VERSION "dbc-export 1 2026.26.6.5"

NS_ :

BS_:

BU_: APP APS BMS CC CMP CMPD CP DAS DI DIF DIR EPBL EPBR EVSE FC GTW HCML HCMR HVP ICR PCS PCS2 PLG PM PMF PMR PTC SCCM SCM SCS SDCR TAS UMC V2G VC VCBATT VCBATT0 VCBATT1 VCBATT2 VCFRONT VCFRONT1 VCFRONT2 VCLEFT VCRIGHT VCSEAT2L VCSEAT2R VCSEC

BO_ 864 VCLEFT_alertMatrix: 8 VCLEFT
 SG_ VCLEFT_matrixIndex M : 0|4@1+ (1,0) [0|15] "" Vector__XXX
 SG_ VCLEFT_a001_WatchdogReset m0 : 4|1@1+ (1,0) [0|1] "" Vector__XXX
 SG_ VCLEFT_a002_PowerLossReset m0 : 5|1@1+ (1,0) [0|1] "" Vector__XXX
 SG_ VCLEFT_a003_SWAssertion m0 : 6|1@1+ (1,0) [0|1] "" Vector__XXX
 SG_ VCLEFT_a005_CANTXError m0 : 8|1@1+ (1,0) [0|1] "" Vector__XXX
 SG_ VCLEFT_a006_CANTX_cyclicError m0 : 9|1@1+ (1,0) [0|1] "" Vector__XXX
 SG_ VCLEFT_a010_ExtSupplyVoltError m0 : 13|1@1+ (1,0) [0|1] "" Vector__XXX
 SG_ VCLEFT_a012_CPUReset m0 : 15|1@1+ (1,0) [0|1] "" Vector__XXX
 SG_ VCLEFT_a013_AlertManagerFault m0 : 16|1@1+ (1,0) [0|1] "" Vector__XXX
 SG_ VCLEFT_a015_NVMMError m0 : 18|1@1+ (1,0) [0|1] "" Vector__XXX
 SG_ VCLEFT_a016_NVMMRecordError m0 : 19|1@1+ (1,0) [0|1] "" Vector__XXX
 SG_ VCLEFT_a017_NVMMStatusDbg m0 : 20|1@1+ (1,0) [0|1] "" Vector__XXX
 SG_ VCLEFT_a021_TaskSchedulerError m0 : 24|1@1+ (1,0) [0|1] "" Vector__XXX
 SG_ VCLEFT_a022_TaskInitError m0 : 25|1@1+ (1,0) [0|1] "" Vector__XXX
 SG_ VCLEFT_a029_CoreDump m0 : 32|1@1+ (1,0) [0|1] "" Vector__XXX
 SG_ VCLEFT_a030_ECULogUploadRequest m0 : 33|1@1+ (1,0) [0|1] "" Vector__XXX
 SG_ VCLEFT_a031_UDSActive m0 : 34|1@1+ (1,0) [0|1] "" Vector__XXX
 SG_ VCLEFT_a041_HighCPULoad m0 : 44|1@1+ (1,0) [0|1] "" Vector__XXX
 SG_ VCLEFT_a042_HighStackUsage m0 : 45|1@1+ (1,0) [0|1] "" Vector__XXX
 SG_ VCLEFT_a043_Task1msError m0 : 46|1@1+ (1,0) [0|1] "" Vector__XXX
 SG_ VCLEFT_a044_Task10msError m0 : 47|1@1+ (1,0) [0|1] "" Vector__XXX
 SG_ VCLEFT_a045_Task100msError m0 : 48|1@1+ (1,0) [0|1] "" Vector__XXX
 SG_ VCLEFT_a046_Task1000msError m0 : 49|1@1+ (1,0) [0|1] "" Vector__XXX
 SG_ VCLEFT_a057_HVP_MIA m0 : 60|1@1+ (1,0) [0|1] "" Vector__XXX
 SG_ VCLEFT_a058_inputRHighSyncDebug m0 : 61|1@1+ (1,0) [0|1] "" Vector__XXX
 SG_ VCLEFT_a059_inputResistanceHigh m0 : 62|1@1+ (1,0) [0|1] "" Vector__XXX
 SG_ VCLEFT_a060_engineeringBuild m0 : 63|1@1+ (1,0) [0|1] "" Vector__XXX
 SG_ VCLEFT_a061_XCPConnected m1 : 4|1@1+ (1,0) [0|1] "" Vector__XXX
 SG_ VCLEFT_a062_XCPWasConnected m1 : 5|1@1+ (1,0) [0|1] "" Vector__XXX
 SG_ VCLEFT_a063_SwitchFault m1 : 6|1@1+ (1,0) [0|1] "" Vector__XXX
 SG_ VCLEFT_a064_busSleepReqTimeout m1 : 7|1@1+ (1,0) [0|1] "" Vector__XXX
 SG_ VCLEFT_a065_emiosIsrRateLimitedD m1 : 8|1@1+ (1,0) [0|1] "" Vector__XXX
 SG_ VCLEFT_a066_emiosIsrShortPeriodD m1 : 9|1@1+ (1,0) [0|1] "" Vector__XXX
 SG_ VCLEFT_a082_VCRIGHT_IPC_MIA m1 : 25|1@1+ (1,0) [0|1] "" Vector__XXX
 SG_ VCLEFT_a083_VCLEFT_IPC_MIA m1 : 26|1@1+ (1,0) [0|1] "" Vector__XXX
 SG_ VCLEFT_a084_TPMS_MIA m1 : 27|1@1+ (1,0) [0|1] "" Vector__XXX
 SG_ VCLEFT_a085_CCCM_MIA m1 : 28|1@1+ (1,0) [0|1] "" Vector__XXX
 SG_ VCLEFT_a086_VCBATT_MIA m1 : 29|1@1+ (1,0) [0|1] "" Vector__XXX
 SG_ VCLEFT_a087_DIREL_MIA m1 : 30|1@1+ (1,0) [0|1] "" Vector__XXX
 SG_ VCLEFT_a088_DIRER_MIA m1 : 31|1@1+ (1,0) [0|1] "" Vector__XXX
 SG_ VCLEFT_a089_IBST_MIA m1 : 32|1@1+ (1,0) [0|1] "" Vector__XXX
 SG_ VCLEFT_a090_APS_MIA m1 : 33|1@1+ (1,0) [0|1] "" Vector__XXX
 SG_ VCLEFT_a091_CMPD_MIA m1 : 34|1@1+ (1,0) [0|1] "" Vector__XXX
 SG_ VCLEFT_a092_VCSEATD_MIA m1 : 35|1@1+ (1,0) [0|1] "" Vector__XXX
 SG_ VCLEFT_a093_VCSEATP_MIA m1 : 36|1@1+ (1,0) [0|1] "" Vector__XXX
 SG_ VCLEFT_a094_EPAS3P_MIA m1 : 37|1@1+ (1,0) [0|1] "" Vector__XXX
 SG_ VCLEFT_a095_CHG_MIA m1 : 38|1@1+ (1,0) [0|1] "" Vector__XXX
 SG_ VCLEFT_a096_OCS1P_MIA m1 : 39|1@1+ (1,0) [0|1] "" Vector__XXX
 SG_ VCLEFT_a097_CMP_MIA m1 : 40|1@1+ (1,0) [0|1] "" Vector__XXX
 SG_ VCLEFT_a098_DIR_MIA m1 : 41|1@1+ (1,0) [0|1] "" Vector__XXX
 SG_ VCLEFT_a099_PARK_MIA m1 : 42|1@1+ (1,0) [0|1] "" Vector__XXX
 SG_ VCLEFT_a100_CANbus_MIA m1 : 43|1@1+ (1,0) [0|1] "" Vector__XXX
 SG_ VCLEFT_a101_PM_MIA m1 : 44|1@1+ (1,0) [0|1] "" Vector__XXX
 SG_ VCLEFT_a102_PTC_MIA m1 : 45|1@1+ (1,0) [0|1] "" Vector__XXX
 SG_ VCLEFT_a103_CP_MIA m1 : 46|1@1+ (1,0) [0|1] "" Vector__XXX
 SG_ VCLEFT_a104_DAS_MIA m1 : 47|1@1+ (1,0) [0|1] "" Vector__XXX
 SG_ VCLEFT_a105_TAS_MIA m1 : 48|1@1+ (1,0) [0|1] "" Vector__XXX
 SG_ VCLEFT_a106_PCS_MIA m1 : 49|1@1+ (1,0) [0|1] "" Vector__XXX
 SG_ VCLEFT_a107_BMS_MIA m1 : 50|1@1+ (1,0) [0|1] "" Vector__XXX
 SG_ VCLEFT_a108_DIF_MIA m1 : 51|1@1+ (1,0) [0|1] "" Vector__XXX
 SG_ VCLEFT_a109_RCM_MIA m1 : 52|1@1+ (1,0) [0|1] "" Vector__XXX
 SG_ VCLEFT_a110_GTW_MIA m1 : 53|1@1+ (1,0) [0|1] "" Vector__XXX
 SG_ VCLEFT_a111_EPBR_MIA m1 : 54|1@1+ (1,0) [0|1] "" Vector__XXX
 SG_ VCLEFT_a112_EPBL_MIA m1 : 55|1@1+ (1,0) [0|1] "" Vector__XXX
 SG_ VCLEFT_a113_UI_MIA m1 : 56|1@1+ (1,0) [0|1] "" Vector__XXX
 SG_ VCLEFT_a114_ESP_MIA m1 : 57|1@1+ (1,0) [0|1] "" Vector__XXX
 SG_ VCLEFT_a115_VCSEC_MIA m1 : 58|1@1+ (1,0) [0|1] "" Vector__XXX
 SG_ VCLEFT_a116_VCRIGHT_MIA m1 : 59|1@1+ (1,0) [0|1] "" Vector__XXX
 SG_ VCLEFT_a117_VCLEFT_MIA m1 : 60|1@1+ (1,0) [0|1] "" Vector__XXX
 SG_ VCLEFT_a118_VCFRONT_MIA m1 : 61|1@1+ (1,0) [0|1] "" Vector__XXX
 SG_ VCLEFT_a119_SCCM_MIA m1 : 62|1@1+ (1,0) [0|1] "" Vector__XXX
 SG_ VCLEFT_a120_DI_DRIVE_MIA m1 : 63|1@1+ (1,0) [0|1] "" Vector__XXX
 SG_ VCLEFT_a121_ETC_MIA m2 : 4|1@1+ (1,0) [0|1] "" Vector__XXX
 SG_ VCLEFT_a122_ICR_MIA m2 : 5|1@1+ (1,0) [0|1] "" Vector__XXX
 SG_ VCLEFT_a123_AID_MIA m2 : 6|1@1+ (1,0) [0|1] "" Vector__XXX
 SG_ VCLEFT_a124_BB_MIA m2 : 7|1@1+ (1,0) [0|1] "" Vector__XXX
 SG_ VCLEFT_a125_RCU_MIA m2 : 8|1@1+ (1,0) [0|1] "" Vector__XXX
 SG_ VCLEFT_a129_blowerICLatchFault m2 : 12|1@1+ (1,0) [0|1] "" Vector__XXX
 SG_ VCLEFT_a130_blowerICWarning m2 : 13|1@1+ (1,0) [0|1] "" Vector__XXX
 SG_ VCLEFT_a131_blowerICTransFault m2 : 14|1@1+ (1,0) [0|1] "" Vector__XXX
 SG_ VCLEFT_a132_blowerSoftStall m2 : 15|1@1+ (1,0) [0|1] "" Vector__XXX
 SG_ VCLEFT_a133_blowerLowRPMCBang m2 : 16|1@1+ (1,0) [0|1] "" Vector__XXX
 SG_ VCLEFT_a134_SteerColUpDownUnCal m2 : 17|1@1+ (1,0) [0|1] "" Vector__XXX
 SG_ VCLEFT_a135_SteerColInOutUnCal m2 : 18|1@1+ (1,0) [0|1] "" Vector__XXX
 SG_ VCLEFT_a136_brakeSwitchMismatch m2 : 19|1@1+ (1,0) [0|1] "" Vector__XXX
 SG_ VCLEFT_a137_VCSECPowerCycled m2 : 20|1@1+ (1,0) [0|1] "" Vector__XXX
 SG_ VCLEFT_a138_consoleDoorAssist m2 : 21|1@1+ (1,0) [0|1] "" Vector__XXX
 SG_ VCLEFT_a139_BLERearPowerCycled m2 : 22|1@1+ (1,0) [0|1] "" Vector__XXX
 SG_ VCLEFT_a140_BLELeftPowerCycled m2 : 23|1@1+ (1,0) [0|1] "" Vector__XXX
 SG_ VCLEFT_a141_12VAuxPowerTrip m2 : 24|1@1+ (1,0) [0|1] "" Vector__XXX
 SG_ VCLEFT_a143_mirrorManuallyFolded m2 : 26|1@1+ (1,0) [0|1] "" Vector__XXX
 SG_ VCLEFT_a145_brakeSwitchStuck m2 : 28|1@1+ (1,0) [0|1] "" Vector__XXX
 SG_ VCLEFT_a148_brakePressInputMisma m2 : 31|1@1+ (1,0) [0|1] "" Vector__XXX
 SG_ VCLEFT_a150_windowPinchFront m2 : 33|1@1+ (1,0) [0|1] "" Vector__XXX
 SG_ VCLEFT_a151_windowPinchRear m2 : 34|1@1+ (1,0) [0|1] "" Vector__XXX
 SG_ VCLEFT_a152_windowUncalFront m2 : 35|1@1+ (1,0) [0|1] "" Vector__XXX
 SG_ VCLEFT_a153_windowUncalRear m2 : 36|1@1+ (1,0) [0|1] "" Vector__XXX
 SG_ VCLEFT_a154_windowThermalFront m2 : 37|1@1+ (1,0) [0|1] "" Vector__XXX
 SG_ VCLEFT_a155_windowThermalRear m2 : 38|1@1+ (1,0) [0|1] "" Vector__XXX
 SG_ VCLEFT_a156_windowNoInputFront m2 : 39|1@1+ (1,0) [0|1] "" Vector__XXX
 SG_ VCLEFT_a157_windowNoInputRear m2 : 40|1@1+ (1,0) [0|1] "" Vector__XXX
 SG_ VCLEFT_a158_windowPinchOverideF m2 : 41|1@1+ (1,0) [0|1] "" Vector__XXX
 SG_ VCLEFT_a159_windowPinchOverideR m2 : 42|1@1+ (1,0) [0|1] "" Vector__XXX
 SG_ VCLEFT_a160_windowUndercurrentF m2 : 43|1@1+ (1,0) [0|1] "" Vector__XXX
 SG_ VCLEFT_a161_windowUndercurrentR m2 : 44|1@1+ (1,0) [0|1] "" Vector__XXX
 SG_ VCLEFT_a162_windowEncoderStallF m2 : 45|1@1+ (1,0) [0|1] "" Vector__XXX
 SG_ VCLEFT_a163_windowEncoderStallR m2 : 46|1@1+ (1,0) [0|1] "" Vector__XXX
 SG_ VCLEFT_a164_windowFactoryTest m2 : 47|1@1+ (1,0) [0|1] "" Vector__XXX
 SG_ VCLEFT_a165_windowFactoryTest2 m2 : 48|1@1+ (1,0) [0|1] "" Vector__XXX
 SG_ VCLEFT_a166_windowDebug m2 : 49|1@1+ (1,0) [0|1] "" Vector__XXX
 SG_ VCLEFT_a167_windowDebugPinchF m2 : 50|1@1+ (1,0) [0|1] "" Vector__XXX
 SG_ VCLEFT_a168_windowDebugPinchR m2 : 51|1@1+ (1,0) [0|1] "" Vector__XXX
 SG_ VCLEFT_a169_windowCurrentPeakF m2 : 52|1@1+ (1,0) [0|1] "" Vector__XXX
 SG_ VCLEFT_a170_windowCurrentPeakR m2 : 53|1@1+ (1,0) [0|1] "" Vector__XXX
 SG_ VCLEFT_a172_SPI_MIA m2 : 55|1@1+ (1,0) [0|1] "" Vector__XXX
 SG_ VCLEFT_a173_windowBtnDoorOpen m2 : 56|1@1+ (1,0) [0|1] "" Vector__XXX
 SG_ VCLEFT_a175_windowSealDefectFron m2 : 58|1@1+ (1,0) [0|1] "" Vector__XXX
 SG_ VCLEFT_a176_windowSealDefectRear m2 : 59|1@1+ (1,0) [0|1] "" Vector__XXX
 SG_ VCLEFT_a180_frontDoorLatchRehome m2 : 63|1@1+ (1,0) [0|1] "" Vector__XXX
 SG_ VCLEFT_a181_rearDoorLatchRehome m3 : 4|1@1+ (1,0) [0|1] "" Vector__XXX
 SG_ VCLEFT_a182_emergencyLatchRel m3 : 5|1@1+ (1,0) [0|1] "" Vector__XXX
 SG_ VCLEFT_a183_doorStateFactoryTest m3 : 6|1@1+ (1,0) [0|1] "" Vector__XXX
 SG_ VCLEFT_a185_summonAborted m3 : 8|1@1+ (1,0) [0|1] "" Vector__XXX
 SG_ VCLEFT_a186_latchReleaseFailedF m3 : 9|1@1+ (1,0) [0|1] "" Vector__XXX
 SG_ VCLEFT_a187_latchReleaseFailedR m3 : 10|1@1+ (1,0) [0|1] "" Vector__XXX
 SG_ VCLEFT_a188_latchUnableToRearmF m3 : 11|1@1+ (1,0) [0|1] "" Vector__XXX
 SG_ VCLEFT_a189_latchUnableToRearmR m3 : 12|1@1+ (1,0) [0|1] "" Vector__XXX
 SG_ VCLEFT_a190_eFuseMgmtVbatFused m3 : 13|1@1+ (1,0) [0|1] "" Vector__XXX
 SG_ VCLEFT_a191_TLCOvercurrent m3 : 14|1@1+ (1,0) [0|1] "" Vector__XXX
 SG_ VCLEFT_a192_blowerGeneralFault m3 : 15|1@1+ (1,0) [0|1] "" Vector__XXX
 SG_ VCLEFT_a193_blowerMIA m3 : 16|1@1+ (1,0) [0|1] "" Vector__XXX
 SG_ VCLEFT_a194_blowerUnidentified m3 : 17|1@1+ (1,0) [0|1] "" Vector__XXX
 SG_ VCLEFT_a195_blowerIdentification m3 : 18|1@1+ (1,0) [0|1] "" Vector__XXX
 SG_ VCLEFT_a196_VEHCANOverterminate m3 : 19|1@1+ (1,0) [0|1] "" Vector__XXX
 SG_ VCLEFT_a197_VEHCANUndertrminate m3 : 20|1@1+ (1,0) [0|1] "" Vector__XXX
 SG_ VCLEFT_a200_motorPhantomEncoder m3 : 23|1@1+ (1,0) [0|1] "" Vector__XXX
 SG_ VCLEFT_a201_motorDutyEncDisabl m3 : 24|1@1+ (1,0) [0|1] "" Vector__XXX
 SG_ VCLEFT_a202_epbmUnderIStatic m3 : 25|1@1+ (1,0) [0|1] "" Vector__XXX
 SG_ VCLEFT_a203_epbmOverIStatic m3 : 26|1@1+ (1,0) [0|1] "" Vector__XXX
 SG_ VCLEFT_a204_epbmUnderIDyn m3 : 27|1@1+ (1,0) [0|1] "" Vector__XXX
 SG_ VCLEFT_a205_epbmOverIDyn m3 : 28|1@1+ (1,0) [0|1] "" Vector__XXX
 SG_ VCLEFT_a206_epbWrongDirection m3 : 29|1@1+ (1,0) [0|1] "" Vector__XXX
 SG_ VCLEFT_a207_epbmEnableWrong m3 : 30|1@1+ (1,0) [0|1] "" Vector__XXX
 SG_ VCLEFT_a208_epbFaulted m3 : 31|1@1+ (1,0) [0|1] "" Vector__XXX
 SG_ VCLEFT_a209_epbStateMisTime m3 : 32|1@1+ (1,0) [0|1] "" Vector__XXX
 SG_ VCLEFT_a210_epbStateTime m3 : 33|1@1+ (1,0) [0|1] "" Vector__XXX
 SG_ VCLEFT_a211_epbmUnderIStaticNew m3 : 34|1@1+ (1,0) [0|1] "" Vector__XXX
 SG_ VCLEFT_a212_epbmOverIStaticNew m3 : 35|1@1+ (1,0) [0|1] "" Vector__XXX
 SG_ VCLEFT_a213_epbmUnderIDynNew m3 : 36|1@1+ (1,0) [0|1] "" Vector__XXX
 SG_ VCLEFT_a214_epbmOverIDynNew m3 : 37|1@1+ (1,0) [0|1] "" Vector__XXX
 SG_ VCLEFT_a215_currentDesyncWarning m3 : 38|1@1+ (1,0) [0|1] "" Vector__XXX
 SG_ VCLEFT_a216_SPI_MIA_debugData1 m3 : 39|1@1+ (1,0) [0|1] "" Vector__XXX
 SG_ VCLEFT_a217_SPI_MIA_debugData2 m3 : 40|1@1+ (1,0) [0|1] "" Vector__XXX
 SG_ VCLEFT_a218_motorDriverFault m3 : 41|1@1+ (1,0) [0|1] "" Vector__XXX
 SG_ VCLEFT_a219_motorCurrentDropout m3 : 42|1@1+ (1,0) [0|1] "" Vector__XXX
 SG_ VCLEFT_a220_reverseLightFaultUse m3 : 43|1@1+ (1,0) [0|1] "" Vector__XXX
 SG_ VCLEFT_a221_hardwareLoadshedTrig m3 : 44|1@1+ (1,0) [0|1] "" Vector__XXX
 SG_ VCLEFT_a223_VCBATT1_MIA m3 : 46|1@1+ (1,0) [0|1] "" Vector__XXX
 SG_ VCLEFT_a224_seatEncStallTrack m3 : 47|1@1+ (1,0) [0|1] "" Vector__XXX
 SG_ VCLEFT_a225_seatEncStallBack m3 : 48|1@1+ (1,0) [0|1] "" Vector__XXX
 SG_ VCLEFT_a226_seatEncStallTilt m3 : 49|1@1+ (1,0) [0|1] "" Vector__XXX
 SG_ VCLEFT_a227_seatEncStallLift m3 : 50|1@1+ (1,0) [0|1] "" Vector__XXX
 SG_ VCLEFT_a228_seatEncOverTrack m3 : 51|1@1+ (1,0) [0|1] "" Vector__XXX
 SG_ VCLEFT_a229_seatEncOverBack m3 : 52|1@1+ (1,0) [0|1] "" Vector__XXX
 SG_ VCLEFT_a230_seatEncOverTilt m3 : 53|1@1+ (1,0) [0|1] "" Vector__XXX
 SG_ VCLEFT_a231_seatEncOverLift m3 : 54|1@1+ (1,0) [0|1] "" Vector__XXX
 SG_ VCLEFT_a232_seatCurrUnderTrack m3 : 55|1@1+ (1,0) [0|1] "" Vector__XXX
 SG_ VCLEFT_a233_seatCurrUnderBack m3 : 56|1@1+ (1,0) [0|1] "" Vector__XXX
 SG_ VCLEFT_a234_seatCurrUnderTilt m3 : 57|1@1+ (1,0) [0|1] "" Vector__XXX
 SG_ VCLEFT_a235_seatCurrUnderLift m3 : 58|1@1+ (1,0) [0|1] "" Vector__XXX
 SG_ VCLEFT_a236_lumbarOverPresA m3 : 59|1@1+ (1,0) [0|1] "" Vector__XXX
 SG_ VCLEFT_a237_lumbarOverPresB m3 : 60|1@1+ (1,0) [0|1] "" Vector__XXX
 SG_ VCLEFT_a238_lumbarValveMIA m3 : 61|1@1+ (1,0) [0|1] "" Vector__XXX
 SG_ VCLEFT_a239_seatHeatIFront m3 : 62|1@1+ (1,0) [0|1] "" Vector__XXX
 SG_ VCLEFT_a240_seatHeatShortFront m3 : 63|1@1+ (1,0) [0|1] "" Vector__XXX
 SG_ VCLEFT_a241_seatHeatMIAFront m4 : 4|1@1+ (1,0) [0|1] "" Vector__XXX
 SG_ VCLEFT_a242_seatHeatIRearL m4 : 5|1@1+ (1,0) [0|1] "" Vector__XXX
 SG_ VCLEFT_a243_seatHeatShortRearL m4 : 6|1@1+ (1,0) [0|1] "" Vector__XXX
 SG_ VCLEFT_a244_seatHeatMIARearL m4 : 7|1@1+ (1,0) [0|1] "" Vector__XXX
 SG_ VCLEFT_a245_seatHeatIRearC m4 : 8|1@1+ (1,0) [0|1] "" Vector__XXX
 SG_ VCLEFT_a246_seatHeatShortRearC m4 : 9|1@1+ (1,0) [0|1] "" Vector__XXX
 SG_ VCLEFT_a247_seatHeatMIARearC m4 : 10|1@1+ (1,0) [0|1] "" Vector__XXX
 SG_ VCLEFT_a248_seatHeatIRearR m4 : 11|1@1+ (1,0) [0|1] "" Vector__XXX
 SG_ VCLEFT_a249_seatHeatShortRearR m4 : 12|1@1+ (1,0) [0|1] "" Vector__XXX
 SG_ VCLEFT_a250_seatHeatMIARearR m4 : 13|1@1+ (1,0) [0|1] "" Vector__XXX
 SG_ VCLEFT_a251_seatUncalTrack m4 : 14|1@1+ (1,0) [0|1] "" Vector__XXX
 SG_ VCLEFT_a252_seatUncalBack m4 : 15|1@1+ (1,0) [0|1] "" Vector__XXX
 SG_ VCLEFT_a253_seatUncalTilt m4 : 16|1@1+ (1,0) [0|1] "" Vector__XXX
 SG_ VCLEFT_a254_seatUncalLift m4 : 17|1@1+ (1,0) [0|1] "" Vector__XXX
 SG_ VCLEFT_a256_nxppca9539Fault m4 : 19|1@1+ (1,0) [0|1] "" Vector__XXX
 SG_ VCLEFT_a257_USBMIA m4 : 20|1@1+ (1,0) [0|1] "" Vector__XXX
 SG_ VCLEFT_a259_latchDisarmDelayF m4 : 22|1@1+ (1,0) [0|1] "" Vector__XXX
 SG_ VCLEFT_a260_latchDisarmDelayR m4 : 23|1@1+ (1,0) [0|1] "" Vector__XXX
 SG_ VCLEFT_a261_emergencyLatchRelRea m4 : 24|1@1+ (1,0) [0|1] "" Vector__XXX
 SG_ VCLEFT_a263_seatTrackStallDebug m4 : 26|1@1+ (1,0) [0|1] "" Vector__XXX
 SG_ VCLEFT_a264_seatBackStallDebug m4 : 27|1@1+ (1,0) [0|1] "" Vector__XXX
 SG_ VCLEFT_a265_seatTiltStallDebug m4 : 28|1@1+ (1,0) [0|1] "" Vector__XXX
 SG_ VCLEFT_a266_seatLiftStallDebug m4 : 29|1@1+ (1,0) [0|1] "" Vector__XXX
 SG_ VCLEFT_a267_seatTrackHCEncStlDbg m4 : 30|1@1+ (1,0) [0|1] "" Vector__XXX
 SG_ VCLEFT_a268_seatBackHCEncStlDbg m4 : 31|1@1+ (1,0) [0|1] "" Vector__XXX
 SG_ VCLEFT_a269_seatTiltHCEncStlDbg m4 : 32|1@1+ (1,0) [0|1] "" Vector__XXX
 SG_ VCLEFT_a270_seatLiftHCEncStlDbg m4 : 33|1@1+ (1,0) [0|1] "" Vector__XXX
 SG_ VCLEFT_a272_vhclPwrStateMsmtch m4 : 35|1@1+ (1,0) [0|1] "" Vector__XXX
 SG_ VCLEFT_a273_handleStuckActiveF m4 : 36|1@1+ (1,0) [0|1] "" Vector__XXX
 SG_ VCLEFT_a274_handleStuckActiveR m4 : 37|1@1+ (1,0) [0|1] "" Vector__XXX
 SG_ VCLEFT_a275_leftTurnLightFault m4 : 38|1@1+ (1,0) [0|1] "" Vector__XXX
 SG_ VCLEFT_a276_mirrorDebug m4 : 39|1@1+ (1,0) [0|1] "" Vector__XXX
 SG_ VCLEFT_a277_BLELeftUnderVoltage m4 : 40|1@1+ (1,0) [0|1] "" Vector__XXX
 SG_ VCLEFT_a278_BLERearUnderVoltage m4 : 41|1@1+ (1,0) [0|1] "" Vector__XXX
 SG_ VCLEFT_a279_VCSECUnderVoltage m4 : 42|1@1+ (1,0) [0|1] "" Vector__XXX
 SG_ VCLEFT_a280_latchDidNotDisarmF m4 : 43|1@1+ (1,0) [0|1] "" Vector__XXX
 SG_ VCLEFT_a281_latchDidNotDisarmR m4 : 44|1@1+ (1,0) [0|1] "" Vector__XXX
 SG_ VCLEFT_a282_latchUnexpectedArmF m4 : 45|1@1+ (1,0) [0|1] "" Vector__XXX
 SG_ VCLEFT_a283_latchUnexpectedArmR m4 : 46|1@1+ (1,0) [0|1] "" Vector__XXX
 SG_ VCLEFT_a284_blowerFbkSanity m4 : 47|1@1+ (1,0) [0|1] "" Vector__XXX
 SG_ VCLEFT_a285_blowerChipComms m4 : 48|1@1+ (1,0) [0|1] "" Vector__XXX
 SG_ VCLEFT_a286_windowSpeedInvalidF m4 : 49|1@1+ (1,0) [0|1] "" Vector__XXX
 SG_ VCLEFT_a287_windowSpeedInvalidR m4 : 50|1@1+ (1,0) [0|1] "" Vector__XXX
 SG_ VCLEFT_a288_handlePWMPeriodF m4 : 51|1@1+ (1,0) [0|1] "" Vector__XXX
 SG_ VCLEFT_a289_handlePWMPeriodR m4 : 52|1@1+ (1,0) [0|1] "" Vector__XXX
 SG_ VCLEFT_a290_occupancyFaultedFron m4 : 53|1@1+ (1,0) [0|1] "" Vector__XXX
 SG_ VCLEFT_a291_buckleFaultedFront m4 : 54|1@1+ (1,0) [0|1] "" Vector__XXX
 SG_ VCLEFT_a292_occupancyFaultedRear m4 : 55|1@1+ (1,0) [0|1] "" Vector__XXX
 SG_ VCLEFT_a293_occupancyFaultedRear m4 : 56|1@1+ (1,0) [0|1] "" Vector__XXX
 SG_ VCLEFT_a294_occupancyFaultedRear m4 : 57|1@1+ (1,0) [0|1] "" Vector__XXX
 SG_ VCLEFT_a295_buckleFaultedRearL m4 : 58|1@1+ (1,0) [0|1] "" Vector__XXX
 SG_ VCLEFT_a296_buckleFaultedRearC m4 : 59|1@1+ (1,0) [0|1] "" Vector__XXX
 SG_ VCLEFT_a297_seatBelowMinPumpTmp m4 : 60|1@1+ (1,0) [0|1] "" Vector__XXX
 SG_ VCLEFT_a299_swcMIA m4 : 62|1@1+ (1,0) [0|1] "" Vector__XXX
 SG_ VCLEFT_a300_swcUnderVoltage m4 : 63|1@1+ (1,0) [0|1] "" Vector__XXX
 SG_ VCLEFT_a301_swcOverVoltage m5 : 4|1@1+ (1,0) [0|1] "" Vector__XXX
 SG_ VCLEFT_a302_blowerGeneralFault m5 : 5|1@1+ (1,0) [0|1] "" Vector__XXX
 SG_ VCLEFT_a303_eFuseMgmtWindowLift m5 : 6|1@1+ (1,0) [0|1] "" Vector__XXX
 SG_ VCLEFT_a304_frontIntHandleUnexpe m5 : 7|1@1+ (1,0) [0|1] "" Vector__XXX
 SG_ VCLEFT_a305_rearIntHandleUnexpec m5 : 8|1@1+ (1,0) [0|1] "" Vector__XXX
 SG_ VCLEFT_a306_handleDisconnectedF m5 : 9|1@1+ (1,0) [0|1] "" Vector__XXX
 SG_ VCLEFT_a307_handleDisconnectedR m5 : 10|1@1+ (1,0) [0|1] "" Vector__XXX
 SG_ VCLEFT_a308_sirenMIA m5 : 11|1@1+ (1,0) [0|1] "" Vector__XXX
 SG_ VCLEFT_a309_brakeSwitchFaulted m5 : 12|1@1+ (1,0) [0|1] "" Vector__XXX
 SG_ VCLEFT_a310_mirrorFoldStall m5 : 13|1@1+ (1,0) [0|1] "" Vector__XXX
 SG_ VCLEFT_a311_leftBrakeLightFault m5 : 14|1@1+ (1,0) [0|1] "" Vector__XXX
 SG_ VCLEFT_a312_leftTailLightFault m5 : 15|1@1+ (1,0) [0|1] "" Vector__XXX
 SG_ VCLEFT_a313_leftFootwellLightFau m5 : 16|1@1+ (1,0) [0|1] "" Vector__XXX
 SG_ VCLEFT_a314_leftMapPocketLightFa m5 : 17|1@1+ (1,0) [0|1] "" Vector__XXX
 SG_ VCLEFT_a315_leftInteriorTrunkLig m5 : 18|1@1+ (1,0) [0|1] "" Vector__XXX
 SG_ VCLEFT_a316_mirrorPrematureFoldS m5 : 19|1@1+ (1,0) [0|1] "" Vector__XXX
 SG_ VCLEFT_a317_epbmLimpModeEnabled m5 : 20|1@1+ (1,0) [0|1] "" Vector__XXX
 SG_ VCLEFT_a318_trailerIncorrectConf m5 : 21|1@1+ (1,0) [0|1] "" Vector__XXX
 SG_ VCLEFT_a319_brakePressPrimaryInp m5 : 22|1@1+ (1,0) [0|1] "" Vector__XXX
 SG_ VCLEFT_a320_windowReportCrackedA m5 : 23|1@1+ (1,0) [0|1] "" Vector__XXX
 SG_ VCLEFT_a321_windowRezeroedDebugF m5 : 24|1@1+ (1,0) [0|1] "" Vector__XXX
 SG_ VCLEFT_a322_windowRezeroedDebugR m5 : 25|1@1+ (1,0) [0|1] "" Vector__XXX
 SG_ VCLEFT_a323_mirrorCalibrated m5 : 26|1@1+ (1,0) [0|1] "" Vector__XXX
 SG_ VCLEFT_a324_mirrorHeatFault m5 : 27|1@1+ (1,0) [0|1] "" Vector__XXX
 SG_ VCLEFT_a325_hghtSnsrUnplgdFL m5 : 28|1@1+ (1,0) [0|1] "" Vector__XXX
 SG_ VCLEFT_a326_hghtSnsrUnplgdRL m5 : 29|1@1+ (1,0) [0|1] "" Vector__XXX
 SG_ VCLEFT_a327_hghtSnsrFaultFL m5 : 30|1@1+ (1,0) [0|1] "" Vector__XXX
 SG_ VCLEFT_a328_hghtSnsrFaultRL m5 : 31|1@1+ (1,0) [0|1] "" Vector__XXX
 SG_ VCLEFT_a329_noRideHeightCalib m5 : 32|1@1+ (1,0) [0|1] "" Vector__XXX
 SG_ VCLEFT_a330_shortDropFailedF m5 : 33|1@1+ (1,0) [0|1] "" Vector__XXX
 SG_ VCLEFT_a331_shortDropFailedR m5 : 34|1@1+ (1,0) [0|1] "" Vector__XXX
 SG_ VCLEFT_a332_intrusionSensorMIA m5 : 35|1@1+ (1,0) [0|1] "" Vector__XXX
 SG_ VCLEFT_a333_overheadConsoleMIA m5 : 36|1@1+ (1,0) [0|1] "" Vector__XXX
 SG_ VCLEFT_a334_overheadConsoleInter m5 : 37|1@1+ (1,0) [0|1] "" Vector__XXX
 SG_ VCLEFT_a335_intrusionSensorInter m5 : 38|1@1+ (1,0) [0|1] "" Vector__XXX
 SG_ VCLEFT_a336_windowDropRevThermal m5 : 39|1@1+ (1,0) [0|1] "" Vector__XXX
 SG_ VCLEFT_a337_windowDropRevThermal m5 : 40|1@1+ (1,0) [0|1] "" Vector__XXX
 SG_ VCLEFT_a338_trailerLightControll m5 : 41|1@1+ (1,0) [0|1] "" Vector__XXX
 SG_ VCLEFT_a339_trailerLeftTurnLight m5 : 42|1@1+ (1,0) [0|1] "" Vector__XXX
 SG_ VCLEFT_a340_trailerRightTurnLigh m5 : 43|1@1+ (1,0) [0|1] "" Vector__XXX
 SG_ VCLEFT_a341_trailerLightFault m5 : 44|1@1+ (1,0) [0|1] "" Vector__XXX
 SG_ VCLEFT_a342_trailerLightControll m5 : 45|1@1+ (1,0) [0|1] "" Vector__XXX
 SG_ VCLEFT_a345_chargePortPowerCycli m5 : 48|1@1+ (1,0) [0|1] "" Vector__XXX
 SG_ VCLEFT_a346_eFuseMgmtVbatFused2 m5 : 49|1@1+ (1,0) [0|1] "" Vector__XXX
 SG_ VCLEFT_a347_nonContMonitorCleare m5 : 50|1@1+ (1,0) [0|1] "" Vector__XXX
 SG_ VCLEFT_a348_CPSleepOvercurrent m5 : 51|1@1+ (1,0) [0|1] "" Vector__XXX
 SG_ VCLEFT_a349_CPSleepUndervoltage m5 : 52|1@1+ (1,0) [0|1] "" Vector__XXX
 SG_ VCLEFT_a350_ensOutOfRange m5 : 53|1@1+ (1,0) [0|1] "" Vector__XXX
 SG_ VCLEFT_a351_debugLiftgateCurrent m5 : 54|1@1+ (1,0) [0|1] "" Vector__XXX
 SG_ VCLEFT_a352_liftgateClosingLatch m5 : 55|1@1+ (1,0) [0|1] "" Vector__XXX
 SG_ VCLEFT_a353_eFuseMgmtSteeringCol m5 : 56|1@1+ (1,0) [0|1] "" Vector__XXX
 SG_ VCLEFT_a354_eFuseMgmtLiftGate m5 : 57|1@1+ (1,0) [0|1] "" Vector__XXX
 SG_ VCLEFT_a355_liftgateUnexpectedSt m5 : 58|1@1+ (1,0) [0|1] "" Vector__XXX
 SG_ VCLEFT_a356_liftgateFactoryTest m5 : 59|1@1+ (1,0) [0|1] "" Vector__XXX
 SG_ VCLEFT_a357_liftgateUncalibrated m5 : 60|1@1+ (1,0) [0|1] "" Vector__XXX
 SG_ VCLEFT_a358_debugLiftgateCurrent m5 : 61|1@1+ (1,0) [0|1] "" Vector__XXX
 SG_ VCLEFT_a359_liftgateLatchExitNoP m5 : 62|1@1+ (1,0) [0|1] "" Vector__XXX
 SG_ VCLEFT_a360_detectedStationaryWh m5 : 63|1@1+ (1,0) [0|1] "" Vector__XXX
 SG_ VCLEFT_a361_stationaryThresholds m6 : 4|1@1+ (1,0) [0|1] "" Vector__XXX
 SG_ VCLEFT_a362_movingThresholdsInco m6 : 5|1@1+ (1,0) [0|1] "" Vector__XXX
 SG_ VCLEFT_a363_liftgateOpenAngleSet m6 : 6|1@1+ (1,0) [0|1] "" Vector__XXX
 SG_ VCLEFT_a365_pitchUnlatchDisabled m6 : 8|1@1+ (1,0) [0|1] "" Vector__XXX
 SG_ VCLEFT_a366_liftgateLatchEntryDB m6 : 9|1@1+ (1,0) [0|1] "" Vector__XXX
 SG_ VCLEFT_a370_seat2RowPitchUnlatch m6 : 13|1@1+ (1,0) [0|1] "" Vector__XXX
 SG_ VCLEFT_a371_seat2RowTrackUnlatch m6 : 14|1@1+ (1,0) [0|1] "" Vector__XXX
 SG_ VCLEFT_a372_seat2RowBackrestUnla m6 : 15|1@1+ (1,0) [0|1] "" Vector__XXX
 SG_ VCLEFT_a373_windowSwOpenReqInDog m6 : 16|1@1+ (1,0) [0|1] "" Vector__XXX
 SG_ VCLEFT_a374_trailerLightFaultMod m6 : 17|1@1+ (1,0) [0|1] "" Vector__XXX
 SG_ VCLEFT_a375_windowPinchOverrideN m6 : 18|1@1+ (1,0) [0|1] "" Vector__XXX
 SG_ VCLEFT_a376_seat2RowBridgeCurren m6 : 19|1@1+ (1,0) [0|1] "" Vector__XXX
 SG_ VCLEFT_a380_steerColThermalLimit m6 : 23|1@1+ (1,0) [0|1] "" Vector__XXX
 SG_ VCLEFT_a381_pitchEstimation1 m6 : 24|1@1+ (1,0) [0|1] "" Vector__XXX
 SG_ VCLEFT_a382_pitchEstimation2 m6 : 25|1@1+ (1,0) [0|1] "" Vector__XXX
 SG_ VCLEFT_a383_steerColInOutMotorSt m6 : 26|1@1+ (1,0) [0|1] "" Vector__XXX
 SG_ VCLEFT_a384_steerColUpDownMotorS m6 : 27|1@1+ (1,0) [0|1] "" Vector__XXX
 SG_ VCLEFT_a385_steerColInOutMotorUn m6 : 28|1@1+ (1,0) [0|1] "" Vector__XXX
 SG_ VCLEFT_a386_steerColUpDownMotorU m6 : 29|1@1+ (1,0) [0|1] "" Vector__XXX
 SG_ VCLEFT_a387_steerColInOutMotorEn m6 : 30|1@1+ (1,0) [0|1] "" Vector__XXX
 SG_ VCLEFT_a388_steerColUpDownMotorE m6 : 31|1@1+ (1,0) [0|1] "" Vector__XXX
 SG_ VCLEFT_a389_steerColInOutEncoder m6 : 32|1@1+ (1,0) [0|1] "" Vector__XXX
 SG_ VCLEFT_a390_steerColUpDownEncode m6 : 33|1@1+ (1,0) [0|1] "" Vector__XXX
 SG_ VCLEFT_a391_pitchEstimationImpla m6 : 34|1@1+ (1,0) [0|1] "" Vector__XXX
 SG_ VCLEFT_a392_pitchEstimationGPSIm m6 : 35|1@1+ (1,0) [0|1] "" Vector__XXX
 SG_ VCLEFT_a393_pitchEstimationNoGPS m6 : 36|1@1+ (1,0) [0|1] "" Vector__XXX
 SG_ VCLEFT_a394_swsTouchTooNegativeD m6 : 37|1@1+ (1,0) [0|1] "" Vector__XXX
 SG_ VCLEFT_a395_swsTouchAdcCheckFail m6 : 38|1@1+ (1,0) [0|1] "" Vector__XXX
 SG_ VCLEFT_a396_swsTouchStuckFault m6 : 39|1@1+ (1,0) [0|1] "" Vector__XXX
 SG_ VCLEFT_a397_swsTouchOutOfRangeFa m6 : 40|1@1+ (1,0) [0|1] "" Vector__XXX
 SG_ VCLEFT_a398_swsTouchNvmFault m6 : 41|1@1+ (1,0) [0|1] "" Vector__XXX
 SG_ VCLEFT_a399_swsTouchNoisyBaselin m6 : 42|1@1+ (1,0) [0|1] "" Vector__XXX
 SG_ VCLEFT_a400_swsTouchDebouncedPro m6 : 43|1@1+ (1,0) [0|1] "" Vector__XXX
 SG_ VCLEFT_a401_swsForceTestPatternV m6 : 44|1@1+ (1,0) [0|1] "" Vector__XXX
 SG_ VCLEFT_a402_swsForceOutOfRange m6 : 45|1@1+ (1,0) [0|1] "" Vector__XXX
 SG_ VCLEFT_a403_swsForceAdcCheckFail m6 : 46|1@1+ (1,0) [0|1] "" Vector__XXX
 SG_ VCLEFT_a404_swsForceI2cError m6 : 47|1@1+ (1,0) [0|1] "" Vector__XXX
 SG_ VCLEFT_a405_swsForceCalibrationF m6 : 48|1@1+ (1,0) [0|1] "" Vector__XXX
 SG_ VCLEFT_a406_swsForceParametersFa m6 : 49|1@1+ (1,0) [0|1] "" Vector__XXX
 SG_ VCLEFT_a407_swsForceNvmFault m6 : 50|1@1+ (1,0) [0|1] "" Vector__XXX
 SG_ VCLEFT_a408_swsForceTouchSensorF m6 : 51|1@1+ (1,0) [0|1] "" Vector__XXX
 SG_ VCLEFT_a409_swsScrollWheelPushFa m6 : 52|1@1+ (1,0) [0|1] "" Vector__XXX
 SG_ VCLEFT_a410_swsScrollWheelTiltFa m6 : 53|1@1+ (1,0) [0|1] "" Vector__XXX
 SG_ VCLEFT_a411_swsScrollWheelScroll m6 : 54|1@1+ (1,0) [0|1] "" Vector__XXX
 SG_ VCLEFT_a412_leftBrakeTailLightFa m6 : 55|1@1+ (1,0) [0|1] "" Vector__XXX
 SG_ VCLEFT_a413_undervoltageSelfTest m6 : 56|1@1+ (1,0) [0|1] "" Vector__XXX
 SG_ VCLEFT_a414_swsHapticMotorFault m6 : 57|1@1+ (1,0) [0|1] "" Vector__XXX
 SG_ VCLEFT_a415_swsMiscFault m6 : 58|1@1+ (1,0) [0|1] "" Vector__XXX
 SG_ VCLEFT_a416_fohmTouchAdcCheckFai m6 : 59|1@1+ (1,0) [0|1] "" Vector__XXX
 SG_ VCLEFT_a417_fohmTouchOutOfRangeF m6 : 60|1@1+ (1,0) [0|1] "" Vector__XXX
 SG_ VCLEFT_a418_fohmTouchVarianceFai m6 : 61|1@1+ (1,0) [0|1] "" Vector__XXX
 SG_ VCLEFT_a419_fohmTouchStuck m6 : 62|1@1+ (1,0) [0|1] "" Vector__XXX
 SG_ VCLEFT_a420_fohmTouchSensorsImpl m6 : 63|1@1+ (1,0) [0|1] "" Vector__XXX
 SG_ VCLEFT_a421_fohmForceOutOfRangeF m7 : 4|1@1+ (1,0) [0|1] "" Vector__XXX
 SG_ VCLEFT_a422_undervoltageSelfTest m7 : 5|1@1+ (1,0) [0|1] "" Vector__XXX
 SG_ VCLEFT_a423_fohmForceI2cError m7 : 6|1@1+ (1,0) [0|1] "" Vector__XXX
 SG_ VCLEFT_a424_fohmAmberLEDFault m7 : 7|1@1+ (1,0) [0|1] "" Vector__XXX
 SG_ VCLEFT_a425_fohmVanityPowerSuppl m7 : 8|1@1+ (1,0) [0|1] "" Vector__XXX
 SG_ VCLEFT_a426_seatAbuseMotorWarn m7 : 9|1@1+ (1,0) [0|1] "" Vector__XXX
 SG_ VCLEFT_a427_seatAbuseMotorStop m7 : 10|1@1+ (1,0) [0|1] "" Vector__XXX
 SG_ VCLEFT_a428_seatAbuseBufferWarn m7 : 11|1@1+ (1,0) [0|1] "" Vector__XXX
 SG_ VCLEFT_a429_seatAbuseBufferFull m7 : 12|1@1+ (1,0) [0|1] "" Vector__XXX
 SG_ VCLEFT_a430_fohmRearDomeLightPow m7 : 13|1@1+ (1,0) [0|1] "" Vector__XXX
 SG_ VCLEFT_a431_fohmVbatFault m7 : 14|1@1+ (1,0) [0|1] "" Vector__XXX
 SG_ VCLEFT_a432_fohmMiscFault m7 : 15|1@1+ (1,0) [0|1] "" Vector__XXX
 SG_ VCLEFT_a433_fohmForceCalibration m7 : 16|1@1+ (1,0) [0|1] "" Vector__XXX
 SG_ VCLEFT_a434_swsScrollWheelPushDa m7 : 17|1@1+ (1,0) [0|1] "" Vector__XXX
 SG_ VCLEFT_a435_swsNoReasonTouchFaul m7 : 18|1@1+ (1,0) [0|1] "" Vector__XXX
 SG_ VCLEFT_a436_swsNoReasonForceFaul m7 : 19|1@1+ (1,0) [0|1] "" Vector__XXX
 SG_ VCLEFT_a437_hvacRearLeftVertical m7 : 20|1@1+ (1,0) [0|1] "" Vector__XXX
 SG_ VCLEFT_a438_hvacRearLeftLateralD m7 : 21|1@1+ (1,0) [0|1] "" Vector__XXX
 SG_ VCLEFT_a439_hvacRearRightVertica m7 : 22|1@1+ (1,0) [0|1] "" Vector__XXX
 SG_ VCLEFT_a440_hvacRearRightLateral m7 : 23|1@1+ (1,0) [0|1] "" Vector__XXX
 SG_ VCLEFT_a441_prndMIA m7 : 24|1@1+ (1,0) [0|1] "" Vector__XXX
 SG_ VCLEFT_a442_swsLongTouchEvent m7 : 25|1@1+ (1,0) [0|1] "" Vector__XXX
 SG_ VCLEFT_a444_drv8703Fault m7 : 27|1@1+ (1,0) [0|1] "" Vector__XXX
 SG_ VCLEFT_a445_drv8703SpiFaultDBG m7 : 28|1@1+ (1,0) [0|1] "" Vector__XXX
 SG_ VCLEFT_a446_trailerAuxReversePow m7 : 29|1@1+ (1,0) [0|1] "" Vector__XXX
 SG_ VCLEFT_a447_steeringColInOutEnds m7 : 30|1@1+ (1,0) [0|1] "" Vector__XXX
 SG_ VCLEFT_a448_steeringColUpDownEnd m7 : 31|1@1+ (1,0) [0|1] "" Vector__XXX
 SG_ VCLEFT_a449_steerColInOutMotorSh m7 : 32|1@1+ (1,0) [0|1] "" Vector__XXX
 SG_ VCLEFT_a450_steerColUpDownMotorS m7 : 33|1@1+ (1,0) [0|1] "" Vector__XXX
 SG_ VCLEFT_a451_wirelessChargerMIA m7 : 34|1@1+ (1,0) [0|1] "" Vector__XXX
 SG_ VCLEFT_a453_liftgatePinchDetecte m7 : 36|1@1+ (1,0) [0|1] "" Vector__XXX
 SG_ VCLEFT_a454_wirelessChargerFault m7 : 37|1@1+ (1,0) [0|1] "" Vector__XXX
 SG_ VCLEFT_a455_liftgateUnexpectedSh m7 : 38|1@1+ (1,0) [0|1] "" Vector__XXX
 SG_ VCLEFT_a460_etcDebug m7 : 43|1@1+ (1,0) [0|1] "" Vector__XXX
 SG_ VCLEFT_a466_hvac2RLeftAirwaveVer m7 : 49|1@1+ (1,0) [0|1] "" Vector__XXX
 SG_ VCLEFT_a467_hvac2RLeftAirwaveVer m7 : 50|1@1+ (1,0) [0|1] "" Vector__XXX
 SG_ VCLEFT_a468_hvac2RLeftAirwaveVer m7 : 51|1@1+ (1,0) [0|1] "" Vector__XXX
 SG_ VCLEFT_a469_hvac2RLeftAirwaveLat m7 : 52|1@1+ (1,0) [0|1] "" Vector__XXX
 SG_ VCLEFT_a470_hvac2RLeftAirwaveLat m7 : 53|1@1+ (1,0) [0|1] "" Vector__XXX
 SG_ VCLEFT_a471_hvac2RLeftAirwaveLat m7 : 54|1@1+ (1,0) [0|1] "" Vector__XXX
 SG_ VCLEFT_a472_hvac2RRightAirwaveVe m7 : 55|1@1+ (1,0) [0|1] "" Vector__XXX
 SG_ VCLEFT_a473_hvac2RRightAirwaveVe m7 : 56|1@1+ (1,0) [0|1] "" Vector__XXX
 SG_ VCLEFT_a474_hvac2RRightAirwaveVe m7 : 57|1@1+ (1,0) [0|1] "" Vector__XXX
 SG_ VCLEFT_a475_hvac2RRightAirwaveLa m7 : 58|1@1+ (1,0) [0|1] "" Vector__XXX
 SG_ VCLEFT_a476_hvac2RRightAirwaveLa m7 : 59|1@1+ (1,0) [0|1] "" Vector__XXX
 SG_ VCLEFT_a477_hvac2RRightAirwaveLa m7 : 60|1@1+ (1,0) [0|1] "" Vector__XXX
 SG_ VCLEFT_a478_BPillarCameraHeaterF m7 : 61|1@1+ (1,0) [0|1] "" Vector__XXX
 SG_ VCLEFT_a480_vnf1048Fault m7 : 63|1@1+ (1,0) [0|1] "" Vector__XXX
 SG_ VCLEFT_a481_vnf1048SelfTestFailu m8 : 4|1@1+ (1,0) [0|1] "" Vector__XXX
 SG_ VCLEFT_a482_NCV77XXFault m8 : 5|1@1+ (1,0) [0|1] "" Vector__XXX
 SG_ VCLEFT_a483_leftTurnLightFaultUs m8 : 6|1@1+ (1,0) [0|1] "" Vector__XXX
 SG_ VCLEFT_a484_leftBrakeLightFaultU m8 : 7|1@1+ (1,0) [0|1] "" Vector__XXX
 SG_ VCLEFT_a485_uvSelfTestLoadUnatte m8 : 8|1@1+ (1,0) [0|1] "" Vector__XXX
 SG_ VCLEFT_a488_undervoltageSelfTest m8 : 11|1@1+ (1,0) [0|1] "" Vector__XXX
 SG_ VCLEFT_a489_undervoltageSelfTest m8 : 12|1@1+ (1,0) [0|1] "" Vector__XXX
 SG_ VCLEFT_a490_vehicleOccupiedOnOTA m8 : 13|1@1+ (1,0) [0|1] "" Vector__XXX
 SG_ VCLEFT_a493_12vSocketFrontEFuseT m8 : 16|1@1+ (1,0) [0|1] "" Vector__XXX
 SG_ VCLEFT_a494_12vSocketRearEFuseTr m8 : 17|1@1+ (1,0) [0|1] "" Vector__XXX
 SG_ VCLEFT_a497_CANMsgMACVerificatio m8 : 20|1@1+ (1,0) [0|1] "" Vector__XXX
 SG_ VCLEFT_a498_CANMsgMACVerificatio m8 : 21|1@1+ (1,0) [0|1] "" Vector__XXX
 SG_ VCLEFT_a499_epbmInvalidateCdp m8 : 22|1@1+ (1,0) [0|1] "" Vector__XXX
 SG_ VCLEFT_a500_eFuseASICStateMismat m8 : 23|1@1+ (1,0) [0|1] "" Vector__XXX
 SG_ VCLEFT_a501_vnf1048Configuration m8 : 24|1@1+ (1,0) [0|1] "" Vector__XXX
 SG_ VCLEFT_a510_3RowSeatUncalibrated m8 : 33|1@1+ (1,0) [0|1] "" Vector__XXX
 SG_ VCLEFT_a511_3RowSeatPositionNons m8 : 34|1@1+ (1,0) [0|1] "" Vector__XXX
 SG_ VCLEFT_a512_3RowSeatAbsPosOffset m8 : 35|1@1+ (1,0) [0|1] "" Vector__XXX
 SG_ VCLEFT_a513_3RowSeatObstacleDete m8 : 36|1@1+ (1,0) [0|1] "" Vector__XXX
 SG_ VCLEFT_a514_3RowSeatTempHigh m8 : 37|1@1+ (1,0) [0|1] "" Vector__XXX
 SG_ VCLEFT_a515_3RowSeatAbsPosSensor m8 : 38|1@1+ (1,0) [0|1] "" Vector__XXX
 SG_ VCLEFT_a516_3RowSeatStatsFromLas m8 : 39|1@1+ (1,0) [0|1] "" Vector__XXX
 SG_ VCLEFT_a517_3RowSeatRequestWhile m8 : 40|1@1+ (1,0) [0|1] "" Vector__XXX
 SG_ VCLEFT_a518_3RowSeatClashAvoidan m8 : 41|1@1+ (1,0) [0|1] "" Vector__XXX
 SG_ VCLEFT_a519_3RowSeatOverfolded m8 : 42|1@1+ (1,0) [0|1] "" Vector__XXX
 SG_ VCLEFT_a520_configMismatch m8 : 43|1@1+ (1,0) [0|1] "" Vector__XXX
 SG_ VCLEFT_a521_seatHeatPadUnexpecte m8 : 44|1@1+ (1,0) [0|1] "" Vector__XXX
 SG_ VCLEFT_a522_trailerLightUnexpect m8 : 45|1@1+ (1,0) [0|1] "" Vector__XXX
 SG_ VCLEFT_a523_eFuseThresholdsIncor m8 : 46|1@1+ (1,0) [0|1] "" Vector__XXX
 SG_ VCLEFT_a525_LVBatterySWMisconfig m8 : 48|1@1+ (1,0) [0|1] "" Vector__XXX
 SG_ VCLEFT_a526_pcbaOverTemperature m8 : 49|1@1+ (1,0) [0|1] "" Vector__XXX
 SG_ VCLEFT_a527_continuousFeedUnexpe m8 : 50|1@1+ (1,0) [0|1] "" Vector__XXX
 SG_ VCLEFT_a528_unableToRunStuckOnTe m8 : 51|1@1+ (1,0) [0|1] "" Vector__XXX
 SG_ VCLEFT_a536_trunkFoldFlatSwitchF m8 : 59|1@1+ (1,0) [0|1] "" Vector__XXX
 SG_ VCLEFT_a545_LVBatteryTypeUnknown m9 : 8|1@1+ (1,0) [0|1] "" Vector__XXX
 SG_ VCLEFT_a546_mirrorFoldTypeChange m9 : 9|1@1+ (1,0) [0|1] "" Vector__XXX
 SG_ VCLEFT_a550_ambientTempDelta m9 : 13|1@1+ (1,0) [0|1] "" Vector__XXX
 SG_ VCLEFT_a551_interiorDoorRequestI m9 : 14|1@1+ (1,0) [0|1] "" Vector__XXX
 SG_ VCLEFT_a554_RCM2_MIA m9 : 17|1@1+ (1,0) [0|1] "" Vector__XXX
 SG_ VCLEFT_a555_steeringWheelHeaterC m9 : 18|1@1+ (1,0) [0|1] "" Vector__XXX
 SG_ VCLEFT_a560_2RowSeatUncalibrated m9 : 23|1@1+ (1,0) [0|1] "" Vector__XXX
 SG_ VCLEFT_a561_2RowSeatPositionNons m9 : 24|1@1+ (1,0) [0|1] "" Vector__XXX
 SG_ VCLEFT_a562_2RowSeatAbsPosOffset m9 : 25|1@1+ (1,0) [0|1] "" Vector__XXX
 SG_ VCLEFT_a563_2RowSeatObstacleDete m9 : 26|1@1+ (1,0) [0|1] "" Vector__XXX
 SG_ VCLEFT_a564_2RowSeatTempHigh m9 : 27|1@1+ (1,0) [0|1] "" Vector__XXX
 SG_ VCLEFT_a565_2RowSeatAbsPosSensor m9 : 28|1@1+ (1,0) [0|1] "" Vector__XXX
 SG_ VCLEFT_a566_2RowSeatStatsFromLas m9 : 29|1@1+ (1,0) [0|1] "" Vector__XXX
 SG_ VCLEFT_a567_2RowSeatRequestWhile m9 : 30|1@1+ (1,0) [0|1] "" Vector__XXX
 SG_ VCLEFT_a568_2RowSeatClashAvoidan m9 : 31|1@1+ (1,0) [0|1] "" Vector__XXX
 SG_ VCLEFT_a569_2RowSeatOverfolded m9 : 32|1@1+ (1,0) [0|1] "" Vector__XXX
 SG_ VCLEFT_a570_seatHeatDisabledF m9 : 33|1@1+ (1,0) [0|1] "" Vector__XXX
 SG_ VCLEFT_a571_seatHeatDisabledRear m9 : 34|1@1+ (1,0) [0|1] "" Vector__XXX
 SG_ VCLEFT_a572_seatHeatDisabledRear m9 : 35|1@1+ (1,0) [0|1] "" Vector__XXX
 SG_ VCLEFT_a573_seatHeatDisabledRear m9 : 36|1@1+ (1,0) [0|1] "" Vector__XXX
 SG_ VCLEFT_a574_2RowSeatStatsFromLas m9 : 37|1@1+ (1,0) [0|1] "" Vector__XXX
 SG_ VCLEFT_a575_3RowSeatStatsFromLas m9 : 38|1@1+ (1,0) [0|1] "" Vector__XXX
 SG_ VCLEFT_a576_liftgateStrutPositio m9 : 39|1@1+ (1,0) [0|1] "" Vector__XXX
 SG_ VCLEFT_a577_bsiHardwareIssue m9 : 40|1@1+ (1,0) [0|1] "" Vector__XXX
 SG_ VCLEFT_a578_RGBLightFault m9 : 41|1@1+ (1,0) [0|1] "" Vector__XXX
 SG_ VCLEFT_a579_leftSteeringWheelCtr m9 : 42|1@1+ (1,0) [0|1] "" Vector__XXX
 SG_ VCLEFT_a580_rightSteeringWheelCt m9 : 43|1@1+ (1,0) [0|1] "" Vector__XXX
 SG_ VCLEFT_a581_reverseLightFault m9 : 44|1@1+ (1,0) [0|1] "" Vector__XXX
 SG_ VCLEFT_a582_seat2RControllerTrip m9 : 45|1@1+ (1,0) [0|1] "" Vector__XXX
 SG_ VCLEFT_a583_doorRemoteUnlatchedF m9 : 46|1@1+ (1,0) [0|1] "" Vector__XXX
 SG_ VCLEFT_a584_doorRemoteUnlatchedR m9 : 47|1@1+ (1,0) [0|1] "" Vector__XXX
 SG_ VCLEFT_a585_doorRemoteUnlatchFai m9 : 48|1@1+ (1,0) [0|1] "" Vector__XXX
 SG_ VCLEFT_a586_doorRemoteUnlatchFai m9 : 49|1@1+ (1,0) [0|1] "" Vector__XXX
 SG_ VCLEFT_a587_VCSEAT2L_MIA m9 : 50|1@1+ (1,0) [0|1] "" Vector__XXX
 SG_ VCLEFT_a589_lipcCanFault m9 : 52|1@1+ (1,0) [0|1] "" Vector__XXX
 SG_ VCLEFT_a590_seatEncStallThighSup m9 : 53|1@1+ (1,0) [0|1] "" Vector__XXX
 SG_ VCLEFT_a591_seatCurrUnderThighSu m9 : 54|1@1+ (1,0) [0|1] "" Vector__XXX
 SG_ VCLEFT_a592_seatUncalThighSuppor m9 : 55|1@1+ (1,0) [0|1] "" Vector__XXX
 SG_ VCLEFT_a593_seatEncOverThighSupp m9 : 56|1@1+ (1,0) [0|1] "" Vector__XXX
 SG_ VCLEFT_a594_seatThighSupportStal m9 : 57|1@1+ (1,0) [0|1] "" Vector__XXX
 SG_ VCLEFT_a595_seatThighSupportHCEn m9 : 58|1@1+ (1,0) [0|1] "" Vector__XXX
 SG_ VCLEFT_a596_frontDoorLatchUnexpe m9 : 59|1@1+ (1,0) [0|1] "" Vector__XXX
 SG_ VCLEFT_a597_rearDoorLatchUnexpec m9 : 60|1@1+ (1,0) [0|1] "" Vector__XXX
 SG_ VCLEFT_a599_LVBatteryTypeUnsuppo m9 : 62|1@1+ (1,0) [0|1] "" Vector__XXX
 SG_ VCLEFT_a601_wakeToOpenDoorDbg m10 : 4|1@1+ (1,0) [0|1] "" Vector__XXX
 SG_ VCLEFT_a605_CANMsgMACVerificatio m10 : 8|1@1+ (1,0) [0|1] "" Vector__XXX
 SG_ VCLEFT_a617_APP_MIA m10 : 20|1@1+ (1,0) [0|1] "" Vector__XXX

BO_ 258 VCLEFT_doorStatus: 8 VCLEFT
 SG_ VCLEFT_doorClosureStatusFront : 0|4@1+ (1,0) [1|15] "" Vector__XXX
 SG_ VCLEFT_doorClosureStatusRear : 4|4@1+ (1,0) [1|15] "" Vector__XXX
 SG_ VCLEFT_frontLatchSwitch : 8|1@1+ (1,0) [0|1] "" Vector__XXX
 SG_ VCLEFT_rearLatchSwitch : 9|1@1+ (1,0) [0|1] "" Vector__XXX
 SG_ VCLEFT_frontHandlePulled : 10|1@1+ (1,0) [0|1] "" Vector__XXX
 SG_ VCLEFT_rearHandlePulled : 11|1@1+ (1,0) [0|1] "" Vector__XXX
 SG_ VCLEFT_frontRelActuatorSwitch : 12|1@1+ (1,0) [0|1] "" Vector__XXX
 SG_ VCLEFT_rearRelActuatorSwitch : 13|1@1+ (1,0) [0|1] "" Vector__XXX
 SG_ VCLEFT_frontLatchStatus : 14|4@1+ (1,0) [1|15] "" Vector__XXX
 SG_ VCLEFT_rearLatchStatus : 18|4@1+ (1,0) [1|15] "" Vector__XXX
 SG_ VCLEFT_lastDoorReqSourceFront : 22|3@1+ (1,0) [0|7] "" Vector__XXX
 SG_ VCLEFT_lastDoorReqSourceRear : 25|3@1+ (1,0) [0|7] "" Vector__XXX
 SG_ VCLEFT_frontIntSwitchFaulted : 28|1@1+ (1,0) [0|1] "" Vector__XXX
 SG_ VCLEFT_rearIntSwitchFaulted : 29|1@1+ (1,0) [0|1] "" Vector__XXX
 SG_ VCLEFT_frontIntSwitchPressed : 31|1@1+ (1,0) [0|1] "" Vector__XXX
 SG_ VCLEFT_rearIntSwitchPressed : 32|1@1+ (1,0) [0|1] "" Vector__XXX
 SG_ VCLEFT_mirrorTiltXPosition : 33|8@1+ (0.02,0) [0|5] "V" Vector__XXX
 SG_ VCLEFT_mirrorTiltYPosition : 41|8@1+ (0.02,0) [0|5] "V" Vector__XXX
 SG_ VCLEFT_mirrorState : 49|3@1+ (1,0) [0|7] "" Vector__XXX
 SG_ VCLEFT_mirrorFoldState : 52|3@1+ (1,0) [0|7] "" Vector__XXX
 SG_ VCLEFT_mirrorRecallState : 55|3@1+ (1,0) [0|7] "" Vector__XXX
 SG_ VCLEFT_mirrorHeatState : 58|3@1+ (1,0) [1|7] "" Vector__XXX
 SG_ VCLEFT_rearHandlePulledPersist : 61|1@1+ (1,0) [0|1] "" Vector__XXX
 SG_ VCLEFT_frontHandlePulledPersist : 62|1@1+ (1,0) [0|1] "" Vector__XXX
 SG_ VCLEFT_mirrorDipped : 63|1@1+ (1,0) [0|1] "" Vector__XXX

BO_ 290 VCLEFT_doorStatus2: 8 VCLEFT
 SG_ VCLEFT_doorStatus2Index M : 0|1@1+ (1,0) [0|1] "" Vector__XXX
 SG_ VCLEFT_rearLatchRelDuty : 8|8@1+ (1,0) [0|255] "%" Vector__XXX
 SG_ VCLEFT_vehicleInMotion : 16|1@1+ (1,0) [0|1] "" Vector__XXX
 SG_ VCLEFT_frontDoorState : 17|3@1+ (1,0) [0|7] "" Vector__XXX
 SG_ VCLEFT_rearDoorState : 20|3@1+ (1,0) [0|7] "" Vector__XXX
 SG_ VCLEFT_frontHandleRawStatus : 24|3@1+ (1,0) [0|7] "" Vector__XXX
 SG_ VCLEFT_rearHandleRawStatus : 27|3@1+ (1,0) [0|7] "" Vector__XXX
 SG_ VCLEFT_frontHandleDebounceStatus : 32|3@1+ (1,0) [0|7] "" Vector__XXX
 SG_ VCLEFT_rearHandleDebounceStatus : 35|3@1+ (1,0) [0|7] "" Vector__XXX
 SG_ VCLEFT_frontHandle5vEnable : 38|1@1+ (1,0) [0|1] "" Vector__XXX
 SG_ VCLEFT_rearHandle5vEnable : 39|1@1+ (1,0) [0|1] "" Vector__XXX
 SG_ VCLEFT_BPillarCameraHeaterCurren m1 : 40|6@1+ (0.02,0) [0|1.24] "A" Vector__XXX
 SG_ VCLEFT_mirrorTiltXOffset m1 : 48|8@1- (0.02,0) [-2.5|2.5] "V" Vector__XXX
 SG_ VCLEFT_mirrorTiltYOffset m1 : 56|8@1- (0.02,0) [-2.5|2.5] "V" Vector__XXX

BO_ 626 VCLEFT_epbmDebug: 8 VCLEFT
 SG_ VCLEFT_epbmDebugIndex M : 0|1@1+ (1,0) [0|1] "" Vector__XXX
 SG_ VCLEFT_epbmCaliperState m0 : 1|3@1+ (1,0) [0|7] "" Vector__XXX
 SG_ VCLEFT_epbmMotorEnabled m0 : 4|1@1+ (1,0) [0|1] "" Vector__XXX
 SG_ VCLEFT_epbMotorCurrent m0 : 5|11@1+ (0.01,0) [0|20.47] "A" Vector__XXX
 SG_ VCLEFT_epbmApplyVoltage m0 : 16|11@1+ (0.01,0) [0|20.47] "A" Vector__XXX
 SG_ VCLEFT_epbmReleaseVoltage m0 : 27|11@1+ (0.01,0) [0|20.47] "A" Vector__XXX
 SG_ VCLEFT_summonFaultReason m0 : 38|5@1+ (1,0) [0|31] "" Vector__XXX
 SG_ VCLEFT_epbSummonState m0 : 43|3@1+ (1,0) [0|7] "" Vector__XXX
 SG_ VCLEFT_epbmSummonState m0 : 46|3@1+ (1,0) [0|7] "" Vector__XXX
 SG_ VCLEFT_epbUnitStatus m0 : 49|5@1+ (1,0) [0|31] "" Vector__XXX
 SG_ VCLEFT_epbmFaultStatus m0 : 54|2@1+ (1,0) [0|3] "" Vector__XXX
 SG_ VCLEFT_epbFaultStatus m0 : 56|2@1+ (1,0) [0|3] "" Vector__XXX
 SG_ VCLEFT_epbmSystemStatus m0 : 58|4@1+ (1,0) [0|15] "" Vector__XXX
 SG_ VCLEFT_epbmAutonomyBehavior m0 : 62|2@1+ (1,0) [0|3] "" Vector__XXX

BO_ 1186 VCLEFT_etcBluetoothStatus: 1 VCLEFT
 SG_ VCLEFT_etcBluetoothStatus : 0|2@1+ (1,0) [0|3] "" Vector__XXX

BO_ 642 VCLEFT_hvacBlowerFeedback: 8 VCLEFT
 SG_ VCLEFT_hvacBlowerFeedbackIndex M : 0|1@1+ (1,0) [0|1] "" Vector__XXX
 SG_ VCLEFT_hvacBlowerEnabled m0 : 2|1@1+ (1,0) [0|1] "" Vector__XXX
 SG_ VCLEFT_hvacBlowerOutputDuty m0 : 3|7@1+ (1,0) [0|100] "%" Vector__XXX
 SG_ VCLEFT_hvacBlowerRPMTarget m0 : 10|10@1+ (10,0) [0|10000] "rpm" Vector__XXX
 SG_ VCLEFT_hvacBlowerRPMActual m0 : 20|10@1+ (10,0) [0|10000] "rpm" Vector__XXX
 SG_ VCLEFT_hvacBlowerTorque m0 : 34|10@1+ (0.006,-1.5) [-1.5|4.5] "Nm" Vector__XXX
 SG_ VCLEFT_hvacBlowerFETTemp m0 : 44|7@1+ (2,-50) [-50|180] "degC" Vector__XXX
 SG_ VCLEFT_hvacBlowerIDc m0 : 51|7@1+ (0.5,0) [0|63] "A" Vector__XXX
 SG_ VCLEFT_hvacBlowerInitd m0 : 58|1@1+ (1,0) [0|1] "" Vector__XXX
 SG_ VCLEFT_hvacBlowerFault m0 : 59|1@1+ (1,0) [0|1] "" Vector__XXX
 SG_ VCLEFT_hvacBlowerLimitFETTemps m0 : 60|1@1+ (1,0) [0|1] "" Vector__XXX
 SG_ VCLEFT_hvacBlowerPowerOn m0 : 61|1@1+ (1,0) [0|1] "" Vector__XXX
 SG_ VCLEFT_hvacBlowerMotorID m0 : 62|2@1+ (1,0) [0|3] "" Vector__XXX

BO_ 770 VCLEFT_info: 8 VCLEFT
 SG_ VCLEFT_infoIndex M : 0|8@1+ (1,0) [0|255] "" Vector__XXX
 SG_ VCLEFT_infoBuildType m10 : 8|3@1+ (1,0) [0|7] "" Vector__XXX
 SG_ VCLEFT_infoBuildConfigId m10 : 16|16@1+ (1,0) [0|65535] "" Vector__XXX
 SG_ VCLEFT_infoHardwareId m10 : 32|16@1+ (1,0) [0|65535] "" Vector__XXX
 SG_ VCLEFT_infoComponentId m10 : 48|16@1+ (1,0) [0|65535] "" Vector__XXX
 SG_ VCLEFT_infoPcbaId m11 : 8|8@1+ (1,0) [0|255] "" Vector__XXX
 SG_ VCLEFT_infoAssemblyId m11 : 16|8@1+ (1,0) [0|254] "" Vector__XXX
 SG_ VCLEFT_infoUsageId m11 : 24|16@1+ (1,0) [0|65535] "" Vector__XXX
 SG_ VCLEFT_infoSubUsageId m11 : 40|16@1+ (1,0) [0|65535] "" Vector__XXX
 SG_ VCLEFT_infoAppCrc m13 : 8|32@1+ (1,0) [0|4294967295] "" Vector__XXX
 SG_ VCLEFT_infoLUMBARLAppCRC m16 : 32|32@1+ (1,0) [0|4294967295] "" Vector__XXX
 SG_ VCLEFT_infoAppGitHash m17 : 8|56@1+ (1,0) [0|7.20575940379e+16] "" Vector__XXX
 SG_ VCLEFT_infoBootGitHash m18 : 8|56@1+ (1,0) [0|7.20575940379e+16] "" Vector__XXX
 SG_ VCLEFT_infoPlatformType m19 : 8|8@1+ (1,0) [0|255] "" Vector__XXX
 SG_ VCLEFT_infoBootUdsProtoVersion m20 : 8|16@1+ (1,0) [0|65535] "" Vector__XXX
 SG_ VCLEFT_infoBootCrc m20 : 24|32@1+ (1,0) [0|4294967295] "" Vector__XXX

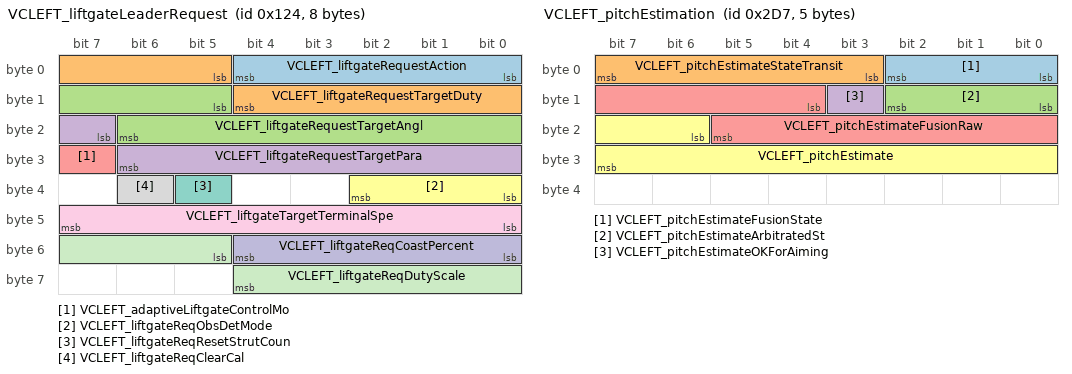
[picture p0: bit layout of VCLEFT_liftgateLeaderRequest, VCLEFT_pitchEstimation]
BO_ 292 VCLEFT_liftgateLeaderRequest: 8 VCLEFT
 SG_ VCLEFT_liftgateRequestAction : 0|5@1+ (1,0) [0|31] "" Vector__XXX
 SG_ VCLEFT_liftgateRequestTargetDuty : 5|8@1- (1,0) [-100|100] "%" Vector__XXX
 SG_ VCLEFT_liftgateRequestTargetAngl : 13|10@1- (0.2,0) [-100|100] "deg" Vector__XXX
 SG_ VCLEFT_liftgateRequestTargetPara : 23|8@1- (1,0) [-100|100] "" Vector__XXX
 SG_ VCLEFT_adaptiveLiftgateControlMo : 31|1@1+ (1,0) [0|1] "" Vector__XXX
 SG_ VCLEFT_liftgateReqObsDetMode : 32|3@1+ (1,0) [0|7] "" Vector__XXX
 SG_ VCLEFT_liftgateReqResetStrutCoun : 37|1@1+ (1,0) [0|1] "" Vector__XXX
 SG_ VCLEFT_liftgateReqClearCal : 38|1@1+ (1,0) [0|1] "" Vector__XXX
 SG_ VCLEFT_liftgateTargetTerminalSpe : 40|8@1- (0.08,10) [0|20] "deg/s" Vector__XXX
 SG_ VCLEFT_liftgateReqCoastPercent : 48|5@1+ (4,0) [0|100] "%" Vector__XXX
 SG_ VCLEFT_liftgateReqDutyScale : 53|8@1+ (0.0125,0) [0|3.15] "-" Vector__XXX

BO_ 322 VCLEFT_liftgateStatus: 8 VCLEFT
 SG_ VCLEFT_liftgateStatusIndex M : 0|2@1+ (1,0) [0|3] "" Vector__XXX
 SG_ VCLEFT_liftgateState m0 : 3|4@1+ (1,0) [0|15] "" Vector__XXX
 SG_ VCLEFT_liftgateStoppingCondition m0 : 10|4@1+ (1,0) [0|15] "" Vector__XXX
 SG_ VCLEFT_liftgateMvmntNotAllowedCo m0 : 14|3@1+ (1,0) [0|7] "" Vector__XXX
 SG_ VCLEFT_liftgatePositionCalibrate m0 : 17|1@1+ (1,0) [0|1] "" Vector__XXX
 SG_ VCLEFT_liftgateUIChimeRequest m0 : 18|3@1+ (1,0) [0|7] "" Vector__XXX
 SG_ VCLEFT_liftgatePhysicalChimeRequ m0 : 21|3@1+ (1,0) [0|7] "" Vector__XXX
 SG_ VCLEFT_liftgateEstimatedStrutTem m0 : 24|8@1+ (1,-60) [-60|195] "C" Vector__XXX
 SG_ VCLEFT_liftgateStaticStrutMode m0 : 32|3@1+ (1,0) [1|7] "" Vector__XXX
 SG_ VCLEFT_liftgateRequestSource m0 : 35|4@1+ (1,0) [0|15] "" Vector__XXX
 SG_ VCLEFT_liftgateNewHeightNudge m0 : 39|1@1+ (1,0) [0|1] "" Vector__XXX
 SG_ VCLEFT_liftgateNewSaveHeight m0 : 40|8@1+ (1,0) [0|255] "cm" Vector__XXX
 SG_ VCLEFT_liftgateGeofenceState m0 : 48|2@1+ (1,0) [0|3] "" Vector__XXX
 SG_ VCLEFT_liftgateCloseWarnChimeReq m0 : 56|1@1+ (1,0) [0|1] "" Vector__XXX
 SG_ VCLEFT_liftgateAboveCrossoverAng m0 : 59|1@1+ (1,0) [0|1] "" Vector__XXX
 SG_ VCLEFT_liftgateLatchRequest m0 : 61|3@1+ (1,0) [0|7] "" Vector__XXX
 SG_ VCLEFT_liftgateStrutDutyCycle m1 : 3|8@1- (1,0) [-100|100] "%" Vector__XXX
 SG_ VCLEFT_liftgateStrutCurrent m1 : 11|10@1- (0.1,0) [-30|30] "A" Vector__XXX
 SG_ VCLEFT_liftgatePosition m1 : 21|7@1- (1,46) [-5|95] "deg" Vector__XXX
 SG_ VCLEFT_liftgateSpeed m1 : 28|10@1- (0.1,0) [-30|30] "deg/s" Vector__XXX
 SG_ VCLEFT_liftgateHeight m1 : 38|8@1+ (1,0) [0|255] "cm" Vector__XXX
 SG_ VCLEFT_liftgatePositionDiff m1 : 46|6@1- (1,0) [-30|30] "deg" Vector__XXX

BO_ 994 VCLEFT_lightStatus: 7 VCLEFT
 SG_ VCLEFT_brakeLightStatus : 0|2@1+ (1,0) [0|2] "" Vector__XXX
 SG_ VCLEFT_tailLightStatus : 2|2@1+ (1,0) [0|2] "" Vector__XXX
 SG_ VCLEFT_turnSignalStatus : 4|2@1+ (1,0) [0|2] "" Vector__XXX
 SG_ VCLEFT_FLMapLightStatus : 6|2@1+ (1,0) [0|2] "" Vector__XXX
 SG_ VCLEFT_FRMapLightStatus : 8|2@1+ (1,0) [0|2] "" Vector__XXX
 SG_ VCLEFT_RLMapLightStatus : 10|2@1+ (1,0) [0|2] "" Vector__XXX
 SG_ VCLEFT_RRMapLightStatus : 12|2@1+ (1,0) [0|2] "" Vector__XXX
 SG_ VCLEFT_FLMapLightSwitchPressed : 14|1@1+ (1,0) [0|1] "" Vector__XXX
 SG_ VCLEFT_FRMapLightSwitchPressed : 15|1@1+ (1,0) [0|1] "" Vector__XXX
 SG_ VCLEFT_RLMapLightSwitchPressed : 16|1@1+ (1,0) [0|1] "" Vector__XXX
 SG_ VCLEFT_RRMapLightSwitchPressed : 17|1@1+ (1,0) [0|1] "" Vector__XXX
 SG_ VCLEFT_leftTurnTrailerLightStatu : 18|2@1+ (1,0) [0|2] "" Vector__XXX
 SG_ VCLEFT_rightTrnTrailerLightStatu : 20|2@1+ (1,0) [0|2] "" Vector__XXX
 SG_ VCLEFT_brakeTrailerLightStatus : 22|2@1+ (1,0) [0|2] "" Vector__XXX
 SG_ VCLEFT_tailTrailerLightStatus : 24|2@1+ (1,0) [0|2] "" Vector__XXX
 SG_ VCLEFT_fogTrailerLightStatus : 26|2@1+ (1,0) [0|2] "" Vector__XXX
 SG_ VCLEFT_frontRideHeight : 28|8@1- (1,0) [-127|127] "mm" Vector__XXX
 SG_ VCLEFT_rearRideHeight : 36|8@1- (1,0) [-127|127] "mm" Vector__XXX
 SG_ VCLEFT_leftDashRGBPowerRequest : 44|1@1+ (1,0) [0|1] "" Vector__XXX
 SG_ VCLEFT_rightDashRGBPowerRequest : 45|1@1+ (1,0) [0|1] "" Vector__XXX
 SG_ VCLEFT_trailerDetected : 46|2@1+ (1,0) [1|3] "" Vector__XXX
 SG_ VCLEFT_rideHeightSensorFault : 48|1@1+ (1,0) [0|1] "" Vector__XXX
 SG_ VCLEFT_reverseTrailerLightStatus : 49|2@1+ (1,0) [0|2] "" Vector__XXX
 SG_ VCLEFT_tailLightOutageStatus : 51|1@1+ (1,0) [0|1] "" Vector__XXX
 SG_ VCLEFT_reverseLightStatus : 52|2@1+ (1,0) [0|2] "" Vector__XXX
 SG_ VCLEFT_thirdRowLeftMapLightSwitc : 54|1@1+ (1,0) [0|1] "" Vector__XXX
 SG_ VCLEFT_thirdRowRightMapLightSwit : 55|1@1+ (1,0) [0|1] "" Vector__XXX

BO_ 1802 VCLEFT_logging0point1Hz: 5 VCLEFT
 SG_ VCLEFT_logging0point1HzIndex M : 0|1@1+ (1,0) [0|1] "" Vector__XXX
 SG_ VCLEFT_leftBrakeTailLightCurrent m0 : 2|9@1+ (0.005,0) [0|2.55] "A" Vector__XXX
 SG_ VCLEFT_leftBrakeTailLightCu_0001 m0 : 11|3@1+ (1,0) [1|7] "" Vector__XXX
 SG_ VCLEFT_leftRearTurnLightCurrent m0 : 14|9@1+ (0.002,0) [0|1.02] "A" Vector__XXX
 SG_ VCLEFT_leftRearTurnLightCurrentS m0 : 24|3@1+ (1,0) [1|7] "" Vector__XXX
 SG_ VCLEFT_phoneTemperatureFL m0 : 32|8@1- (1,-50) [-177|77] "degC" Vector__XXX

BO_ 649 VCLEFT_logging10Hz: 8 VCLEFT
 SG_ VCLEFT_logging10HzIndex M : 0|1@1+ (1,0) [0|1] "" Vector__XXX
 SG_ VCLEFT_hvacBlowerRs m0 : 1|8@1+ (0.25,0) [0|60] "mOhm" Vector__XXX
 SG_ VCLEFT_hvacBlowerIPhase0 m0 : 9|7@1+ (0.4,0) [0|50] "A" Vector__XXX
 SG_ VCLEFT_hvacBlowerIPhase1 m0 : 16|7@1+ (0.4,0) [0|50] "A" Vector__XXX
 SG_ VCLEFT_hvacBlowerIPhase2 m0 : 23|7@1+ (0.4,0) [0|50] "A" Vector__XXX
 SG_ VCLEFT_hvacBlower_IO_CBC_HEAD m0 : 30|4@1+ (1,0) [0|15] "" Vector__XXX
 SG_ VCLEFT_hvacBlower_IO_CBC_TAIL m0 : 34|4@1+ (1,0) [0|15] "" Vector__XXX
 SG_ VCLEFT_hvacBlower_IO_CBC_TAIL_va m0 : 38|1@1+ (1,0) [0|1] "" Vector__XXX
 SG_ VCLEFT_hvacBlower_IO_CBC_Status m0 : 39|1@1+ (1,0) [0|1] "" Vector__XXX
 SG_ VCLEFT_hvacBlower_IO_CBC_numUart m0 : 40|8@1+ (1,0) [0|255] "" Vector__XXX
 SG_ VCLEFT_hvacBlowerCBCEstState m0 : 48|4@1+ (1,0) [0|15] "" Vector__XXX
 SG_ VCLEFT_hvacBlowerCBCCtrlState m0 : 52|3@1+ (1,0) [0|7] "" Vector__XXX
 SG_ VCLEFT_hvacBlowerITerm m0 : 55|7@1+ (0.05,-1.5) [-1.5|4.5] "Nm" Vector__XXX
 SG_ VCLEFT_hvacBlowerSpiError m0 : 62|1@1+ (1,0) [0|1] "" Vector__XXX
 SG_ VCLEFT_hvacBlowerRsOnlineActive m0 : 63|1@1+ (1,0) [0|1] "" Vector__XXX

BO_ 936 VCLEFT_logging1Hz: 8 VCLEFT
 SG_ VCLEFT_logging1HzIndex M : 0|3@1+ (1,0) [0|7] "" Vector__XXX
 SG_ VCLEFT_tohcPCBATemperature m0 : 8|8@1+ (1,-40) [-40|214] "degC" Vector__XXX
 SG_ VCLEFT_phoneChargingFL m0 : 16|1@1+ (1,0) [0|1] "" Vector__XXX
 SG_ VCLEFT_phoneChargingFR m0 : 17|1@1+ (1,0) [0|1] "" Vector__XXX
 SG_ VCLEFT_swcResistance m0 : 24|7@1+ (0.025,0) [0|3.15] "Ohm" Vector__XXX
 SG_ VCLEFT_frontSeatHeatCushionPwr m0 : 32|7@1+ (1,0) [0|127] "W" Vector__XXX
 SG_ VCLEFT_frontSeatHeatBackrestPwr m0 : 40|7@1+ (1,0) [0|127] "W" Vector__XXX
 SG_ VCLEFT_rgbLedIPFLCurrent m3 : 3|10@1+ (0.000488758552819,0) [0|0.499999999534] "A" Vector__XXX
 SG_ VCLEFT_rgbLedIPFRCurrent m3 : 13|10@1+ (0.000488758552819,0) [0|0.499999999534] "A" Vector__XXX
 SG_ VCLEFT_rgbLedIPFLOutput m3 : 23|1@1+ (1,0) [0|1] "" Vector__XXX
 SG_ VCLEFT_rgbLedIPFROutput m3 : 24|1@1+ (1,0) [0|1] "" Vector__XXX
 SG_ VCLEFT_rgbLedFrontCurrent m3 : 25|10@1+ (0.000488758552819,0) [0|0.499999999534] "A" Vector__XXX
 SG_ VCLEFT_rgbLedRearCurrent m3 : 35|10@1+ (0.000488758552819,0) [0|0.499999999534] "A" Vector__XXX
 SG_ VCLEFT_rgbLedFrontOutput m3 : 45|1@1+ (1,0) [0|1] "" Vector__XXX
 SG_ VCLEFT_rgbLedRearOutput m3 : 46|1@1+ (1,0) [0|1] "" Vector__XXX
 SG_ VCLEFT_seat2RControllerCurrent m3 : 55|9@1+ (0.2,0) [0|102] "A" Vector__XXX

BO_ 727 VCLEFT_pitchEstimation: 5 VCLEFT
 SG_ VCLEFT_pitchEstimateFusionState : 0|3@1+ (1,0) [0|7] "" Vector__XXX
 SG_ VCLEFT_pitchEstimateStateTransit : 3|5@1+ (1,0) [0|31] "" Vector__XXX
 SG_ VCLEFT_pitchEstimateArbitratedSt : 8|3@1+ (1,0) [0|7] "" Vector__XXX
 SG_ VCLEFT_pitchEstimateOKForAiming : 11|1@1+ (1,0) [0|1] "" Vector__XXX
 SG_ VCLEFT_pitchEstimateFusionRaw : 12|10@1- (0.0002,0) [-0.1024|0.1022] "rad" Vector__XXX
 SG_ VCLEFT_pitchEstimate : 22|10@1- (0.0002,0) [-0.1022|0.1022] "rad" Vector__XXX

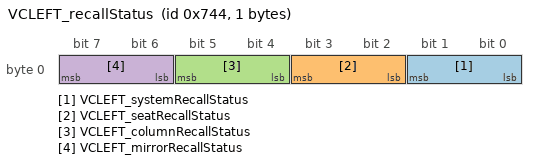
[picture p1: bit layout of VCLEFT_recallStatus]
BO_ 1860 VCLEFT_recallStatus: 1 VCLEFT
 SG_ VCLEFT_systemRecallStatus : 0|2@1+ (1,0) [1|3] "" Vector__XXX
 SG_ VCLEFT_seatRecallStatus : 2|2@1+ (1,0) [1|3] "" Vector__XXX
 SG_ VCLEFT_columnRecallStatus : 4|2@1+ (1,0) [1|3] "" Vector__XXX
 SG_ VCLEFT_mirrorRecallStatus : 6|2@1+ (1,0) [1|3] "" Vector__XXX

BO_TX_BU_ 864 : VCLEFT;
BO_TX_BU_ 258 : VCLEFT;
BO_TX_BU_ 290 : VCLEFT;
BO_TX_BU_ 626 : VCLEFT;
BO_TX_BU_ 1186 : VCLEFT;
BO_TX_BU_ 642 : VCLEFT;
BO_TX_BU_ 770 : VCLEFT;
BO_TX_BU_ 292 : VCLEFT;
BO_TX_BU_ 322 : VCLEFT;
BO_TX_BU_ 994 : VCLEFT;
BO_TX_BU_ 1802 : VCLEFT;
BO_TX_BU_ 649 : VCLEFT;
BO_TX_BU_ 936 : VCLEFT;
BO_TX_BU_ 727 : VCLEFT;
BO_TX_BU_ 1860 : VCLEFT;
CM_ BO_ 864 "Left body controller message: alert matrix; frame length observed on a vehicle bus";
CM_ SG_ 864 VCLEFT_matrixIndex "Left body controller: matrix index";
CM_ SG_ 864 VCLEFT_a001_WatchdogReset "Left body controller: a001 watchdog reset";
CM_ SG_ 864 VCLEFT_a002_PowerLossReset "Left body controller: a002 power loss reset";
CM_ SG_ 864 VCLEFT_a003_SWAssertion "Left body controller: a003 SW assertion";
CM_ SG_ 864 VCLEFT_a005_CANTXError "Left body controller: a005 CANTX error";
CM_ SG_ 864 VCLEFT_a006_CANTX_cyclicError "Left body controller: a006 CANTX cyclic error";
CM_ SG_ 864 VCLEFT_a010_ExtSupplyVoltError "Left body controller: a010 ext supply volt error";
CM_ SG_ 864 VCLEFT_a012_CPUReset "Left body controller: a012 CPU reset";
CM_ SG_ 864 VCLEFT_a013_AlertManagerFault "Left body controller: a013 alert manager fault";
CM_ SG_ 864 VCLEFT_a015_NVMMError "Left body controller: a015 NVMM error";
CM_ SG_ 864 VCLEFT_a016_NVMMRecordError "Left body controller: a016 NVMM record error";
CM_ SG_ 864 VCLEFT_a017_NVMMStatusDbg "Left body controller: a017 NVMM status dbg";
CM_ SG_ 864 VCLEFT_a021_TaskSchedulerError "Left body controller: a021 task scheduler error";
CM_ SG_ 864 VCLEFT_a022_TaskInitError "Left body controller: a022 task init error";
CM_ SG_ 864 VCLEFT_a029_CoreDump "Left body controller: a029 core dump";
CM_ SG_ 864 VCLEFT_a030_ECULogUploadRequest "Left body controller: a030 ECU log upload request";
CM_ SG_ 864 VCLEFT_a031_UDSActive "Left body controller: a031 UDS active";
CM_ SG_ 864 VCLEFT_a041_HighCPULoad "Left body controller: a041 high CPU load";
CM_ SG_ 864 VCLEFT_a042_HighStackUsage "Left body controller: a042 high stack usage";
CM_ SG_ 864 VCLEFT_a043_Task1msError "Left body controller: a043 task1ms error";
CM_ SG_ 864 VCLEFT_a044_Task10msError "Left body controller: a044 task10ms error";
CM_ SG_ 864 VCLEFT_a045_Task100msError "Left body controller: a045 task100ms error";
CM_ SG_ 864 VCLEFT_a046_Task1000msError "Left body controller: a046 task1000ms error";
CM_ SG_ 864 VCLEFT_a057_HVP_MIA "Left body controller: a057 HVP MIA";
CM_ SG_ 864 VCLEFT_a058_inputRHighSyncDebug "Left body controller: a058 input r high sync debug";
CM_ SG_ 864 VCLEFT_a059_inputResistanceHigh "Left body controller: a059 input resistance high";
CM_ SG_ 864 VCLEFT_a060_engineeringBuild "Left body controller: a060 engineering build";
CM_ SG_ 864 VCLEFT_a061_XCPConnected "Left body controller: a061 XCP connected";
CM_ SG_ 864 VCLEFT_a062_XCPWasConnected "Left body controller: a062 XCP was connected";
CM_ SG_ 864 VCLEFT_a063_SwitchFault "Left body controller: a063 switch fault";
CM_ SG_ 864 VCLEFT_a064_busSleepReqTimeout "Left body controller: a064 bus sleep req timeout";
CM_ SG_ 864 VCLEFT_a065_emiosIsrRateLimitedD "Left body controller: a065 emios isr rate limited dbg";
CM_ SG_ 864 VCLEFT_a066_emiosIsrShortPeriodD "Left body controller: a066 emios isr short period detected dbg";
CM_ SG_ 864 VCLEFT_a082_VCRIGHT_IPC_MIA "Left body controller: a082 VCRIGHT IPC MIA";
CM_ SG_ 864 VCLEFT_a083_VCLEFT_IPC_MIA "Left body controller: a083 VCLEFT IPC MIA";
CM_ SG_ 864 VCLEFT_a084_TPMS_MIA "Left body controller: a084 TPMS MIA";
CM_ SG_ 864 VCLEFT_a085_CCCM_MIA "Left body controller: a085 CCCM MIA";
CM_ SG_ 864 VCLEFT_a086_VCBATT_MIA "Left body controller: a086 VCBATT MIA";
CM_ SG_ 864 VCLEFT_a087_DIREL_MIA "Left body controller: a087 DIREL MIA";
CM_ SG_ 864 VCLEFT_a088_DIRER_MIA "Left body controller: a088 DIRER MIA";
CM_ SG_ 864 VCLEFT_a089_IBST_MIA "Left body controller: a089 IBST MIA";
CM_ SG_ 864 VCLEFT_a090_APS_MIA "Left body controller: a090 APS MIA";
CM_ SG_ 864 VCLEFT_a091_CMPD_MIA "Left body controller: a091 CMPD MIA";
CM_ SG_ 864 VCLEFT_a092_VCSEATD_MIA "Left body controller: a092 VCSEATD MIA";
CM_ SG_ 864 VCLEFT_a093_VCSEATP_MIA "Left body controller: a093 VCSEATP MIA";
CM_ SG_ 864 VCLEFT_a094_EPAS3P_MIA "Left body controller: a094 EPAS3 p MIA";
CM_ SG_ 864 VCLEFT_a095_CHG_MIA "Left body controller: a095 CHG MIA";
CM_ SG_ 864 VCLEFT_a096_OCS1P_MIA "Left body controller: a096 OCS1 p MIA";
CM_ SG_ 864 VCLEFT_a097_CMP_MIA "Left body controller: a097 CMP MIA";
CM_ SG_ 864 VCLEFT_a098_DIR_MIA "Left body controller: a098 DIR MIA";
CM_ SG_ 864 VCLEFT_a099_PARK_MIA "Left body controller: a099 PARK MIA";
CM_ SG_ 864 VCLEFT_a100_CANbus_MIA "Left body controller: a100 CA nbus MIA";
CM_ SG_ 864 VCLEFT_a101_PM_MIA "Left body controller: a101 PM MIA";
CM_ SG_ 864 VCLEFT_a102_PTC_MIA "Left body controller: a102 PTC MIA";
CM_ SG_ 864 VCLEFT_a103_CP_MIA "Left body controller: a103 CP MIA";
CM_ SG_ 864 VCLEFT_a104_DAS_MIA "Left body controller: a104 DAS MIA";
CM_ SG_ 864 VCLEFT_a105_TAS_MIA "Left body controller: a105 TAS MIA";
CM_ SG_ 864 VCLEFT_a106_PCS_MIA "Left body controller: a106 PCS MIA";
CM_ SG_ 864 VCLEFT_a107_BMS_MIA "Left body controller: a107 BMS MIA";
CM_ SG_ 864 VCLEFT_a108_DIF_MIA "Left body controller: a108 DIF MIA";
CM_ SG_ 864 VCLEFT_a109_RCM_MIA "Left body controller: a109 RCM MIA";
CM_ SG_ 864 VCLEFT_a110_GTW_MIA "Left body controller: a110 GTW MIA";
CM_ SG_ 864 VCLEFT_a111_EPBR_MIA "Left body controller: a111 EPBR MIA";
CM_ SG_ 864 VCLEFT_a112_EPBL_MIA "Left body controller: a112 EPBL MIA";
CM_ SG_ 864 VCLEFT_a113_UI_MIA "Left body controller: a113 UI MIA";
CM_ SG_ 864 VCLEFT_a114_ESP_MIA "Left body controller: a114 ESP MIA";
CM_ SG_ 864 VCLEFT_a115_VCSEC_MIA "Left body controller: a115 VCSEC MIA";
CM_ SG_ 864 VCLEFT_a116_VCRIGHT_MIA "Left body controller: a116 VCRIGHT MIA";
CM_ SG_ 864 VCLEFT_a117_VCLEFT_MIA "Left body controller: a117 VCLEFT MIA";
CM_ SG_ 864 VCLEFT_a118_VCFRONT_MIA "Left body controller: a118 VCFRONT MIA";
CM_ SG_ 864 VCLEFT_a119_SCCM_MIA "Left body controller: a119 SCCM MIA";
CM_ SG_ 864 VCLEFT_a120_DI_DRIVE_MIA "Left body controller: a120 DI DRIVE MIA";
CM_ SG_ 864 VCLEFT_a121_ETC_MIA "Left body controller: a121 ETC MIA";
CM_ SG_ 864 VCLEFT_a122_ICR_MIA "Left body controller: a122 ICR MIA";
CM_ SG_ 864 VCLEFT_a123_AID_MIA "Left body controller: a123 AID MIA";
CM_ SG_ 864 VCLEFT_a124_BB_MIA "Left body controller: a124 BB MIA";
CM_ SG_ 864 VCLEFT_a125_RCU_MIA "Left body controller: a125 RCU MIA";
CM_ SG_ 864 VCLEFT_a129_blowerICLatchFault "Left body controller: a129 blower IC latch fault";
CM_ SG_ 864 VCLEFT_a130_blowerICWarning "Left body controller: a130 blower IC warning";
CM_ SG_ 864 VCLEFT_a131_blowerICTransFault "Left body controller: a131 blower IC trans fault";
CM_ SG_ 864 VCLEFT_a132_blowerSoftStall "Left body controller: a132 blower soft stall";
CM_ SG_ 864 VCLEFT_a133_blowerLowRPMCBang "Left body controller: a133 blower low RPMC bang";
CM_ SG_ 864 VCLEFT_a134_SteerColUpDownUnCal "Left body controller: a134 steer col up down un cal";
CM_ SG_ 864 VCLEFT_a135_SteerColInOutUnCal "Left body controller: a135 steer col in out un cal";
CM_ SG_ 864 VCLEFT_a136_brakeSwitchMismatch "Left body controller: a136 brake switch mismatch";
CM_ SG_ 864 VCLEFT_a137_VCSECPowerCycled "Left body controller: a137 VCSEC power cycled";
CM_ SG_ 864 VCLEFT_a138_consoleDoorAssist "Left body controller: a138 console door assist";
CM_ SG_ 864 VCLEFT_a139_BLERearPowerCycled "Left body controller: a139 BLE rear power cycled";
CM_ SG_ 864 VCLEFT_a140_BLELeftPowerCycled "Left body controller: a140 BLE left power cycled";
CM_ SG_ 864 VCLEFT_a141_12VAuxPowerTrip "Left body controller: a141 12 v aux power trip";
CM_ SG_ 864 VCLEFT_a143_mirrorManuallyFolded "Left body controller: a143 mirror manually folded";
CM_ SG_ 864 VCLEFT_a145_brakeSwitchStuck "Left body controller: a145 brake switch stuck";
CM_ SG_ 864 VCLEFT_a148_brakePressInputMisma "Left body controller: a148 brake press input mismatch";
CM_ SG_ 864 VCLEFT_a150_windowPinchFront "Left body controller: a150 window pinch front";
CM_ SG_ 864 VCLEFT_a151_windowPinchRear "Left body controller: a151 window pinch rear";
CM_ SG_ 864 VCLEFT_a152_windowUncalFront "Left body controller: a152 window uncal front";
CM_ SG_ 864 VCLEFT_a153_windowUncalRear "Left body controller: a153 window uncal rear";
CM_ SG_ 864 VCLEFT_a154_windowThermalFront "Left body controller: a154 window thermal front";
CM_ SG_ 864 VCLEFT_a155_windowThermalRear "Left body controller: a155 window thermal rear";
CM_ SG_ 864 VCLEFT_a156_windowNoInputFront "Left body controller: a156 window no input front";
CM_ SG_ 864 VCLEFT_a157_windowNoInputRear "Left body controller: a157 window no input rear";
CM_ SG_ 864 VCLEFT_a158_windowPinchOverideF "Left body controller: a158 window pinch overide f";
CM_ SG_ 864 VCLEFT_a159_windowPinchOverideR "Left body controller: a159 window pinch overide r";
CM_ SG_ 864 VCLEFT_a160_windowUndercurrentF "Left body controller: a160 window undercurrent f";
CM_ SG_ 864 VCLEFT_a161_windowUndercurrentR "Left body controller: a161 window undercurrent r";
CM_ SG_ 864 VCLEFT_a162_windowEncoderStallF "Left body controller: a162 window encoder stall f";
CM_ SG_ 864 VCLEFT_a163_windowEncoderStallR "Left body controller: a163 window encoder stall r";
CM_ SG_ 864 VCLEFT_a164_windowFactoryTest "Left body controller: a164 window factory test";
CM_ SG_ 864 VCLEFT_a165_windowFactoryTest2 "Left body controller: a165 window factory test2";
CM_ SG_ 864 VCLEFT_a166_windowDebug "Left body controller: a166 window debug";
CM_ SG_ 864 VCLEFT_a167_windowDebugPinchF "Left body controller: a167 window debug pinch f";
CM_ SG_ 864 VCLEFT_a168_windowDebugPinchR "Left body controller: a168 window debug pinch r";
CM_ SG_ 864 VCLEFT_a169_windowCurrentPeakF "Left body controller: a169 window current peak f";
CM_ SG_ 864 VCLEFT_a170_windowCurrentPeakR "Left body controller: a170 window current peak r";
CM_ SG_ 864 VCLEFT_a172_SPI_MIA "Left body controller: a172 SPI MIA";
CM_ SG_ 864 VCLEFT_a173_windowBtnDoorOpen "Left body controller: a173 window btn door open";
CM_ SG_ 864 VCLEFT_a175_windowSealDefectFron "Left body controller: a175 window seal defect front";
CM_ SG_ 864 VCLEFT_a176_windowSealDefectRear "Left body controller: a176 window seal defect rear";
CM_ SG_ 864 VCLEFT_a180_frontDoorLatchRehome "Left body controller: a180 front door latch rehome";
CM_ SG_ 864 VCLEFT_a181_rearDoorLatchRehome "Left body controller: a181 rear door latch rehome";
CM_ SG_ 864 VCLEFT_a182_emergencyLatchRel "Left body controller: a182 emergency latch rel";
CM_ SG_ 864 VCLEFT_a183_doorStateFactoryTest "Left body controller: a183 door state factory test";
CM_ SG_ 864 VCLEFT_a185_summonAborted "Left body controller: a185 summon aborted";
CM_ SG_ 864 VCLEFT_a186_latchReleaseFailedF "Left body controller: a186 latch release failed f";
CM_ SG_ 864 VCLEFT_a187_latchReleaseFailedR "Left body controller: a187 latch release failed r";
CM_ SG_ 864 VCLEFT_a188_latchUnableToRearmF "Left body controller: a188 latch unable to rearm f";
CM_ SG_ 864 VCLEFT_a189_latchUnableToRearmR "Left body controller: a189 latch unable to rearm r";
CM_ SG_ 864 VCLEFT_a190_eFuseMgmtVbatFused "Left body controller: a190 e fuse mgmt vbat fused";
CM_ SG_ 864 VCLEFT_a191_TLCOvercurrent "Left body controller: a191 TLC overcurrent";
CM_ SG_ 864 VCLEFT_a192_blowerGeneralFault "Left body controller: a192 blower general fault";
CM_ SG_ 864 VCLEFT_a193_blowerMIA "Left body controller: a193 blower MIA";
CM_ SG_ 864 VCLEFT_a194_blowerUnidentified "Left body controller: a194 blower unidentified";
CM_ SG_ 864 VCLEFT_a195_blowerIdentification "Left body controller: a195 blower identification failed";
CM_ SG_ 864 VCLEFT_a196_VEHCANOverterminate "Left body controller: a196 VEHCAN overterminate";
CM_ SG_ 864 VCLEFT_a197_VEHCANUndertrminate "Left body controller: a197 VEHCAN undertrminate";
CM_ SG_ 864 VCLEFT_a200_motorPhantomEncoder "Left body controller: a200 motor phantom encoder";
CM_ SG_ 864 VCLEFT_a201_motorDutyEncDisabl "Left body controller: a201 motor duty enc disabl";
CM_ SG_ 864 VCLEFT_a202_epbmUnderIStatic "Left body controller: a202 epbm under i static";
CM_ SG_ 864 VCLEFT_a203_epbmOverIStatic "Left body controller: a203 epbm over i static";
CM_ SG_ 864 VCLEFT_a204_epbmUnderIDyn "Left body controller: a204 epbm under i dyn";
CM_ SG_ 864 VCLEFT_a205_epbmOverIDyn "Left body controller: a205 epbm over i dyn";
CM_ SG_ 864 VCLEFT_a206_epbWrongDirection "Left body controller: a206 epb wrong direction";
CM_ SG_ 864 VCLEFT_a207_epbmEnableWrong "Left body controller: a207 epbm enable wrong";
CM_ SG_ 864 VCLEFT_a208_epbFaulted "Left body controller: a208 epb faulted";
CM_ SG_ 864 VCLEFT_a209_epbStateMisTime "Left body controller: a209 epb state mis time";
CM_ SG_ 864 VCLEFT_a210_epbStateTime "Left body controller: a210 epb state time";
CM_ SG_ 864 VCLEFT_a211_epbmUnderIStaticNew "Left body controller: a211 epbm under i static new";
CM_ SG_ 864 VCLEFT_a212_epbmOverIStaticNew "Left body controller: a212 epbm over i static new";
CM_ SG_ 864 VCLEFT_a213_epbmUnderIDynNew "Left body controller: a213 epbm under i dyn new";
CM_ SG_ 864 VCLEFT_a214_epbmOverIDynNew "Left body controller: a214 epbm over i dyn new";
CM_ SG_ 864 VCLEFT_a215_currentDesyncWarning "Left body controller: a215 current desync warning";
CM_ SG_ 864 VCLEFT_a216_SPI_MIA_debugData1 "Left body controller: a216 SPI MIA debug data1";
CM_ SG_ 864 VCLEFT_a217_SPI_MIA_debugData2 "Left body controller: a217 SPI MIA debug data2";
CM_ SG_ 864 VCLEFT_a218_motorDriverFault "Left body controller: a218 motor driver fault";
CM_ SG_ 864 VCLEFT_a219_motorCurrentDropout "Left body controller: a219 motor current dropout";
CM_ SG_ 864 VCLEFT_a220_reverseLightFaultUse "Left body controller: a220 reverse light fault user";
CM_ SG_ 864 VCLEFT_a221_hardwareLoadshedTrig "Left body controller: a221 hardware loadshed triggered";
CM_ SG_ 864 VCLEFT_a223_VCBATT1_MIA "Left body controller: a223 VCBATT1 MIA";
CM_ SG_ 864 VCLEFT_a224_seatEncStallTrack "Left body controller: a224 seat enc stall track";
CM_ SG_ 864 VCLEFT_a225_seatEncStallBack "Left body controller: a225 seat enc stall back";
CM_ SG_ 864 VCLEFT_a226_seatEncStallTilt "Left body controller: a226 seat enc stall tilt";
CM_ SG_ 864 VCLEFT_a227_seatEncStallLift "Left body controller: a227 seat enc stall lift";
CM_ SG_ 864 VCLEFT_a228_seatEncOverTrack "Left body controller: a228 seat enc over track";
CM_ SG_ 864 VCLEFT_a229_seatEncOverBack "Left body controller: a229 seat enc over back";
CM_ SG_ 864 VCLEFT_a230_seatEncOverTilt "Left body controller: a230 seat enc over tilt";
CM_ SG_ 864 VCLEFT_a231_seatEncOverLift "Left body controller: a231 seat enc over lift";
CM_ SG_ 864 VCLEFT_a232_seatCurrUnderTrack "Left body controller: a232 seat curr under track";
CM_ SG_ 864 VCLEFT_a233_seatCurrUnderBack "Left body controller: a233 seat curr under back";
CM_ SG_ 864 VCLEFT_a234_seatCurrUnderTilt "Left body controller: a234 seat curr under tilt";
CM_ SG_ 864 VCLEFT_a235_seatCurrUnderLift "Left body controller: a235 seat curr under lift";
CM_ SG_ 864 VCLEFT_a236_lumbarOverPresA "Left body controller: a236 lumbar over pres a";
CM_ SG_ 864 VCLEFT_a237_lumbarOverPresB "Left body controller: a237 lumbar over pres b";
CM_ SG_ 864 VCLEFT_a238_lumbarValveMIA "Left body controller: a238 lumbar valve MIA";
CM_ SG_ 864 VCLEFT_a239_seatHeatIFront "Left body controller: a239 seat heat i front";
CM_ SG_ 864 VCLEFT_a240_seatHeatShortFront "Left body controller: a240 seat heat short front";
CM_ SG_ 864 VCLEFT_a241_seatHeatMIAFront "Left body controller: a241 seat heat MIA front";
CM_ SG_ 864 VCLEFT_a242_seatHeatIRearL "Left body controller: a242 seat heat i rear l";
CM_ SG_ 864 VCLEFT_a243_seatHeatShortRearL "Left body controller: a243 seat heat short rear l";
CM_ SG_ 864 VCLEFT_a244_seatHeatMIARearL "Left body controller: a244 seat heat MIA rear l";
CM_ SG_ 864 VCLEFT_a245_seatHeatIRearC "Left body controller: a245 seat heat i rear c";
CM_ SG_ 864 VCLEFT_a246_seatHeatShortRearC "Left body controller: a246 seat heat short rear c";
CM_ SG_ 864 VCLEFT_a247_seatHeatMIARearC "Left body controller: a247 seat heat MIA rear c";
CM_ SG_ 864 VCLEFT_a248_seatHeatIRearR "Left body controller: a248 seat heat i rear r";
CM_ SG_ 864 VCLEFT_a249_seatHeatShortRearR "Left body controller: a249 seat heat short rear r";
CM_ SG_ 864 VCLEFT_a250_seatHeatMIARearR "Left body controller: a250 seat heat MIA rear r";
CM_ SG_ 864 VCLEFT_a251_seatUncalTrack "Left body controller: a251 seat uncal track";
CM_ SG_ 864 VCLEFT_a252_seatUncalBack "Left body controller: a252 seat uncal back";
CM_ SG_ 864 VCLEFT_a253_seatUncalTilt "Left body controller: a253 seat uncal tilt";
CM_ SG_ 864 VCLEFT_a254_seatUncalLift "Left body controller: a254 seat uncal lift";
CM_ SG_ 864 VCLEFT_a256_nxppca9539Fault "Left body controller: a256 nxppca9539 fault";
CM_ SG_ 864 VCLEFT_a257_USBMIA "Left body controller: a257 USBMIA";
CM_ SG_ 864 VCLEFT_a259_latchDisarmDelayF "Left body controller: a259 latch disarm delay f";
CM_ SG_ 864 VCLEFT_a260_latchDisarmDelayR "Left body controller: a260 latch disarm delay r";
CM_ SG_ 864 VCLEFT_a261_emergencyLatchRelRea "Left body controller: a261 emergency latch rel rear";
CM_ SG_ 864 VCLEFT_a263_seatTrackStallDebug "Left body controller: a263 seat track stall debug";
CM_ SG_ 864 VCLEFT_a264_seatBackStallDebug "Left body controller: a264 seat back stall debug";
CM_ SG_ 864 VCLEFT_a265_seatTiltStallDebug "Left body controller: a265 seat tilt stall debug";
CM_ SG_ 864 VCLEFT_a266_seatLiftStallDebug "Left body controller: a266 seat lift stall debug";
CM_ SG_ 864 VCLEFT_a267_seatTrackHCEncStlDbg "Left body controller: a267 seat track HC enc stl dbg";
CM_ SG_ 864 VCLEFT_a268_seatBackHCEncStlDbg "Left body controller: a268 seat back HC enc stl dbg";
CM_ SG_ 864 VCLEFT_a269_seatTiltHCEncStlDbg "Left body controller: a269 seat tilt HC enc stl dbg";
CM_ SG_ 864 VCLEFT_a270_seatLiftHCEncStlDbg "Left body controller: a270 seat lift HC enc stl dbg";
CM_ SG_ 864 VCLEFT_a272_vhclPwrStateMsmtch "Left body controller: a272 vhcl pwr state msmtch";
CM_ SG_ 864 VCLEFT_a273_handleStuckActiveF "Left body controller: a273 handle stuck active f";
CM_ SG_ 864 VCLEFT_a274_handleStuckActiveR "Left body controller: a274 handle stuck active r";
CM_ SG_ 864 VCLEFT_a275_leftTurnLightFault "Left body controller: a275 left turn light fault";
CM_ SG_ 864 VCLEFT_a276_mirrorDebug "Left body controller: a276 mirror debug";
CM_ SG_ 864 VCLEFT_a277_BLELeftUnderVoltage "Left body controller: a277 BLE left under voltage";
CM_ SG_ 864 VCLEFT_a278_BLERearUnderVoltage "Left body controller: a278 BLE rear under voltage";
CM_ SG_ 864 VCLEFT_a279_VCSECUnderVoltage "Left body controller: a279 VCSEC under voltage";
CM_ SG_ 864 VCLEFT_a280_latchDidNotDisarmF "Left body controller: a280 latch did not disarm f";
CM_ SG_ 864 VCLEFT_a281_latchDidNotDisarmR "Left body controller: a281 latch did not disarm r";
CM_ SG_ 864 VCLEFT_a282_latchUnexpectedArmF "Left body controller: a282 latch unexpected arm f";
CM_ SG_ 864 VCLEFT_a283_latchUnexpectedArmR "Left body controller: a283 latch unexpected arm r";
CM_ SG_ 864 VCLEFT_a284_blowerFbkSanity "Left body controller: a284 blower fbk sanity";
CM_ SG_ 864 VCLEFT_a285_blowerChipComms "Left body controller: a285 blower chip comms";
CM_ SG_ 864 VCLEFT_a286_windowSpeedInvalidF "Left body controller: a286 window speed invalid f";
CM_ SG_ 864 VCLEFT_a287_windowSpeedInvalidR "Left body controller: a287 window speed invalid r";
CM_ SG_ 864 VCLEFT_a288_handlePWMPeriodF "Left body controller: a288 handle PWM period f";
CM_ SG_ 864 VCLEFT_a289_handlePWMPeriodR "Left body controller: a289 handle PWM period r";
CM_ SG_ 864 VCLEFT_a290_occupancyFaultedFron "Left body controller: a290 occupancy faulted front";
CM_ SG_ 864 VCLEFT_a291_buckleFaultedFront "Left body controller: a291 buckle faulted front";
CM_ SG_ 864 VCLEFT_a292_occupancyFaultedRear "Left body controller: a292 occupancy faulted rear l";
CM_ SG_ 864 VCLEFT_a293_occupancyFaultedRear "Left body controller: a293 occupancy faulted rear c";
CM_ SG_ 864 VCLEFT_a294_occupancyFaultedRear "Left body controller: a294 occupancy faulted rear r";
CM_ SG_ 864 VCLEFT_a295_buckleFaultedRearL "Left body controller: a295 buckle faulted rear l";
CM_ SG_ 864 VCLEFT_a296_buckleFaultedRearC "Left body controller: a296 buckle faulted rear c";
CM_ SG_ 864 VCLEFT_a297_seatBelowMinPumpTmp "Left body controller: a297 seat below min pump tmp";
CM_ SG_ 864 VCLEFT_a299_swcMIA "Left body controller: a299 swc MIA";
CM_ SG_ 864 VCLEFT_a300_swcUnderVoltage "Left body controller: a300 swc under voltage";
CM_ SG_ 864 VCLEFT_a301_swcOverVoltage "Left body controller: a301 swc over voltage";
CM_ SG_ 864 VCLEFT_a302_blowerGeneralFault "Left body controller: a302 blower general fault";
CM_ SG_ 864 VCLEFT_a303_eFuseMgmtWindowLift "Left body controller: a303 e fuse mgmt window lift";
CM_ SG_ 864 VCLEFT_a304_frontIntHandleUnexpe "Left body controller: a304 front int handle unexpected voltage";
CM_ SG_ 864 VCLEFT_a305_rearIntHandleUnexpec "Left body controller: a305 rear int handle unexpected voltage";
CM_ SG_ 864 VCLEFT_a306_handleDisconnectedF "Left body controller: a306 handle disconnected f";
CM_ SG_ 864 VCLEFT_a307_handleDisconnectedR "Left body controller: a307 handle disconnected r";
CM_ SG_ 864 VCLEFT_a308_sirenMIA "Left body controller: a308 siren MIA";
CM_ SG_ 864 VCLEFT_a309_brakeSwitchFaulted "Left body controller: a309 brake switch faulted";
CM_ SG_ 864 VCLEFT_a310_mirrorFoldStall "Left body controller: a310 mirror fold stall";
CM_ SG_ 864 VCLEFT_a311_leftBrakeLightFault "Left body controller: a311 left brake light fault";
CM_ SG_ 864 VCLEFT_a312_leftTailLightFault "Left body controller: a312 left tail light fault";
CM_ SG_ 864 VCLEFT_a313_leftFootwellLightFau "Left body controller: a313 left footwell light fault";
CM_ SG_ 864 VCLEFT_a314_leftMapPocketLightFa "Left body controller: a314 left map pocket light fault";
CM_ SG_ 864 VCLEFT_a315_leftInteriorTrunkLig "Left body controller: a315 left interior trunk light fault";
CM_ SG_ 864 VCLEFT_a316_mirrorPrematureFoldS "Left body controller: a316 mirror premature fold stall";
CM_ SG_ 864 VCLEFT_a317_epbmLimpModeEnabled "Left body controller: a317 epbm limp mode enabled";
CM_ SG_ 864 VCLEFT_a318_trailerIncorrectConf "Left body controller: a318 trailer incorrect config";
CM_ SG_ 864 VCLEFT_a319_brakePressPrimaryInp "Left body controller: a319 brake press primary input faulted";
CM_ SG_ 864 VCLEFT_a320_windowReportCrackedA "Left body controller: a320 window report cracked at trim clear";
CM_ SG_ 864 VCLEFT_a321_windowRezeroedDebugF "Left body controller: a321 window rezeroed debug f";
CM_ SG_ 864 VCLEFT_a322_windowRezeroedDebugR "Left body controller: a322 window rezeroed debug r";
CM_ SG_ 864 VCLEFT_a323_mirrorCalibrated "Left body controller: a323 mirror calibrated";
CM_ SG_ 864 VCLEFT_a324_mirrorHeatFault "Left body controller: a324 mirror heat fault";
CM_ SG_ 864 VCLEFT_a325_hghtSnsrUnplgdFL "Left body controller: a325 hght snsr unplgd FL";
CM_ SG_ 864 VCLEFT_a326_hghtSnsrUnplgdRL "Left body controller: a326 hght snsr unplgd RL";
CM_ SG_ 864 VCLEFT_a327_hghtSnsrFaultFL "Left body controller: a327 hght snsr fault FL";
CM_ SG_ 864 VCLEFT_a328_hghtSnsrFaultRL "Left body controller: a328 hght snsr fault RL";
CM_ SG_ 864 VCLEFT_a329_noRideHeightCalib "Left body controller: a329 no ride height calib";
CM_ SG_ 864 VCLEFT_a330_shortDropFailedF "Left body controller: a330 short drop failed f";
CM_ SG_ 864 VCLEFT_a331_shortDropFailedR "Left body controller: a331 short drop failed r";
CM_ SG_ 864 VCLEFT_a332_intrusionSensorMIA "Left body controller: a332 intrusion sensor MIA";
CM_ SG_ 864 VCLEFT_a333_overheadConsoleMIA "Left body controller: a333 overhead console MIA";
CM_ SG_ 864 VCLEFT_a334_overheadConsoleInter "Left body controller: a334 overhead console internal fault";
CM_ SG_ 864 VCLEFT_a335_intrusionSensorInter "Left body controller: a335 intrusion sensor internal fault";
CM_ SG_ 864 VCLEFT_a336_windowDropRevThermal "Left body controller: a336 window drop rev thermal f";
CM_ SG_ 864 VCLEFT_a337_windowDropRevThermal "Left body controller: a337 window drop rev thermal r";
CM_ SG_ 864 VCLEFT_a338_trailerLightControll "Left body controller: a338 trailer light controller MIA";
CM_ SG_ 864 VCLEFT_a339_trailerLeftTurnLight "Left body controller: a339 trailer left turn light not detected";
CM_ SG_ 864 VCLEFT_a340_trailerRightTurnLigh "Left body controller: a340 trailer right turn light not detected";
CM_ SG_ 864 VCLEFT_a341_trailerLightFault "Left body controller: a341 trailer light fault";
CM_ SG_ 864 VCLEFT_a342_trailerLightControll "Left body controller: a342 trailer light controller fault";
CM_ SG_ 864 VCLEFT_a345_chargePortPowerCycli "Left body controller: a345 charge port power cycling";
CM_ SG_ 864 VCLEFT_a346_eFuseMgmtVbatFused2 "Left body controller: a346 e fuse mgmt vbat fused2";
CM_ SG_ 864 VCLEFT_a347_nonContMonitorCleare "Left body controller: a347 non cont monitor cleared DBG";
CM_ SG_ 864 VCLEFT_a348_CPSleepOvercurrent "Left body controller: a348 CP sleep overcurrent";
CM_ SG_ 864 VCLEFT_a349_CPSleepUndervoltage "Left body controller: a349 CP sleep undervoltage";
CM_ SG_ 864 VCLEFT_a350_ensOutOfRange "Left body controller: a350 ens out of range";
CM_ SG_ 864 VCLEFT_a351_debugLiftgateCurrent "Left body controller: a351 debug liftgate current spike";
CM_ SG_ 864 VCLEFT_a352_liftgateClosingLatch "Left body controller: a352 liftgate closing latch entry failed";
CM_ SG_ 864 VCLEFT_a353_eFuseMgmtSteeringCol "Left body controller: a353 e fuse mgmt steering column";
CM_ SG_ 864 VCLEFT_a354_eFuseMgmtLiftGate "Left body controller: a354 e fuse mgmt lift gate";
CM_ SG_ 864 VCLEFT_a355_liftgateUnexpectedSt "Left body controller: a355 liftgate unexpected stop";
CM_ SG_ 864 VCLEFT_a356_liftgateFactoryTest "Left body controller: a356 liftgate factory test";
CM_ SG_ 864 VCLEFT_a357_liftgateUncalibrated "Left body controller: a357 liftgate uncalibrated";
CM_ SG_ 864 VCLEFT_a358_debugLiftgateCurrent "Left body controller: a358 debug liftgate current dropout";
CM_ SG_ 864 VCLEFT_a359_liftgateLatchExitNoP "Left body controller: a359 liftgate latch exit no position change";
CM_ SG_ 864 VCLEFT_a360_detectedStationaryWh "Left body controller: a360 detected stationary while moving";
CM_ SG_ 864 VCLEFT_a361_stationaryThresholds "Left body controller: a361 stationary thresholds incorrect";
CM_ SG_ 864 VCLEFT_a362_movingThresholdsInco "Left body controller: a362 moving thresholds incorrect";
CM_ SG_ 864 VCLEFT_a363_liftgateOpenAngleSet "Left body controller: a363 liftgate open angle set req";
CM_ SG_ 864 VCLEFT_a365_pitchUnlatchDisabled "Left body controller: a365 pitch unlatch disabled";
CM_ SG_ 864 VCLEFT_a366_liftgateLatchEntryDB "Left body controller: a366 liftgate latch entry DBG";
CM_ SG_ 864 VCLEFT_a370_seat2RowPitchUnlatch "Left body controller: a370 seat2 row pitch unlatched";
CM_ SG_ 864 VCLEFT_a371_seat2RowTrackUnlatch "Left body controller: a371 seat2 row track unlatched";
CM_ SG_ 864 VCLEFT_a372_seat2RowBackrestUnla "Left body controller: a372 seat2 row backrest unlatched";
CM_ SG_ 864 VCLEFT_a373_windowSwOpenReqInDog "Left body controller: a373 window sw open req in dog mode";
CM_ SG_ 864 VCLEFT_a374_trailerLightFaultMod "Left body controller: a374 trailer light fault model y";
CM_ SG_ 864 VCLEFT_a375_windowPinchOverrideN "Left body controller: a375 window pinch override nudge";
CM_ SG_ 864 VCLEFT_a376_seat2RowBridgeCurren "Left body controller: a376 seat2 row bridge current exceeded";
CM_ SG_ 864 VCLEFT_a380_steerColThermalLimit "Left body controller: a380 steer col thermal limited";
CM_ SG_ 864 VCLEFT_a381_pitchEstimation1 "Left body controller: a381 pitch estimation1";
CM_ SG_ 864 VCLEFT_a382_pitchEstimation2 "Left body controller: a382 pitch estimation2";
CM_ SG_ 864 VCLEFT_a383_steerColInOutMotorSt "Left body controller: a383 steer col in out motor stall current";
CM_ SG_ 864 VCLEFT_a384_steerColUpDownMotorS "Left body controller: a384 steer col up down motor stall current";
CM_ SG_ 864 VCLEFT_a385_steerColInOutMotorUn "Left body controller: a385 steer col in out motor under current";
CM_ SG_ 864 VCLEFT_a386_steerColUpDownMotorU "Left body controller: a386 steer col up down motor under current";
CM_ SG_ 864 VCLEFT_a387_steerColInOutMotorEn "Left body controller: a387 steer col in out motor encoder stalled";
CM_ SG_ 864 VCLEFT_a388_steerColUpDownMotorE "Left body controller: a388 steer col up down motor encoder stalled";
CM_ SG_ 864 VCLEFT_a389_steerColInOutEncoder "Left body controller: a389 steer col in out encoder out of range";
CM_ SG_ 864 VCLEFT_a390_steerColUpDownEncode "Left body controller: a390 steer col up down encoder out of range";
CM_ SG_ 864 VCLEFT_a391_pitchEstimationImpla "Left body controller: a391 pitch estimation implausible";
CM_ SG_ 864 VCLEFT_a392_pitchEstimationGPSIm "Left body controller: a392 pitch estimation GPS improved reinit";
CM_ SG_ 864 VCLEFT_a393_pitchEstimationNoGPS "Left body controller: a393 pitch estimation no GPS fusion";
CM_ SG_ 864 VCLEFT_a394_swsTouchTooNegativeD "Left body controller: a394 sws touch too negative delta";
CM_ SG_ 864 VCLEFT_a395_swsTouchAdcCheckFail "Left body controller: a395 sws touch adc check fail";
CM_ SG_ 864 VCLEFT_a396_swsTouchStuckFault "Left body controller: a396 sws touch stuck fault";
CM_ SG_ 864 VCLEFT_a397_swsTouchOutOfRangeFa "Left body controller: a397 sws touch out of range fault";
CM_ SG_ 864 VCLEFT_a398_swsTouchNvmFault "Left body controller: a398 sws touch nvm fault";
CM_ SG_ 864 VCLEFT_a399_swsTouchNoisyBaselin "Left body controller: a399 sws touch noisy baseline initialization";
CM_ SG_ 864 VCLEFT_a400_swsTouchDebouncedPro "Left body controller: a400 sws touch debounced processing error";
CM_ SG_ 864 VCLEFT_a401_swsForceTestPatternV "Left body controller: a401 sws force test pattern violation";
CM_ SG_ 864 VCLEFT_a402_swsForceOutOfRange "Left body controller: a402 sws force out of range";
CM_ SG_ 864 VCLEFT_a403_swsForceAdcCheckFail "Left body controller: a403 sws force adc check fail";
CM_ SG_ 864 VCLEFT_a404_swsForceI2cError "Left body controller: a404 sws force i2c error";
CM_ SG_ 864 VCLEFT_a405_swsForceCalibrationF "Left body controller: a405 sws force calibration fault";
CM_ SG_ 864 VCLEFT_a406_swsForceParametersFa "Left body controller: a406 sws force parameters fault";
CM_ SG_ 864 VCLEFT_a407_swsForceNvmFault "Left body controller: a407 sws force nvm fault";
CM_ SG_ 864 VCLEFT_a408_swsForceTouchSensorF "Left body controller: a408 sws force touch sensor fault";
CM_ SG_ 864 VCLEFT_a409_swsScrollWheelPushFa "Left body controller: a409 sws scroll wheel push fault";
CM_ SG_ 864 VCLEFT_a410_swsScrollWheelTiltFa "Left body controller: a410 sws scroll wheel tilt fault";
CM_ SG_ 864 VCLEFT_a411_swsScrollWheelScroll "Left body controller: a411 sws scroll wheel scroll fault";
CM_ SG_ 864 VCLEFT_a412_leftBrakeTailLightFa "Left body controller: a412 left brake tail light fault";
CM_ SG_ 864 VCLEFT_a413_undervoltageSelfTest "Left body controller: a413 undervoltage self test failure";
CM_ SG_ 864 VCLEFT_a414_swsHapticMotorFault "Left body controller: a414 sws haptic motor fault";
CM_ SG_ 864 VCLEFT_a415_swsMiscFault "Left body controller: a415 sws misc fault";
CM_ SG_ 864 VCLEFT_a416_fohmTouchAdcCheckFai "Left body controller: a416 fohm touch adc check fail";
CM_ SG_ 864 VCLEFT_a417_fohmTouchOutOfRangeF "Left body controller: a417 fohm touch out of range fault";
CM_ SG_ 864 VCLEFT_a418_fohmTouchVarianceFai "Left body controller: a418 fohm touch variance fail";
CM_ SG_ 864 VCLEFT_a419_fohmTouchStuck "Left body controller: a419 fohm touch stuck";
CM_ SG_ 864 VCLEFT_a420_fohmTouchSensorsImpl "Left body controller: a420 fohm touch sensors implausible";
CM_ SG_ 864 VCLEFT_a421_fohmForceOutOfRangeF "Left body controller: a421 fohm force out of range fault";
CM_ SG_ 864 VCLEFT_a422_undervoltageSelfTest "Left body controller: a422 undervoltage self test stuck off";
CM_ SG_ 864 VCLEFT_a423_fohmForceI2cError "Left body controller: a423 fohm force i2c error";
CM_ SG_ 864 VCLEFT_a424_fohmAmberLEDFault "Left body controller: a424 fohm amber LED fault";
CM_ SG_ 864 VCLEFT_a425_fohmVanityPowerSuppl "Left body controller: a425 fohm vanity power supply fault";
CM_ SG_ 864 VCLEFT_a426_seatAbuseMotorWarn "Left body controller: a426 seat abuse motor warn";
CM_ SG_ 864 VCLEFT_a427_seatAbuseMotorStop "Left body controller: a427 seat abuse motor stop";
CM_ SG_ 864 VCLEFT_a428_seatAbuseBufferWarn "Left body controller: a428 seat abuse buffer warn";
CM_ SG_ 864 VCLEFT_a429_seatAbuseBufferFull "Left body controller: a429 seat abuse buffer full";
CM_ SG_ 864 VCLEFT_a430_fohmRearDomeLightPow "Left body controller: a430 fohm rear dome light power supply fault";
CM_ SG_ 864 VCLEFT_a431_fohmVbatFault "Left body controller: a431 fohm vbat fault";
CM_ SG_ 864 VCLEFT_a432_fohmMiscFault "Left body controller: a432 fohm misc fault";
CM_ SG_ 864 VCLEFT_a433_fohmForceCalibration "Left body controller: a433 fohm force calibration invalid";
CM_ SG_ 864 VCLEFT_a434_swsScrollWheelPushDa "Left body controller: a434 sws scroll wheel push data";
CM_ SG_ 864 VCLEFT_a435_swsNoReasonTouchFaul "Left body controller: a435 sws no reason touch fault";
CM_ SG_ 864 VCLEFT_a436_swsNoReasonForceFaul "Left body controller: a436 sws no reason force fault";
CM_ SG_ 864 VCLEFT_a437_hvacRearLeftVertical "Left body controller: a437 hvac rear left vertical driver faulted";
CM_ SG_ 864 VCLEFT_a438_hvacRearLeftLateralD "Left body controller: a438 hvac rear left lateral driver faulted";
CM_ SG_ 864 VCLEFT_a439_hvacRearRightVertica "Left body controller: a439 hvac rear right vertical driver faulted";
CM_ SG_ 864 VCLEFT_a440_hvacRearRightLateral "Left body controller: a440 hvac rear right lateral driver faulted";
CM_ SG_ 864 VCLEFT_a441_prndMIA "Left body controller: a441 prnd MIA";
CM_ SG_ 864 VCLEFT_a442_swsLongTouchEvent "Left body controller: a442 sws long touch event";
CM_ SG_ 864 VCLEFT_a444_drv8703Fault "Left body controller: a444 drv8703 fault";
CM_ SG_ 864 VCLEFT_a445_drv8703SpiFaultDBG "Left body controller: a445 drv8703 spi fault DBG";
CM_ SG_ 864 VCLEFT_a446_trailerAuxReversePow "Left body controller: a446 trailer aux reverse power";
CM_ SG_ 864 VCLEFT_a447_steeringColInOutEnds "Left body controller: a447 steering col in out endstop cal";
CM_ SG_ 864 VCLEFT_a448_steeringColUpDownEnd "Left body controller: a448 steering col up down endstop cal";
CM_ SG_ 864 VCLEFT_a449_steerColInOutMotorSh "Left body controller: a449 steer col in out motor shadow algo reset offset";
CM_ SG_ 864 VCLEFT_a450_steerColUpDownMotorS "Left body controller: a450 steer col up down motor shadow algo reset offset";
CM_ SG_ 864 VCLEFT_a451_wirelessChargerMIA "Left body controller: a451 wireless charger MIA";
CM_ SG_ 864 VCLEFT_a453_liftgatePinchDetecte "Left body controller: a453 liftgate pinch detected";
CM_ SG_ 864 VCLEFT_a454_wirelessChargerFault "Left body controller: a454 wireless charger fault";
CM_ SG_ 864 VCLEFT_a455_liftgateUnexpectedSh "Left body controller: a455 liftgate unexpected shutface sw pressed";
CM_ SG_ 864 VCLEFT_a460_etcDebug "Left body controller: a460 etc debug";
CM_ SG_ 864 VCLEFT_a466_hvac2RLeftAirwaveVer "Left body controller: a466 hvac2 r left airwave vertical fault";
CM_ SG_ 864 VCLEFT_a467_hvac2RLeftAirwaveVer "Left body controller: a467 hvac2 r left airwave vertical warning";
CM_ SG_ 864 VCLEFT_a468_hvac2RLeftAirwaveVer "Left body controller: a468 hvac2 r left airwave vertical uncalib";
CM_ SG_ 864 VCLEFT_a469_hvac2RLeftAirwaveLat "Left body controller: a469 hvac2 r left airwave lateral fault";
CM_ SG_ 864 VCLEFT_a470_hvac2RLeftAirwaveLat "Left body controller: a470 hvac2 r left airwave lateral warning";
CM_ SG_ 864 VCLEFT_a471_hvac2RLeftAirwaveLat "Left body controller: a471 hvac2 r left airwave lateral uncalib";
CM_ SG_ 864 VCLEFT_a472_hvac2RRightAirwaveVe "Left body controller: a472 hvac2 r right airwave vertical fault";
CM_ SG_ 864 VCLEFT_a473_hvac2RRightAirwaveVe "Left body controller: a473 hvac2 r right airwave vertical warning";
CM_ SG_ 864 VCLEFT_a474_hvac2RRightAirwaveVe "Left body controller: a474 hvac2 r right airwave vertical uncalib";
CM_ SG_ 864 VCLEFT_a475_hvac2RRightAirwaveLa "Left body controller: a475 hvac2 r right airwave lateral fault";
CM_ SG_ 864 VCLEFT_a476_hvac2RRightAirwaveLa "Left body controller: a476 hvac2 r right airwave lateral warning";
CM_ SG_ 864 VCLEFT_a477_hvac2RRightAirwaveLa "Left body controller: a477 hvac2 r right airwave lateral uncalib";
CM_ SG_ 864 VCLEFT_a478_BPillarCameraHeaterF "Left body controller: a478 b pillar camera heater fault";
CM_ SG_ 864 VCLEFT_a480_vnf1048Fault "Left body controller: a480 vnf1048 fault";
CM_ SG_ 864 VCLEFT_a481_vnf1048SelfTestFailu "Left body controller: a481 vnf1048 self test failure";
CM_ SG_ 864 VCLEFT_a482_NCV77XXFault "Left body controller: a482 NCV77 XX fault";
CM_ SG_ 864 VCLEFT_a483_leftTurnLightFaultUs "Left body controller: a483 left turn light fault user";
CM_ SG_ 864 VCLEFT_a484_leftBrakeLightFaultU "Left body controller: a484 left brake light fault user";
CM_ SG_ 864 VCLEFT_a485_uvSelfTestLoadUnatte "Left body controller: a485 uv self test load unattempted on dbg";
CM_ SG_ 864 VCLEFT_a488_undervoltageSelfTest "Left body controller: a488 undervoltage self test stuck on debug";
CM_ SG_ 864 VCLEFT_a489_undervoltageSelfTest "Left body controller: a489 undervoltage self test stuck on";
CM_ SG_ 864 VCLEFT_a490_vehicleOccupiedOnOTA "Left body controller: a490 vehicle occupied on OTA start";
CM_ SG_ 864 VCLEFT_a493_12vSocketFrontEFuseT "Left body controller: a493 12v socket front e fuse trip";
CM_ SG_ 864 VCLEFT_a494_12vSocketRearEFuseTr "Left body controller: a494 12v socket rear e fuse trip";
CM_ SG_ 864 VCLEFT_a497_CANMsgMACVerificatio "Left body controller: a497 CAN msg MAC verification key not provisioned";
CM_ SG_ 864 VCLEFT_a498_CANMsgMACVerificatio "Left body controller: a498 CAN msg MAC verification failure";
CM_ SG_ 864 VCLEFT_a499_epbmInvalidateCdp "Left body controller: a499 epbm invalidate cdp";
CM_ SG_ 864 VCLEFT_a500_eFuseASICStateMismat "Left body controller: a500 e fuse ASIC state mismatch";
CM_ SG_ 864 VCLEFT_a501_vnf1048Configuration "Left body controller: a501 vnf1048 configuration mismatch";
CM_ SG_ 864 VCLEFT_a510_3RowSeatUncalibrated "Left body controller: a510 3 row seat uncalibrated";
CM_ SG_ 864 VCLEFT_a511_3RowSeatPositionNons "Left body controller: a511 3 row seat position nonsensical";
CM_ SG_ 864 VCLEFT_a512_3RowSeatAbsPosOffset "Left body controller: a512 3 row seat abs pos offset applied";
CM_ SG_ 864 VCLEFT_a513_3RowSeatObstacleDete "Left body controller: a513 3 row seat obstacle detected";
CM_ SG_ 864 VCLEFT_a514_3RowSeatTempHigh "Left body controller: a514 3 row seat temp high";
CM_ SG_ 864 VCLEFT_a515_3RowSeatAbsPosSensor "Left body controller: a515 3 row seat abs pos sensor transition dbg";
CM_ SG_ 864 VCLEFT_a516_3RowSeatStatsFromLas "Left body controller: a516 3 row seat stats from last state dbg";
CM_ SG_ 864 VCLEFT_a517_3RowSeatRequestWhile "Left body controller: a517 3 row seat request while uncalibrated";
CM_ SG_ 864 VCLEFT_a518_3RowSeatClashAvoidan "Left body controller: a518 3 row seat clash avoidance blocked";
CM_ SG_ 864 VCLEFT_a519_3RowSeatOverfolded "Left body controller: a519 3 row seat overfolded";
CM_ SG_ 864 VCLEFT_a520_configMismatch "Left body controller: a520 config mismatch";
CM_ SG_ 864 VCLEFT_a521_seatHeatPadUnexpecte "Left body controller: a521 seat heat pad unexpected voltage";
CM_ SG_ 864 VCLEFT_a522_trailerLightUnexpect "Left body controller: a522 trailer light unexpected voltage";
CM_ SG_ 864 VCLEFT_a523_eFuseThresholdsIncor "Left body controller: a523 e fuse thresholds incorrect";
CM_ SG_ 864 VCLEFT_a525_LVBatterySWMisconfig "Left body controller: a525 LV battery SW misconfiguration";
CM_ SG_ 864 VCLEFT_a526_pcbaOverTemperature "Left body controller: a526 pcba over temperature";
CM_ SG_ 864 VCLEFT_a527_continuousFeedUnexpe "Left body controller: a527 continuous feed unexpected voltage";
CM_ SG_ 864 VCLEFT_a528_unableToRunStuckOnTe "Left body controller: a528 unable to run stuck on test";
CM_ SG_ 864 VCLEFT_a536_trunkFoldFlatSwitchF "Left body controller: a536 trunk fold flat switch fault";
CM_ SG_ 864 VCLEFT_a545_LVBatteryTypeUnknown "Left body controller: a545 LV battery type unknown";
CM_ SG_ 864 VCLEFT_a546_mirrorFoldTypeChange "Left body controller: a546 mirror fold type changed";
CM_ SG_ 864 VCLEFT_a550_ambientTempDelta "Left body controller: a550 ambient temp delta";
CM_ SG_ 864 VCLEFT_a551_interiorDoorRequestI "Left body controller: a551 interior door request inhibited";
CM_ SG_ 864 VCLEFT_a554_RCM2_MIA "Left body controller: a554 RCM2 MIA";
CM_ SG_ 864 VCLEFT_a555_steeringWheelHeaterC "Left body controller: a555 steering wheel heater compromised";
CM_ SG_ 864 VCLEFT_a560_2RowSeatUncalibrated "Left body controller: a560 2 row seat uncalibrated";
CM_ SG_ 864 VCLEFT_a561_2RowSeatPositionNons "Left body controller: a561 2 row seat position nonsensical";
CM_ SG_ 864 VCLEFT_a562_2RowSeatAbsPosOffset "Left body controller: a562 2 row seat abs pos offset applied";
CM_ SG_ 864 VCLEFT_a563_2RowSeatObstacleDete "Left body controller: a563 2 row seat obstacle detected";
CM_ SG_ 864 VCLEFT_a564_2RowSeatTempHigh "Left body controller: a564 2 row seat temp high";
CM_ SG_ 864 VCLEFT_a565_2RowSeatAbsPosSensor "Left body controller: a565 2 row seat abs pos sensor transition dbg";
CM_ SG_ 864 VCLEFT_a566_2RowSeatStatsFromLas "Left body controller: a566 2 row seat stats from last state dbg";
CM_ SG_ 864 VCLEFT_a567_2RowSeatRequestWhile "Left body controller: a567 2 row seat request while uncalibrated";
CM_ SG_ 864 VCLEFT_a568_2RowSeatClashAvoidan "Left body controller: a568 2 row seat clash avoidance blocked";
CM_ SG_ 864 VCLEFT_a569_2RowSeatOverfolded "Left body controller: a569 2 row seat overfolded";
CM_ SG_ 864 VCLEFT_a570_seatHeatDisabledF "Left body controller: a570 seat heat disabled f";
CM_ SG_ 864 VCLEFT_a571_seatHeatDisabledRear "Left body controller: a571 seat heat disabled rear l";
CM_ SG_ 864 VCLEFT_a572_seatHeatDisabledRear "Left body controller: a572 seat heat disabled rear c";
CM_ SG_ 864 VCLEFT_a573_seatHeatDisabledRear "Left body controller: a573 seat heat disabled rear r";
CM_ SG_ 864 VCLEFT_a574_2RowSeatStatsFromLas "Left body controller: a574 2 row seat stats from last state dbg2";
CM_ SG_ 864 VCLEFT_a575_3RowSeatStatsFromLas "Left body controller: a575 3 row seat stats from last state dbg2";
CM_ SG_ 864 VCLEFT_a576_liftgateStrutPositio "Left body controller: a576 liftgate strut position mismatch";
CM_ SG_ 864 VCLEFT_a577_bsiHardwareIssue "Left body controller: a577 bsi hardware issue";
CM_ SG_ 864 VCLEFT_a578_RGBLightFault "Left body controller: a578 RGB light fault";
CM_ SG_ 864 VCLEFT_a579_leftSteeringWheelCtr "Left body controller: a579 left steering wheel ctrl type mismatch";
CM_ SG_ 864 VCLEFT_a580_rightSteeringWheelCt "Left body controller: a580 right steering wheel ctrl type mismatch";
CM_ SG_ 864 VCLEFT_a581_reverseLightFault "Left body controller: a581 reverse light fault";
CM_ SG_ 864 VCLEFT_a582_seat2RControllerTrip "Left body controller: a582 seat2 r controller trip";
CM_ SG_ 864 VCLEFT_a583_doorRemoteUnlatchedF "Left body controller: a583 door remote unlatched front";
CM_ SG_ 864 VCLEFT_a584_doorRemoteUnlatchedR "Left body controller: a584 door remote unlatched rear";
CM_ SG_ 864 VCLEFT_a585_doorRemoteUnlatchFai "Left body controller: a585 door remote unlatch failed front";
CM_ SG_ 864 VCLEFT_a586_doorRemoteUnlatchFai "Left body controller: a586 door remote unlatch failed rear";
CM_ SG_ 864 VCLEFT_a587_VCSEAT2L_MIA "Left body controller: a587 VCSEAT2 l MIA";
CM_ SG_ 864 VCLEFT_a589_lipcCanFault "Left body controller: a589 lipc can fault";
CM_ SG_ 864 VCLEFT_a590_seatEncStallThighSup "Left body controller: a590 seat enc stall thigh support";
CM_ SG_ 864 VCLEFT_a591_seatCurrUnderThighSu "Left body controller: a591 seat curr under thigh support";
CM_ SG_ 864 VCLEFT_a592_seatUncalThighSuppor "Left body controller: a592 seat uncal thigh support";
CM_ SG_ 864 VCLEFT_a593_seatEncOverThighSupp "Left body controller: a593 seat enc over thigh support";
CM_ SG_ 864 VCLEFT_a594_seatThighSupportStal "Left body controller: a594 seat thigh support stall debug";
CM_ SG_ 864 VCLEFT_a595_seatThighSupportHCEn "Left body controller: a595 seat thigh support HC enc stl dbg";
CM_ SG_ 864 VCLEFT_a596_frontDoorLatchUnexpe "Left body controller: a596 front door latch unexpected voltage";
CM_ SG_ 864 VCLEFT_a597_rearDoorLatchUnexpec "Left body controller: a597 rear door latch unexpected voltage";
CM_ SG_ 864 VCLEFT_a599_LVBatteryTypeUnsuppo "Left body controller: a599 LV battery type unsupported";
CM_ SG_ 864 VCLEFT_a601_wakeToOpenDoorDbg "Left body controller: a601 wake to open door dbg";
CM_ SG_ 864 VCLEFT_a605_CANMsgMACVerificatio "Left body controller: a605 CAN msg MAC verification key mismatch";
CM_ SG_ 864 VCLEFT_a617_APP_MIA "Left body controller: a617 APP MIA";
CM_ BO_ 258 "Left body controller message: door status; frame length observed on a vehicle bus";
CM_ SG_ 258 VCLEFT_doorClosureStatusFront "Status of the door from a closures perspective; raw 0 = signal not available (SNA)";
CM_ SG_ 258 VCLEFT_doorClosureStatusRear "Status of the door from a closures perspective; raw 0 = signal not available (SNA)";
CM_ SG_ 258 VCLEFT_frontLatchSwitch "State of front left door latch switch representing door open/closed. 0 is open and 1 is closed";
CM_ SG_ 258 VCLEFT_rearLatchSwitch "State of rear left door latch switch representing door open/closed. 0 is open and 1 is closed";
CM_ SG_ 258 VCLEFT_frontHandlePulled "Left body controller: front handle pulled";
CM_ SG_ 258 VCLEFT_rearHandlePulled "Left body controller: rear handle pulled";
CM_ SG_ 258 VCLEFT_frontRelActuatorSwitch "State of front left door latch switch representing latch arm/unarmed. Disarms while door handle is pulled.";
CM_ SG_ 258 VCLEFT_rearRelActuatorSwitch "State of rear left door latch switch representing latch arm/unarmed. Disarms while door handle is pulled";
CM_ SG_ 258 VCLEFT_frontLatchStatus "Status of left front door latch; raw 0 = signal not available (SNA)";
CM_ SG_ 258 VCLEFT_rearLatchStatus "Status of rear left door latch; raw 0 = signal not available (SNA)";
CM_ SG_ 258 VCLEFT_lastDoorReqSourceFront "last source of front door open request";
CM_ SG_ 258 VCLEFT_lastDoorReqSourceRear "last source of rear door open request";
CM_ SG_ 258 VCLEFT_frontIntSwitchFaulted "Indicates if the front door interior button is faulted";
CM_ SG_ 258 VCLEFT_rearIntSwitchFaulted "Indicates if the rear door interior button is faulted";
CM_ SG_ 258 VCLEFT_frontIntSwitchPressed "Left body controller: front int switch pressed";
CM_ SG_ 258 VCLEFT_rearIntSwitchPressed "Left body controller: rear int switch pressed";
CM_ SG_ 258 VCLEFT_mirrorTiltXPosition "Value representing left side view mirror tilt horizontal position";
CM_ SG_ 258 VCLEFT_mirrorTiltYPosition "Value representing left side view mirror tilt vertical position";
CM_ SG_ 258 VCLEFT_mirrorState "State of the left side view mirror.";
CM_ SG_ 258 VCLEFT_mirrorFoldState "Fold state for the left side view mirror";
CM_ SG_ 258 VCLEFT_mirrorRecallState "State of Mirror Recall.";
CM_ SG_ 258 VCLEFT_mirrorHeatState "Left body controller: mirror heat state; raw 0 = signal not available (SNA)";
CM_ SG_ 258 VCLEFT_rearHandlePulledPersist "Left body controller: rear handle pulled persist";
CM_ SG_ 258 VCLEFT_frontHandlePulledPersist "Left body controller: front handle pulled persist";
CM_ SG_ 258 VCLEFT_mirrorDipped "Reports if the side view mirrors in are in the dipped position.";
CM_ BO_ 290 "Left body controller message: door status2; frame length observed on a vehicle bus";
CM_ SG_ 290 VCLEFT_doorStatus2Index "Left body controller: door status2 index";
CM_ SG_ 290 VCLEFT_rearLatchRelDuty "Rear left door latch motor duty cycle. Position from firmware; message assignment inferred.";
CM_ SG_ 290 VCLEFT_vehicleInMotion "Position from firmware; message assignment inferred.";
CM_ SG_ 290 VCLEFT_frontDoorState "Status of front left door. Position from firmware; message assignment inferred.";
CM_ SG_ 290 VCLEFT_rearDoorState "Status of rear left door. Position from firmware; message assignment inferred.";
CM_ SG_ 290 VCLEFT_frontHandleRawStatus "State machine state that represents physical state of the front left door handle for debugging. Position from firmware; message assignment inferred.";
CM_ SG_ 290 VCLEFT_rearHandleRawStatus "State machine state that represents physical state of the rear left door handle for debugging. Position from firmware; message assignment inferred.";
CM_ SG_ 290 VCLEFT_frontHandleDebounceStatus "State machine state that represents physical state of the front left door handle for debugging. Position from firmware; message assignment inferred.";
CM_ SG_ 290 VCLEFT_rearHandleDebounceStatus "State machine state that represents physical state of the front left door handle for debugging. Position from firmware; message assignment inferred.";
CM_ SG_ 290 VCLEFT_frontHandle5vEnable "Status of power going to the front left exterior door handle sensor. Position from firmware; message assignment inferred.";
CM_ SG_ 290 VCLEFT_rearHandle5vEnable "Status of power going to the rear left exterior door handle sensor. Position from firmware; message assignment inferred.";
CM_ SG_ 290 VCLEFT_BPillarCameraHeaterCurren "Current drawn by the left b-pillar camera heater; raw 63 = signal not available (SNA)";
CM_ SG_ 290 VCLEFT_mirrorTiltXOffset "Communicates post calibration position offset of left side view mirror tilt horizontal position";
CM_ SG_ 290 VCLEFT_mirrorTiltYOffset "Communicates post calibration position offset of left side view mirror tilt vertical position";
CM_ BO_ 626 "Left body controller message: epbm debug; frame length observed on a vehicle bus";
CM_ SG_ 626 VCLEFT_epbmDebugIndex "Left body controller: epbm debug index";
CM_ SG_ 626 VCLEFT_epbmCaliperState "Left body controller: epbm caliper state";
CM_ SG_ 626 VCLEFT_epbmMotorEnabled "Left body controller: epbm motor enabled";
CM_ SG_ 626 VCLEFT_epbMotorCurrent "Left body controller: epb motor current";
CM_ SG_ 626 VCLEFT_epbmApplyVoltage "Left body controller: epbm apply voltage";
CM_ SG_ 626 VCLEFT_epbmReleaseVoltage "Left body controller: epbm release voltage";
CM_ SG_ 626 VCLEFT_summonFaultReason "Electronic Parking Brake Monitors error code associated with previous summon failure.";
CM_ SG_ 626 VCLEFT_epbSummonState "Electronic Parking Brake Monitors reading of Electronic Parking Brake's summon state.";
CM_ SG_ 626 VCLEFT_epbmSummonState "Electronic Parking Brake Monitors summon state.";
CM_ SG_ 626 VCLEFT_epbUnitStatus "Electronic Parking Brake Monitors reading of Electronic Parking Brake's state.";
CM_ SG_ 626 VCLEFT_epbmFaultStatus "Electronic Parking Brake Monitors fault state.";
CM_ SG_ 626 VCLEFT_epbFaultStatus "Electronic Parking Brake Monitors reading of Electronic Parking Brake's fault state.";
CM_ SG_ 626 VCLEFT_epbmSystemStatus "Electronic Parking Brake Monitors reading of Electronic Parking Brake's state.";
CM_ SG_ 626 VCLEFT_epbmAutonomyBehavior "Left body controller: epbm autonomy behavior";
CM_ BO_ 1186 "Left body controller message: etc bluetooth status; frame length from the layout, not yet observed on a vehicle bus";
CM_ SG_ 1186 VCLEFT_etcBluetoothStatus "Left body controller: etc bluetooth status";
CM_ BO_ 642 "Left body controller message: hvac blower feedback; frame length observed on a vehicle bus";
CM_ SG_ 642 VCLEFT_hvacBlowerFeedbackIndex "Left body controller: hvac blower feedback index";
CM_ SG_ 642 VCLEFT_hvacBlowerEnabled "Left body controller: hvac blower enabled";
CM_ SG_ 642 VCLEFT_hvacBlowerOutputDuty "Left body controller: hvac blower output duty; raw 127 = signal not available (SNA)";
CM_ SG_ 642 VCLEFT_hvacBlowerRPMTarget "Left body controller: hvac blower RPM target; raw 1023 = signal not available (SNA)";
CM_ SG_ 642 VCLEFT_hvacBlowerRPMActual "Blower speed feedback";
CM_ SG_ 642 VCLEFT_hvacBlowerTorque "Left body controller: hvac blower torque; raw 1023 = signal not available (SNA)";
CM_ SG_ 642 VCLEFT_hvacBlowerFETTemp "Left body controller: hvac blower FET temp; raw 127 = signal not available (SNA)";
CM_ SG_ 642 VCLEFT_hvacBlowerIDc "Left body controller: hvac blower i dc; raw 127 = signal not available (SNA)";
CM_ SG_ 642 VCLEFT_hvacBlowerInitd "Left body controller: hvac blower initd";
CM_ SG_ 642 VCLEFT_hvacBlowerFault "Left body controller: hvac blower fault";
CM_ SG_ 642 VCLEFT_hvacBlowerLimitFETTemps "Left body controller: hvac blower limit FET temps";
CM_ SG_ 642 VCLEFT_hvacBlowerPowerOn "Left body controller: hvac blower power on";
CM_ SG_ 642 VCLEFT_hvacBlowerMotorID "Reports the ID of the HVAC blower motor";
CM_ BO_ 770 "Left body controller message: info; frame length observed on a vehicle bus";
CM_ SG_ 770 VCLEFT_infoIndex "Left body controller: info index";
CM_ SG_ 770 VCLEFT_infoBuildType "Left body controller: info build type";
CM_ SG_ 770 VCLEFT_infoBuildConfigId "Left body controller: info build config id";
CM_ SG_ 770 VCLEFT_infoHardwareId "Left body controller: info hardware id";
CM_ SG_ 770 VCLEFT_infoComponentId "Left body controller: info component id";
CM_ SG_ 770 VCLEFT_infoPcbaId "Left body controller: info pcba id";
CM_ SG_ 770 VCLEFT_infoAssemblyId "Left body controller: info assembly id; raw 255 = signal not available (SNA)";
CM_ SG_ 770 VCLEFT_infoUsageId "Left body controller: info usage id";
CM_ SG_ 770 VCLEFT_infoSubUsageId "Left body controller: info sub usage id";
CM_ SG_ 770 VCLEFT_infoAppCrc "Left body controller: info app crc";
CM_ SG_ 770 VCLEFT_infoLUMBARLAppCRC "Left body controller: info LUMBARL app CRC";
CM_ SG_ 770 VCLEFT_infoAppGitHash "Left body controller: info app git hash";
CM_ SG_ 770 VCLEFT_infoBootGitHash "Left body controller: info boot git hash";
CM_ SG_ 770 VCLEFT_infoPlatformType "Left body controller: info platform type";
CM_ SG_ 770 VCLEFT_infoBootUdsProtoVersion "Left body controller: info boot uds proto version";
CM_ SG_ 770 VCLEFT_infoBootCrc "Left body controller: info boot crc";
CM_ BO_ 292 "Left body controller message: liftgate leader request; frame length from the layout, not yet observed on a vehicle bus";
CM_ SG_ 292 VCLEFT_liftgateRequestAction "Action of dual strut PLG requested by the leader";
CM_ SG_ 292 VCLEFT_liftgateRequestTargetDuty "Left body controller: liftgate request target duty";
CM_ SG_ 292 VCLEFT_liftgateRequestTargetAngl "Left body controller: liftgate request target angle";
CM_ SG_ 292 VCLEFT_liftgateRequestTargetPara "Left body controller: liftgate request target param";
CM_ SG_ 292 VCLEFT_adaptiveLiftgateControlMo "Indicates if adaptive liftgate control mode is active";
CM_ SG_ 292 VCLEFT_liftgateReqObsDetMode "Pinch mode requrest by the PLG leader";
CM_ SG_ 292 VCLEFT_liftgateReqResetStrutCoun "Set strut count reset request from the leader";
CM_ SG_ 292 VCLEFT_liftgateReqClearCal "Request follower strut ro clear it calibration";
CM_ SG_ 292 VCLEFT_liftgateTargetTerminalSpe "Left body controller: liftgate target terminal speed";
CM_ SG_ 292 VCLEFT_liftgateReqCoastPercent "Reports the percentage of time to coast the strut.";
CM_ SG_ 292 VCLEFT_liftgateReqDutyScale "Reports the amount to scale duty from current value to ramp to for a LATCH_CURRENT_SCALED request";
CM_ BO_ 322 "Left body controller message: liftgate status; frame length observed on a vehicle bus";
CM_ SG_ 322 VCLEFT_liftgateStatusIndex "Left body controller: liftgate status index";
CM_ SG_ 322 VCLEFT_liftgateState "State of the power liftgate";
CM_ SG_ 322 VCLEFT_liftgateStoppingCondition "Stopping condition for the power liftgate";
CM_ SG_ 322 VCLEFT_liftgateMvmntNotAllowedCo "Movement not allowed condition for the power liftgate";
CM_ SG_ 322 VCLEFT_liftgatePositionCalibrate "Liftgate calibrated";
CM_ SG_ 322 VCLEFT_liftgateUIChimeRequest "Request from the liftgate module to sound a UI chime";
CM_ SG_ 322 VCLEFT_liftgatePhysicalChimeRequ "Request from the liftgate module to sound a physical chime";
CM_ SG_ 322 VCLEFT_liftgateEstimatedStrutTem "Left body controller: liftgate estimated strut temp";
CM_ SG_ 322 VCLEFT_liftgateStaticStrutMode "Static strut mode based on its velocity; raw 0 = signal not available (SNA)";
CM_ SG_ 322 VCLEFT_liftgateRequestSource "Movement request source for the power liftgate";
CM_ SG_ 322 VCLEFT_liftgateNewHeightNudge "Left body controller: liftgate new height nudge";
CM_ SG_ 322 VCLEFT_liftgateNewSaveHeight "Newly saved height of liftgate tip at max open";
CM_ SG_ 322 VCLEFT_liftgateGeofenceState "State of the geofence save process";
CM_ SG_ 322 VCLEFT_liftgateCloseWarnChimeReq "Left body controller: liftgate close warn chime request";
CM_ SG_ 322 VCLEFT_liftgateAboveCrossoverAng "Left body controller: liftgate above crossover angle";
CM_ SG_ 322 VCLEFT_liftgateLatchRequest "Reqeusts the liftgate latch to perform an action";
CM_ SG_ 322 VCLEFT_liftgateStrutDutyCycle "Left body controller: liftgate strut duty cycle";
CM_ SG_ 322 VCLEFT_liftgateStrutCurrent "Left body controller: liftgate strut current";
CM_ SG_ 322 VCLEFT_liftgatePosition "Liftgate position";
CM_ SG_ 322 VCLEFT_liftgateSpeed "Left body controller: liftgate speed";
CM_ SG_ 322 VCLEFT_liftgateHeight "Height of the liftgate tip above the ground";
CM_ SG_ 322 VCLEFT_liftgatePositionDiff "Left body controller: liftgate position diff";
CM_ BO_ 994 "Left body controller message: light status; frame length observed on a vehicle bus";
CM_ SG_ 994 VCLEFT_brakeLightStatus "Status of rear left brake light source; raw 3 = signal not available (SNA)";
CM_ SG_ 994 VCLEFT_tailLightStatus "Status of left tail (rear position) light source; raw 3 = signal not available (SNA)";
CM_ SG_ 994 VCLEFT_turnSignalStatus "Status of rear left turn signal light source; raw 3 = signal not available (SNA)";
CM_ SG_ 994 VCLEFT_FLMapLightStatus "Status of front left overhead map light; raw 3 = signal not available (SNA)";
CM_ SG_ 994 VCLEFT_FRMapLightStatus "Status of front right overhead map light; raw 3 = signal not available (SNA)";
CM_ SG_ 994 VCLEFT_RLMapLightStatus "Status of rear left overhead map light; raw 3 = signal not available (SNA)";
CM_ SG_ 994 VCLEFT_RRMapLightStatus "Status of rear right overhead map light; raw 3 = signal not available (SNA)";
CM_ SG_ 994 VCLEFT_FLMapLightSwitchPressed "Status of front left overhead map light switch";
CM_ SG_ 994 VCLEFT_FRMapLightSwitchPressed "Status of front right overhead map light switch";
CM_ SG_ 994 VCLEFT_RLMapLightSwitchPressed "Status of rear left overhead map light switch";
CM_ SG_ 994 VCLEFT_RRMapLightSwitchPressed "Status of rear right overhead map light switch";
CM_ SG_ 994 VCLEFT_leftTurnTrailerLightStatu "The desired on/off state of the trailer left turn light; raw 3 = signal not available (SNA)";
CM_ SG_ 994 VCLEFT_rightTrnTrailerLightStatu "The desired on/off state of the trailer right turn light; raw 3 = signal not available (SNA)";
CM_ SG_ 994 VCLEFT_brakeTrailerLightStatus "The desired on/off state of the trailer brake light; raw 3 = signal not available (SNA)";
CM_ SG_ 994 VCLEFT_tailTrailerLightStatus "The desired on/off state of the trailer tail light; raw 3 = signal not available (SNA)";
CM_ SG_ 994 VCLEFT_fogTrailerLightStatus "The desired on/off state of the trailer fog light; raw 3 = signal not available (SNA)";
CM_ SG_ 994 VCLEFT_frontRideHeight "Left body controller: front ride height; raw 128 = signal not available (SNA)";
CM_ SG_ 994 VCLEFT_rearRideHeight "Left body controller: rear ride height; raw 128 = signal not available (SNA)";
CM_ SG_ 994 VCLEFT_leftDashRGBPowerRequest "Left body controller: left dash RGB power request";
CM_ SG_ 994 VCLEFT_rightDashRGBPowerRequest "Left body controller: right dash RGB power request";
CM_ SG_ 994 VCLEFT_trailerDetected "Trailer light detection status; raw 0 = signal not available (SNA)";
CM_ SG_ 994 VCLEFT_rideHeightSensorFault "Fault status of the front and rear ride height sensors";
CM_ SG_ 994 VCLEFT_reverseTrailerLightStatus "The desired on/off state of the trailer reverse light; raw 3 = signal not available (SNA)";
CM_ SG_ 994 VCLEFT_tailLightOutageStatus "Left body controller: tail light outage status";
CM_ SG_ 994 VCLEFT_reverseLightStatus "Status of left rear body side reverse light source; raw 3 = signal not available (SNA)";
CM_ SG_ 994 VCLEFT_thirdRowLeftMapLightSwitc "Reports the status of the third row left overhead map light switch";
CM_ SG_ 994 VCLEFT_thirdRowRightMapLightSwit "Reports the status of the third row right overhead map light switch";
CM_ BO_ 1802 "Left body controller message: logging0point1 hz; frame length observed on a vehicle bus";
CM_ SG_ 1802 VCLEFT_logging0point1HzIndex "Left body controller: logging0point1 hz index";
CM_ SG_ 1802 VCLEFT_leftBrakeTailLightCurrent "Current sensed by the left brake tail light HSD (high side driver); raw 511 = signal not available (SNA)";
CM_ SG_ 1802 VCLEFT_leftBrakeTailLightCu_0001 "State representing validity of the left brake tail light HSD (high side driver) current sense; raw 0 = signal not available (SNA)";
CM_ SG_ 1802 VCLEFT_leftRearTurnLightCurrent "Current sensed by the left rear turn signal HSD (high side driver); raw 511 = signal not available (SNA)";
CM_ SG_ 1802 VCLEFT_leftRearTurnLightCurrentS "State representing validity of the left rear turn signal HSD (high side driver) current sense; raw 0 = signal not available (SNA)";
CM_ SG_ 1802 VCLEFT_phoneTemperatureFL "Temperature of front left wireless phone charger (if installed); raw 128 = signal not available (SNA)";
CM_ BO_ 649 "Left body controller message: logging10 hz; frame length observed on a vehicle bus";
CM_ SG_ 649 VCLEFT_logging10HzIndex "Left body controller: logging10 hz index";
CM_ SG_ 649 VCLEFT_hvacBlowerRs "Left body controller: hvac blower rs; raw 255 = signal not available (SNA)";
CM_ SG_ 649 VCLEFT_hvacBlowerIPhase0 "Left body controller: hvac blower i phase0; raw 127 = signal not available (SNA)";
CM_ SG_ 649 VCLEFT_hvacBlowerIPhase1 "Left body controller: hvac blower i phase1; raw 127 = signal not available (SNA)";
CM_ SG_ 649 VCLEFT_hvacBlowerIPhase2 "Left body controller: hvac blower i phase2; raw 127 = signal not available (SNA)";
CM_ SG_ 649 VCLEFT_hvacBlower_IO_CBC_HEAD "Left body controller: hvac blower IO CBC HEAD";
CM_ SG_ 649 VCLEFT_hvacBlower_IO_CBC_TAIL "Left body controller: hvac blower IO CBC TAIL";
CM_ SG_ 649 VCLEFT_hvacBlower_IO_CBC_TAIL_va "Left body controller: hvac blower IO CBC TAIL valid";
CM_ SG_ 649 VCLEFT_hvacBlower_IO_CBC_Status "Left body controller: hvac blower IO CBC status";
CM_ SG_ 649 VCLEFT_hvacBlower_IO_CBC_numUart "Left body controller: hvac blower IO CBC num uart err";
CM_ SG_ 649 VCLEFT_hvacBlowerCBCEstState "Left body controller: hvac blower CBC est state";
CM_ SG_ 649 VCLEFT_hvacBlowerCBCCtrlState "Left body controller: hvac blower CBC ctrl state";
CM_ SG_ 649 VCLEFT_hvacBlowerITerm "Left body controller: hvac blower i term; raw 127 = signal not available (SNA)";
CM_ SG_ 649 VCLEFT_hvacBlowerSpiError "Left body controller: hvac blower spi error";
CM_ SG_ 649 VCLEFT_hvacBlowerRsOnlineActive "Left body controller: hvac blower rs online active";
CM_ BO_ 936 "Left body controller message: logging1 hz; frame length observed on a vehicle bus";
CM_ SG_ 936 VCLEFT_logging1HzIndex "Left body controller: logging1 hz index";
CM_ SG_ 936 VCLEFT_tohcPCBATemperature "Left body controller: tohc PCBA temperature; raw 255 = signal not available (SNA)";
CM_ SG_ 936 VCLEFT_phoneChargingFL "Charging status of front left wireless phone charger (if installed)";
CM_ SG_ 936 VCLEFT_phoneChargingFR "Charging status of front right wireless phone charger (if installed)";
CM_ SG_ 936 VCLEFT_swcResistance "Left body controller: swc resistance; raw 127 = signal not available (SNA)";
CM_ SG_ 936 VCLEFT_frontSeatHeatCushionPwr "Left body controller: front seat heat cushion pwr";
CM_ SG_ 936 VCLEFT_frontSeatHeatBackrestPwr "Left body controller: front seat heat backrest pwr";
CM_ SG_ 936 VCLEFT_rgbLedIPFLCurrent "Current drawn by the IPFL RGB LED";
CM_ SG_ 936 VCLEFT_rgbLedIPFRCurrent "Current drawn by the IPFR RGB LED";
CM_ SG_ 936 VCLEFT_rgbLedIPFLOutput "The power state of the IPFL RGB LED";
CM_ SG_ 936 VCLEFT_rgbLedIPFROutput "The power state of the IPFR RGB LED";
CM_ SG_ 936 VCLEFT_rgbLedFrontCurrent "Current drawn by the front door RGB LED";
CM_ SG_ 936 VCLEFT_rgbLedRearCurrent "Current drawn by the rear door RGB LED";
CM_ SG_ 936 VCLEFT_rgbLedFrontOutput "The power state of the front door RGB LED";
CM_ SG_ 936 VCLEFT_rgbLedRearOutput "The power state of the rear door RGB LED";
CM_ SG_ 936 VCLEFT_seat2RControllerCurrent "Left body controller: seat2 r controller current";
CM_ BO_ 727 "Left body controller message: pitch estimation; frame length observed on a vehicle bus";
CM_ SG_ 727 VCLEFT_pitchEstimateFusionState "Left body controller: pitch estimate fusion state";
CM_ SG_ 727 VCLEFT_pitchEstimateStateTransit "Left body controller: pitch estimate state transition ID";
CM_ SG_ 727 VCLEFT_pitchEstimateArbitratedSt "Left body controller: pitch estimate arbitrated state";
CM_ SG_ 727 VCLEFT_pitchEstimateOKForAiming "Left body controller: pitch estimate OK for aiming";
CM_ SG_ 727 VCLEFT_pitchEstimateFusionRaw "Left body controller: pitch estimate fusion raw";
CM_ SG_ 727 VCLEFT_pitchEstimate "Left body controller: pitch estimate; raw 512 = signal not available (SNA)";
CM_ BO_ 1860 "Left body controller message: recall status; frame length observed on a vehicle bus";
CM_ SG_ 1860 VCLEFT_systemRecallStatus "Left body controller: system recall status; raw 0 = signal not available (SNA)";
CM_ SG_ 1860 VCLEFT_seatRecallStatus "Left body controller: seat recall status; raw 0 = signal not available (SNA)";
CM_ SG_ 1860 VCLEFT_columnRecallStatus "Left body controller: column recall status; raw 0 = signal not available (SNA)";
CM_ SG_ 1860 VCLEFT_mirrorRecallStatus "Recall status for the left side view mirror; raw 0 = signal not available (SNA)";
BA_DEF_ BO_ "GenMsgCycleTime" INT 0 3600000;
BA_DEF_ BO_ "GenMsgSendType" ENUM "Cyclic","NotUsed","NotUsed","NotUsed","NotUsed","NotUsed","NotUsed","IfActive","NoMsgSendType","NotUsed";
BA_DEF_ BO_ "VFrameFormat" ENUM "StandardCAN","ExtendedCAN","reserved","J1939PG","reserved","reserved","reserved","reserved","reserved","reserved","reserved","reserved","reserved","reserved","StandardCAN_FD","ExtendedCAN_FD";
BA_DEF_ BO_ "CANFD_BRS" ENUM "0","1";
BA_DEF_ SG_ "GenSigSNA" STRING;
BA_DEF_ SG_ "SystemSignalLongSymbol" STRING;
BA_DEF_ SG_ "Confidence" ENUM "validated","plausible","layout-only","contradicted";
BA_DEF_DEF_ "GenMsgCycleTime" 0;
BA_DEF_DEF_ "GenMsgSendType" "NoMsgSendType";
BA_DEF_DEF_ "VFrameFormat" "StandardCAN";
BA_DEF_DEF_ "CANFD_BRS" "1";
BA_DEF_DEF_ "GenSigSNA" "";
BA_DEF_DEF_ "SystemSignalLongSymbol" "";
BA_DEF_DEF_ "Confidence" "layout-only";
BA_ "GenMsgCycleTime" BO_ 864 100;
BA_ "GenMsgSendType" BO_ 864 0;
BA_ "GenMsgCycleTime" BO_ 258 100;
BA_ "GenMsgSendType" BO_ 258 0;
BA_ "GenMsgCycleTime" BO_ 290 100;
BA_ "GenMsgSendType" BO_ 290 0;
BA_ "GenMsgCycleTime" BO_ 626 100;
BA_ "GenMsgSendType" BO_ 626 0;
BA_ "GenMsgCycleTime" BO_ 1186 1000;
BA_ "GenMsgSendType" BO_ 1186 0;
BA_ "GenMsgCycleTime" BO_ 642 100;
BA_ "GenMsgSendType" BO_ 642 0;
BA_ "GenMsgCycleTime" BO_ 770 1000;
BA_ "GenMsgSendType" BO_ 770 0;
BA_ "GenMsgCycleTime" BO_ 292 500;
BA_ "GenMsgSendType" BO_ 292 0;
BA_ "GenMsgCycleTime" BO_ 322 50;
BA_ "GenMsgSendType" BO_ 322 0;
BA_ "GenMsgCycleTime" BO_ 994 200;
BA_ "GenMsgSendType" BO_ 994 0;
BA_ "GenMsgCycleTime" BO_ 1802 10000;
BA_ "GenMsgSendType" BO_ 1802 0;
BA_ "GenMsgCycleTime" BO_ 649 100;
BA_ "GenMsgSendType" BO_ 649 0;
BA_ "GenMsgCycleTime" BO_ 936 200;
BA_ "GenMsgSendType" BO_ 936 0;
BA_ "GenMsgCycleTime" BO_ 727 1000;
BA_ "GenMsgSendType" BO_ 727 0;
BA_ "GenMsgCycleTime" BO_ 1860 1000;
BA_ "GenMsgSendType" BO_ 1860 0;
BA_ "Confidence" SG_ 864 VCLEFT_matrixIndex 0;
BA_ "Confidence" SG_ 864 VCLEFT_a001_WatchdogReset 0;
BA_ "Confidence" SG_ 864 VCLEFT_a002_PowerLossReset 0;
BA_ "Confidence" SG_ 864 VCLEFT_a003_SWAssertion 0;
BA_ "Confidence" SG_ 864 VCLEFT_a005_CANTXError 0;
BA_ "Confidence" SG_ 864 VCLEFT_a006_CANTX_cyclicError 0;
BA_ "Confidence" SG_ 864 VCLEFT_a010_ExtSupplyVoltError 0;
BA_ "Confidence" SG_ 864 VCLEFT_a012_CPUReset 0;
BA_ "Confidence" SG_ 864 VCLEFT_a013_AlertManagerFault 0;
BA_ "Confidence" SG_ 864 VCLEFT_a015_NVMMError 0;
BA_ "Confidence" SG_ 864 VCLEFT_a016_NVMMRecordError 0;
BA_ "Confidence" SG_ 864 VCLEFT_a017_NVMMStatusDbg 0;
BA_ "Confidence" SG_ 864 VCLEFT_a021_TaskSchedulerError 0;
BA_ "Confidence" SG_ 864 VCLEFT_a022_TaskInitError 0;
BA_ "Confidence" SG_ 864 VCLEFT_a029_CoreDump 0;
BA_ "Confidence" SG_ 864 VCLEFT_a030_ECULogUploadRequest 0;
BA_ "Confidence" SG_ 864 VCLEFT_a031_UDSActive 0;
BA_ "Confidence" SG_ 864 VCLEFT_a041_HighCPULoad 0;
BA_ "Confidence" SG_ 864 VCLEFT_a042_HighStackUsage 0;
BA_ "Confidence" SG_ 864 VCLEFT_a043_Task1msError 0;
BA_ "Confidence" SG_ 864 VCLEFT_a044_Task10msError 0;
BA_ "Confidence" SG_ 864 VCLEFT_a045_Task100msError 0;
BA_ "Confidence" SG_ 864 VCLEFT_a046_Task1000msError 0;
BA_ "Confidence" SG_ 864 VCLEFT_a057_HVP_MIA 0;
BA_ "Confidence" SG_ 864 VCLEFT_a058_inputRHighSyncDebug 0;
BA_ "Confidence" SG_ 864 VCLEFT_a059_inputResistanceHigh 0;
BA_ "Confidence" SG_ 864 VCLEFT_a060_engineeringBuild 0;
BA_ "Confidence" SG_ 864 VCLEFT_a061_XCPConnected 1;
BA_ "Confidence" SG_ 864 VCLEFT_a062_XCPWasConnected 1;
BA_ "Confidence" SG_ 864 VCLEFT_a063_SwitchFault 1;
BA_ "Confidence" SG_ 864 VCLEFT_a064_busSleepReqTimeout 1;
BA_ "Confidence" SG_ 864 VCLEFT_a065_emiosIsrRateLimitedD 1;
BA_ "SystemSignalLongSymbol" SG_ 864 VCLEFT_a065_emiosIsrRateLimitedD "VCLEFT_a065_emiosIsrRateLimitedDbg";
BA_ "Confidence" SG_ 864 VCLEFT_a066_emiosIsrShortPeriodD 1;
BA_ "SystemSignalLongSymbol" SG_ 864 VCLEFT_a066_emiosIsrShortPeriodD "VCLEFT_a066_emiosIsrShortPeriodDetectedDbg";
BA_ "Confidence" SG_ 864 VCLEFT_a082_VCRIGHT_IPC_MIA 1;
BA_ "Confidence" SG_ 864 VCLEFT_a083_VCLEFT_IPC_MIA 1;
BA_ "Confidence" SG_ 864 VCLEFT_a084_TPMS_MIA 1;
BA_ "Confidence" SG_ 864 VCLEFT_a085_CCCM_MIA 1;
BA_ "Confidence" SG_ 864 VCLEFT_a086_VCBATT_MIA 1;
BA_ "Confidence" SG_ 864 VCLEFT_a087_DIREL_MIA 1;
BA_ "Confidence" SG_ 864 VCLEFT_a088_DIRER_MIA 1;
BA_ "Confidence" SG_ 864 VCLEFT_a089_IBST_MIA 1;
BA_ "Confidence" SG_ 864 VCLEFT_a090_APS_MIA 1;
BA_ "Confidence" SG_ 864 VCLEFT_a091_CMPD_MIA 1;
BA_ "Confidence" SG_ 864 VCLEFT_a092_VCSEATD_MIA 1;
BA_ "Confidence" SG_ 864 VCLEFT_a093_VCSEATP_MIA 1;
BA_ "Confidence" SG_ 864 VCLEFT_a094_EPAS3P_MIA 1;
BA_ "Confidence" SG_ 864 VCLEFT_a095_CHG_MIA 1;
BA_ "Confidence" SG_ 864 VCLEFT_a096_OCS1P_MIA 1;
BA_ "Confidence" SG_ 864 VCLEFT_a097_CMP_MIA 1;
BA_ "Confidence" SG_ 864 VCLEFT_a098_DIR_MIA 1;
BA_ "Confidence" SG_ 864 VCLEFT_a099_PARK_MIA 1;
BA_ "Confidence" SG_ 864 VCLEFT_a100_CANbus_MIA 1;
BA_ "Confidence" SG_ 864 VCLEFT_a101_PM_MIA 1;
BA_ "Confidence" SG_ 864 VCLEFT_a102_PTC_MIA 1;
BA_ "Confidence" SG_ 864 VCLEFT_a103_CP_MIA 1;
BA_ "Confidence" SG_ 864 VCLEFT_a104_DAS_MIA 1;
BA_ "Confidence" SG_ 864 VCLEFT_a105_TAS_MIA 1;
BA_ "Confidence" SG_ 864 VCLEFT_a106_PCS_MIA 1;
BA_ "Confidence" SG_ 864 VCLEFT_a107_BMS_MIA 1;
BA_ "Confidence" SG_ 864 VCLEFT_a108_DIF_MIA 1;
BA_ "Confidence" SG_ 864 VCLEFT_a109_RCM_MIA 1;
BA_ "Confidence" SG_ 864 VCLEFT_a110_GTW_MIA 1;
BA_ "Confidence" SG_ 864 VCLEFT_a111_EPBR_MIA 1;
BA_ "Confidence" SG_ 864 VCLEFT_a112_EPBL_MIA 1;
BA_ "Confidence" SG_ 864 VCLEFT_a113_UI_MIA 1;
BA_ "Confidence" SG_ 864 VCLEFT_a114_ESP_MIA 1;
BA_ "Confidence" SG_ 864 VCLEFT_a115_VCSEC_MIA 1;
BA_ "Confidence" SG_ 864 VCLEFT_a116_VCRIGHT_MIA 1;
BA_ "Confidence" SG_ 864 VCLEFT_a117_VCLEFT_MIA 1;
BA_ "Confidence" SG_ 864 VCLEFT_a118_VCFRONT_MIA 1;
BA_ "Confidence" SG_ 864 VCLEFT_a119_SCCM_MIA 1;
BA_ "Confidence" SG_ 864 VCLEFT_a120_DI_DRIVE_MIA 1;
BA_ "Confidence" SG_ 864 VCLEFT_a121_ETC_MIA 0;
BA_ "Confidence" SG_ 864 VCLEFT_a122_ICR_MIA 0;
BA_ "Confidence" SG_ 864 VCLEFT_a123_AID_MIA 0;
BA_ "Confidence" SG_ 864 VCLEFT_a124_BB_MIA 0;
BA_ "Confidence" SG_ 864 VCLEFT_a125_RCU_MIA 0;
BA_ "Confidence" SG_ 864 VCLEFT_a129_blowerICLatchFault 0;
BA_ "Confidence" SG_ 864 VCLEFT_a130_blowerICWarning 0;
BA_ "Confidence" SG_ 864 VCLEFT_a131_blowerICTransFault 0;
BA_ "Confidence" SG_ 864 VCLEFT_a132_blowerSoftStall 0;
BA_ "Confidence" SG_ 864 VCLEFT_a133_blowerLowRPMCBang 0;
BA_ "Confidence" SG_ 864 VCLEFT_a134_SteerColUpDownUnCal 0;
BA_ "Confidence" SG_ 864 VCLEFT_a135_SteerColInOutUnCal 0;
BA_ "Confidence" SG_ 864 VCLEFT_a136_brakeSwitchMismatch 0;
BA_ "Confidence" SG_ 864 VCLEFT_a137_VCSECPowerCycled 0;
BA_ "Confidence" SG_ 864 VCLEFT_a138_consoleDoorAssist 0;
BA_ "Confidence" SG_ 864 VCLEFT_a139_BLERearPowerCycled 0;
BA_ "Confidence" SG_ 864 VCLEFT_a140_BLELeftPowerCycled 0;
BA_ "Confidence" SG_ 864 VCLEFT_a141_12VAuxPowerTrip 0;
BA_ "Confidence" SG_ 864 VCLEFT_a143_mirrorManuallyFolded 0;
BA_ "Confidence" SG_ 864 VCLEFT_a145_brakeSwitchStuck 0;
BA_ "Confidence" SG_ 864 VCLEFT_a148_brakePressInputMisma 0;
BA_ "SystemSignalLongSymbol" SG_ 864 VCLEFT_a148_brakePressInputMisma "VCLEFT_a148_brakePressInputMismatch";
BA_ "Confidence" SG_ 864 VCLEFT_a150_windowPinchFront 0;
BA_ "Confidence" SG_ 864 VCLEFT_a151_windowPinchRear 0;
BA_ "Confidence" SG_ 864 VCLEFT_a152_windowUncalFront 0;
BA_ "Confidence" SG_ 864 VCLEFT_a153_windowUncalRear 0;
BA_ "Confidence" SG_ 864 VCLEFT_a154_windowThermalFront 0;
BA_ "Confidence" SG_ 864 VCLEFT_a155_windowThermalRear 0;
BA_ "Confidence" SG_ 864 VCLEFT_a156_windowNoInputFront 0;
BA_ "Confidence" SG_ 864 VCLEFT_a157_windowNoInputRear 0;
BA_ "Confidence" SG_ 864 VCLEFT_a158_windowPinchOverideF 0;
BA_ "Confidence" SG_ 864 VCLEFT_a159_windowPinchOverideR 0;
BA_ "Confidence" SG_ 864 VCLEFT_a160_windowUndercurrentF 0;
BA_ "Confidence" SG_ 864 VCLEFT_a161_windowUndercurrentR 0;
BA_ "Confidence" SG_ 864 VCLEFT_a162_windowEncoderStallF 0;
BA_ "Confidence" SG_ 864 VCLEFT_a163_windowEncoderStallR 0;
BA_ "Confidence" SG_ 864 VCLEFT_a164_windowFactoryTest 0;
BA_ "Confidence" SG_ 864 VCLEFT_a165_windowFactoryTest2 0;
BA_ "Confidence" SG_ 864 VCLEFT_a166_windowDebug 0;
BA_ "Confidence" SG_ 864 VCLEFT_a167_windowDebugPinchF 0;
BA_ "Confidence" SG_ 864 VCLEFT_a168_windowDebugPinchR 0;
BA_ "Confidence" SG_ 864 VCLEFT_a169_windowCurrentPeakF 0;
BA_ "Confidence" SG_ 864 VCLEFT_a170_windowCurrentPeakR 0;
BA_ "Confidence" SG_ 864 VCLEFT_a172_SPI_MIA 0;
BA_ "Confidence" SG_ 864 VCLEFT_a173_windowBtnDoorOpen 0;
BA_ "Confidence" SG_ 864 VCLEFT_a175_windowSealDefectFron 0;
BA_ "SystemSignalLongSymbol" SG_ 864 VCLEFT_a175_windowSealDefectFron "VCLEFT_a175_windowSealDefectFront";
BA_ "Confidence" SG_ 864 VCLEFT_a176_windowSealDefectRear 0;
BA_ "Confidence" SG_ 864 VCLEFT_a180_frontDoorLatchRehome 0;
BA_ "Confidence" SG_ 864 VCLEFT_a181_rearDoorLatchRehome 0;
BA_ "Confidence" SG_ 864 VCLEFT_a182_emergencyLatchRel 0;
BA_ "Confidence" SG_ 864 VCLEFT_a183_doorStateFactoryTest 0;
BA_ "Confidence" SG_ 864 VCLEFT_a185_summonAborted 0;
BA_ "Confidence" SG_ 864 VCLEFT_a186_latchReleaseFailedF 0;
BA_ "Confidence" SG_ 864 VCLEFT_a187_latchReleaseFailedR 0;
BA_ "Confidence" SG_ 864 VCLEFT_a188_latchUnableToRearmF 0;
BA_ "Confidence" SG_ 864 VCLEFT_a189_latchUnableToRearmR 0;
BA_ "Confidence" SG_ 864 VCLEFT_a190_eFuseMgmtVbatFused 0;
BA_ "Confidence" SG_ 864 VCLEFT_a191_TLCOvercurrent 0;
BA_ "Confidence" SG_ 864 VCLEFT_a192_blowerGeneralFault 0;
BA_ "Confidence" SG_ 864 VCLEFT_a193_blowerMIA 0;
BA_ "Confidence" SG_ 864 VCLEFT_a194_blowerUnidentified 0;
BA_ "Confidence" SG_ 864 VCLEFT_a195_blowerIdentification 0;
BA_ "SystemSignalLongSymbol" SG_ 864 VCLEFT_a195_blowerIdentification "VCLEFT_a195_blowerIdentificationFailed";
BA_ "Confidence" SG_ 864 VCLEFT_a196_VEHCANOverterminate 0;
BA_ "Confidence" SG_ 864 VCLEFT_a197_VEHCANUndertrminate 0;
BA_ "Confidence" SG_ 864 VCLEFT_a200_motorPhantomEncoder 0;
BA_ "Confidence" SG_ 864 VCLEFT_a201_motorDutyEncDisabl 0;
BA_ "Confidence" SG_ 864 VCLEFT_a202_epbmUnderIStatic 0;
BA_ "Confidence" SG_ 864 VCLEFT_a203_epbmOverIStatic 0;
BA_ "Confidence" SG_ 864 VCLEFT_a204_epbmUnderIDyn 0;
BA_ "Confidence" SG_ 864 VCLEFT_a205_epbmOverIDyn 0;
BA_ "Confidence" SG_ 864 VCLEFT_a206_epbWrongDirection 0;
BA_ "Confidence" SG_ 864 VCLEFT_a207_epbmEnableWrong 0;
BA_ "Confidence" SG_ 864 VCLEFT_a208_epbFaulted 0;
BA_ "Confidence" SG_ 864 VCLEFT_a209_epbStateMisTime 0;
BA_ "Confidence" SG_ 864 VCLEFT_a210_epbStateTime 0;
BA_ "Confidence" SG_ 864 VCLEFT_a211_epbmUnderIStaticNew 0;
BA_ "Confidence" SG_ 864 VCLEFT_a212_epbmOverIStaticNew 0;
BA_ "Confidence" SG_ 864 VCLEFT_a213_epbmUnderIDynNew 0;
BA_ "Confidence" SG_ 864 VCLEFT_a214_epbmOverIDynNew 0;
BA_ "Confidence" SG_ 864 VCLEFT_a215_currentDesyncWarning 0;
BA_ "Confidence" SG_ 864 VCLEFT_a216_SPI_MIA_debugData1 0;
BA_ "Confidence" SG_ 864 VCLEFT_a217_SPI_MIA_debugData2 0;
BA_ "Confidence" SG_ 864 VCLEFT_a218_motorDriverFault 0;
BA_ "Confidence" SG_ 864 VCLEFT_a219_motorCurrentDropout 0;
BA_ "Confidence" SG_ 864 VCLEFT_a220_reverseLightFaultUse 0;
BA_ "SystemSignalLongSymbol" SG_ 864 VCLEFT_a220_reverseLightFaultUse "VCLEFT_a220_reverseLightFaultUser";
BA_ "Confidence" SG_ 864 VCLEFT_a221_hardwareLoadshedTrig 0;
BA_ "SystemSignalLongSymbol" SG_ 864 VCLEFT_a221_hardwareLoadshedTrig "VCLEFT_a221_hardwareLoadshedTriggered";
BA_ "Confidence" SG_ 864 VCLEFT_a223_VCBATT1_MIA 0;
BA_ "Confidence" SG_ 864 VCLEFT_a224_seatEncStallTrack 0;
BA_ "Confidence" SG_ 864 VCLEFT_a225_seatEncStallBack 0;
BA_ "Confidence" SG_ 864 VCLEFT_a226_seatEncStallTilt 0;
BA_ "Confidence" SG_ 864 VCLEFT_a227_seatEncStallLift 0;
BA_ "Confidence" SG_ 864 VCLEFT_a228_seatEncOverTrack 0;
BA_ "Confidence" SG_ 864 VCLEFT_a229_seatEncOverBack 0;
BA_ "Confidence" SG_ 864 VCLEFT_a230_seatEncOverTilt 0;
BA_ "Confidence" SG_ 864 VCLEFT_a231_seatEncOverLift 0;
BA_ "Confidence" SG_ 864 VCLEFT_a232_seatCurrUnderTrack 0;
BA_ "Confidence" SG_ 864 VCLEFT_a233_seatCurrUnderBack 0;
BA_ "Confidence" SG_ 864 VCLEFT_a234_seatCurrUnderTilt 0;
BA_ "Confidence" SG_ 864 VCLEFT_a235_seatCurrUnderLift 0;
BA_ "Confidence" SG_ 864 VCLEFT_a236_lumbarOverPresA 0;
BA_ "Confidence" SG_ 864 VCLEFT_a237_lumbarOverPresB 0;
BA_ "Confidence" SG_ 864 VCLEFT_a238_lumbarValveMIA 0;
BA_ "Confidence" SG_ 864 VCLEFT_a239_seatHeatIFront 0;
BA_ "Confidence" SG_ 864 VCLEFT_a240_seatHeatShortFront 0;
BA_ "Confidence" SG_ 864 VCLEFT_a241_seatHeatMIAFront 1;
BA_ "Confidence" SG_ 864 VCLEFT_a242_seatHeatIRearL 1;
BA_ "Confidence" SG_ 864 VCLEFT_a243_seatHeatShortRearL 1;
BA_ "Confidence" SG_ 864 VCLEFT_a244_seatHeatMIARearL 1;
BA_ "Confidence" SG_ 864 VCLEFT_a245_seatHeatIRearC 1;
BA_ "Confidence" SG_ 864 VCLEFT_a246_seatHeatShortRearC 1;
BA_ "Confidence" SG_ 864 VCLEFT_a247_seatHeatMIARearC 1;
BA_ "Confidence" SG_ 864 VCLEFT_a248_seatHeatIRearR 1;
BA_ "Confidence" SG_ 864 VCLEFT_a249_seatHeatShortRearR 1;
BA_ "Confidence" SG_ 864 VCLEFT_a250_seatHeatMIARearR 1;
BA_ "Confidence" SG_ 864 VCLEFT_a251_seatUncalTrack 0;
BA_ "Confidence" SG_ 864 VCLEFT_a252_seatUncalBack 0;
BA_ "Confidence" SG_ 864 VCLEFT_a253_seatUncalTilt 0;
BA_ "Confidence" SG_ 864 VCLEFT_a254_seatUncalLift 0;
BA_ "Confidence" SG_ 864 VCLEFT_a256_nxppca9539Fault 1;
BA_ "Confidence" SG_ 864 VCLEFT_a257_USBMIA 1;
BA_ "Confidence" SG_ 864 VCLEFT_a259_latchDisarmDelayF 1;
BA_ "Confidence" SG_ 864 VCLEFT_a260_latchDisarmDelayR 1;
BA_ "Confidence" SG_ 864 VCLEFT_a261_emergencyLatchRelRea 1;
BA_ "SystemSignalLongSymbol" SG_ 864 VCLEFT_a261_emergencyLatchRelRea "VCLEFT_a261_emergencyLatchRelRear";
BA_ "Confidence" SG_ 864 VCLEFT_a263_seatTrackStallDebug 1;
BA_ "Confidence" SG_ 864 VCLEFT_a264_seatBackStallDebug 1;
BA_ "Confidence" SG_ 864 VCLEFT_a265_seatTiltStallDebug 1;
BA_ "Confidence" SG_ 864 VCLEFT_a266_seatLiftStallDebug 1;
BA_ "Confidence" SG_ 864 VCLEFT_a267_seatTrackHCEncStlDbg 1;
BA_ "Confidence" SG_ 864 VCLEFT_a268_seatBackHCEncStlDbg 1;
BA_ "Confidence" SG_ 864 VCLEFT_a269_seatTiltHCEncStlDbg 1;
BA_ "Confidence" SG_ 864 VCLEFT_a270_seatLiftHCEncStlDbg 1;
BA_ "Confidence" SG_ 864 VCLEFT_a272_vhclPwrStateMsmtch 1;
BA_ "Confidence" SG_ 864 VCLEFT_a273_handleStuckActiveF 1;
BA_ "Confidence" SG_ 864 VCLEFT_a274_handleStuckActiveR 1;
BA_ "Confidence" SG_ 864 VCLEFT_a275_leftTurnLightFault 1;
BA_ "Confidence" SG_ 864 VCLEFT_a276_mirrorDebug 1;
BA_ "Confidence" SG_ 864 VCLEFT_a277_BLELeftUnderVoltage 1;
BA_ "Confidence" SG_ 864 VCLEFT_a278_BLERearUnderVoltage 1;
BA_ "Confidence" SG_ 864 VCLEFT_a279_VCSECUnderVoltage 1;
BA_ "Confidence" SG_ 864 VCLEFT_a280_latchDidNotDisarmF 1;
BA_ "Confidence" SG_ 864 VCLEFT_a281_latchDidNotDisarmR 1;
BA_ "Confidence" SG_ 864 VCLEFT_a282_latchUnexpectedArmF 1;
BA_ "Confidence" SG_ 864 VCLEFT_a283_latchUnexpectedArmR 1;
BA_ "Confidence" SG_ 864 VCLEFT_a284_blowerFbkSanity 1;
BA_ "Confidence" SG_ 864 VCLEFT_a285_blowerChipComms 1;
BA_ "Confidence" SG_ 864 VCLEFT_a286_windowSpeedInvalidF 1;
BA_ "Confidence" SG_ 864 VCLEFT_a287_windowSpeedInvalidR 1;
BA_ "Confidence" SG_ 864 VCLEFT_a288_handlePWMPeriodF 1;
BA_ "Confidence" SG_ 864 VCLEFT_a289_handlePWMPeriodR 1;
BA_ "Confidence" SG_ 864 VCLEFT_a290_occupancyFaultedFron 1;
BA_ "SystemSignalLongSymbol" SG_ 864 VCLEFT_a290_occupancyFaultedFron "VCLEFT_a290_occupancyFaultedFront";
BA_ "Confidence" SG_ 864 VCLEFT_a291_buckleFaultedFront 1;
BA_ "Confidence" SG_ 864 VCLEFT_a292_occupancyFaultedRear 1;
BA_ "SystemSignalLongSymbol" SG_ 864 VCLEFT_a292_occupancyFaultedRear "VCLEFT_a292_occupancyFaultedRearL";
BA_ "Confidence" SG_ 864 VCLEFT_a293_occupancyFaultedRear 1;
BA_ "SystemSignalLongSymbol" SG_ 864 VCLEFT_a293_occupancyFaultedRear "VCLEFT_a293_occupancyFaultedRearC";
BA_ "Confidence" SG_ 864 VCLEFT_a294_occupancyFaultedRear 1;
BA_ "SystemSignalLongSymbol" SG_ 864 VCLEFT_a294_occupancyFaultedRear "VCLEFT_a294_occupancyFaultedRearR";
BA_ "Confidence" SG_ 864 VCLEFT_a295_buckleFaultedRearL 1;
BA_ "Confidence" SG_ 864 VCLEFT_a296_buckleFaultedRearC 1;
BA_ "Confidence" SG_ 864 VCLEFT_a297_seatBelowMinPumpTmp 1;
BA_ "Confidence" SG_ 864 VCLEFT_a299_swcMIA 1;
BA_ "Confidence" SG_ 864 VCLEFT_a300_swcUnderVoltage 1;
BA_ "Confidence" SG_ 864 VCLEFT_a301_swcOverVoltage 0;
BA_ "Confidence" SG_ 864 VCLEFT_a302_blowerGeneralFault 0;
BA_ "Confidence" SG_ 864 VCLEFT_a303_eFuseMgmtWindowLift 0;
BA_ "Confidence" SG_ 864 VCLEFT_a304_frontIntHandleUnexpe 0;
BA_ "SystemSignalLongSymbol" SG_ 864 VCLEFT_a304_frontIntHandleUnexpe "VCLEFT_a304_frontIntHandleUnexpectedVoltage";
BA_ "Confidence" SG_ 864 VCLEFT_a305_rearIntHandleUnexpec 0;
BA_ "SystemSignalLongSymbol" SG_ 864 VCLEFT_a305_rearIntHandleUnexpec "VCLEFT_a305_rearIntHandleUnexpectedVoltage";
BA_ "Confidence" SG_ 864 VCLEFT_a306_handleDisconnectedF 0;
BA_ "Confidence" SG_ 864 VCLEFT_a307_handleDisconnectedR 0;
BA_ "Confidence" SG_ 864 VCLEFT_a308_sirenMIA 0;
BA_ "Confidence" SG_ 864 VCLEFT_a309_brakeSwitchFaulted 0;
BA_ "Confidence" SG_ 864 VCLEFT_a310_mirrorFoldStall 0;
BA_ "Confidence" SG_ 864 VCLEFT_a311_leftBrakeLightFault 0;
BA_ "Confidence" SG_ 864 VCLEFT_a312_leftTailLightFault 0;
BA_ "Confidence" SG_ 864 VCLEFT_a313_leftFootwellLightFau 0;
BA_ "SystemSignalLongSymbol" SG_ 864 VCLEFT_a313_leftFootwellLightFau "VCLEFT_a313_leftFootwellLightFault";
BA_ "Confidence" SG_ 864 VCLEFT_a314_leftMapPocketLightFa 0;
BA_ "SystemSignalLongSymbol" SG_ 864 VCLEFT_a314_leftMapPocketLightFa "VCLEFT_a314_leftMapPocketLightFault";
BA_ "Confidence" SG_ 864 VCLEFT_a315_leftInteriorTrunkLig 0;
BA_ "SystemSignalLongSymbol" SG_ 864 VCLEFT_a315_leftInteriorTrunkLig "VCLEFT_a315_leftInteriorTrunkLightFault";
BA_ "Confidence" SG_ 864 VCLEFT_a316_mirrorPrematureFoldS 0;
BA_ "SystemSignalLongSymbol" SG_ 864 VCLEFT_a316_mirrorPrematureFoldS "VCLEFT_a316_mirrorPrematureFoldStall";
BA_ "Confidence" SG_ 864 VCLEFT_a317_epbmLimpModeEnabled 0;
BA_ "Confidence" SG_ 864 VCLEFT_a318_trailerIncorrectConf 0;
BA_ "SystemSignalLongSymbol" SG_ 864 VCLEFT_a318_trailerIncorrectConf "VCLEFT_a318_trailerIncorrectConfig";
BA_ "Confidence" SG_ 864 VCLEFT_a319_brakePressPrimaryInp 0;
BA_ "SystemSignalLongSymbol" SG_ 864 VCLEFT_a319_brakePressPrimaryInp "VCLEFT_a319_brakePressPrimaryInputFaulted";
BA_ "Confidence" SG_ 864 VCLEFT_a320_windowReportCrackedA 0;
BA_ "SystemSignalLongSymbol" SG_ 864 VCLEFT_a320_windowReportCrackedA "VCLEFT_a320_windowReportCrackedAtTrimClear";
BA_ "Confidence" SG_ 864 VCLEFT_a321_windowRezeroedDebugF 0;
BA_ "Confidence" SG_ 864 VCLEFT_a322_windowRezeroedDebugR 0;
BA_ "Confidence" SG_ 864 VCLEFT_a323_mirrorCalibrated 0;
BA_ "Confidence" SG_ 864 VCLEFT_a324_mirrorHeatFault 0;
BA_ "Confidence" SG_ 864 VCLEFT_a325_hghtSnsrUnplgdFL 0;
BA_ "Confidence" SG_ 864 VCLEFT_a326_hghtSnsrUnplgdRL 0;
BA_ "Confidence" SG_ 864 VCLEFT_a327_hghtSnsrFaultFL 0;
BA_ "Confidence" SG_ 864 VCLEFT_a328_hghtSnsrFaultRL 0;
BA_ "Confidence" SG_ 864 VCLEFT_a329_noRideHeightCalib 0;
BA_ "Confidence" SG_ 864 VCLEFT_a330_shortDropFailedF 0;
BA_ "Confidence" SG_ 864 VCLEFT_a331_shortDropFailedR 0;
BA_ "Confidence" SG_ 864 VCLEFT_a332_intrusionSensorMIA 0;
BA_ "Confidence" SG_ 864 VCLEFT_a333_overheadConsoleMIA 0;
BA_ "Confidence" SG_ 864 VCLEFT_a334_overheadConsoleInter 0;
BA_ "SystemSignalLongSymbol" SG_ 864 VCLEFT_a334_overheadConsoleInter "VCLEFT_a334_overheadConsoleInternalFault";
BA_ "Confidence" SG_ 864 VCLEFT_a335_intrusionSensorInter 0;
BA_ "SystemSignalLongSymbol" SG_ 864 VCLEFT_a335_intrusionSensorInter "VCLEFT_a335_intrusionSensorInternalFault";
BA_ "Confidence" SG_ 864 VCLEFT_a336_windowDropRevThermal 0;
BA_ "SystemSignalLongSymbol" SG_ 864 VCLEFT_a336_windowDropRevThermal "VCLEFT_a336_windowDropRevThermalF";
BA_ "Confidence" SG_ 864 VCLEFT_a337_windowDropRevThermal 0;
BA_ "SystemSignalLongSymbol" SG_ 864 VCLEFT_a337_windowDropRevThermal "VCLEFT_a337_windowDropRevThermalR";
BA_ "Confidence" SG_ 864 VCLEFT_a338_trailerLightControll 0;
BA_ "SystemSignalLongSymbol" SG_ 864 VCLEFT_a338_trailerLightControll "VCLEFT_a338_trailerLightControllerMIA";
BA_ "Confidence" SG_ 864 VCLEFT_a339_trailerLeftTurnLight 0;
BA_ "SystemSignalLongSymbol" SG_ 864 VCLEFT_a339_trailerLeftTurnLight "VCLEFT_a339_trailerLeftTurnLightNotDetected";
BA_ "Confidence" SG_ 864 VCLEFT_a340_trailerRightTurnLigh 0;
BA_ "SystemSignalLongSymbol" SG_ 864 VCLEFT_a340_trailerRightTurnLigh "VCLEFT_a340_trailerRightTurnLightNotDetected";
BA_ "Confidence" SG_ 864 VCLEFT_a341_trailerLightFault 0;
BA_ "Confidence" SG_ 864 VCLEFT_a342_trailerLightControll 0;
BA_ "SystemSignalLongSymbol" SG_ 864 VCLEFT_a342_trailerLightControll "VCLEFT_a342_trailerLightControllerFault";
BA_ "Confidence" SG_ 864 VCLEFT_a345_chargePortPowerCycli 0;
BA_ "SystemSignalLongSymbol" SG_ 864 VCLEFT_a345_chargePortPowerCycli "VCLEFT_a345_chargePortPowerCycling";
BA_ "Confidence" SG_ 864 VCLEFT_a346_eFuseMgmtVbatFused2 0;
BA_ "Confidence" SG_ 864 VCLEFT_a347_nonContMonitorCleare 0;
BA_ "SystemSignalLongSymbol" SG_ 864 VCLEFT_a347_nonContMonitorCleare "VCLEFT_a347_nonContMonitorClearedDBG";
BA_ "Confidence" SG_ 864 VCLEFT_a348_CPSleepOvercurrent 0;
BA_ "Confidence" SG_ 864 VCLEFT_a349_CPSleepUndervoltage 0;
BA_ "Confidence" SG_ 864 VCLEFT_a350_ensOutOfRange 0;
BA_ "Confidence" SG_ 864 VCLEFT_a351_debugLiftgateCurrent 0;
BA_ "SystemSignalLongSymbol" SG_ 864 VCLEFT_a351_debugLiftgateCurrent "VCLEFT_a351_debugLiftgateCurrentSpike";
BA_ "Confidence" SG_ 864 VCLEFT_a352_liftgateClosingLatch 0;
BA_ "SystemSignalLongSymbol" SG_ 864 VCLEFT_a352_liftgateClosingLatch "VCLEFT_a352_liftgateClosingLatchEntryFailed";
BA_ "Confidence" SG_ 864 VCLEFT_a353_eFuseMgmtSteeringCol 0;
BA_ "SystemSignalLongSymbol" SG_ 864 VCLEFT_a353_eFuseMgmtSteeringCol "VCLEFT_a353_eFuseMgmtSteeringColumn";
BA_ "Confidence" SG_ 864 VCLEFT_a354_eFuseMgmtLiftGate 0;
BA_ "Confidence" SG_ 864 VCLEFT_a355_liftgateUnexpectedSt 0;
BA_ "SystemSignalLongSymbol" SG_ 864 VCLEFT_a355_liftgateUnexpectedSt "VCLEFT_a355_liftgateUnexpectedStop";
BA_ "Confidence" SG_ 864 VCLEFT_a356_liftgateFactoryTest 0;
BA_ "Confidence" SG_ 864 VCLEFT_a357_liftgateUncalibrated 0;
BA_ "Confidence" SG_ 864 VCLEFT_a358_debugLiftgateCurrent 0;
BA_ "SystemSignalLongSymbol" SG_ 864 VCLEFT_a358_debugLiftgateCurrent "VCLEFT_a358_debugLiftgateCurrentDropout";
BA_ "Confidence" SG_ 864 VCLEFT_a359_liftgateLatchExitNoP 0;
BA_ "SystemSignalLongSymbol" SG_ 864 VCLEFT_a359_liftgateLatchExitNoP "VCLEFT_a359_liftgateLatchExitNoPositionChange";
BA_ "Confidence" SG_ 864 VCLEFT_a360_detectedStationaryWh 0;
BA_ "SystemSignalLongSymbol" SG_ 864 VCLEFT_a360_detectedStationaryWh "VCLEFT_a360_detectedStationaryWhileMoving";
BA_ "Confidence" SG_ 864 VCLEFT_a361_stationaryThresholds 0;
BA_ "SystemSignalLongSymbol" SG_ 864 VCLEFT_a361_stationaryThresholds "VCLEFT_a361_stationaryThresholdsIncorrect";
BA_ "Confidence" SG_ 864 VCLEFT_a362_movingThresholdsInco 0;
BA_ "SystemSignalLongSymbol" SG_ 864 VCLEFT_a362_movingThresholdsInco "VCLEFT_a362_movingThresholdsIncorrect";
BA_ "Confidence" SG_ 864 VCLEFT_a363_liftgateOpenAngleSet 0;
BA_ "SystemSignalLongSymbol" SG_ 864 VCLEFT_a363_liftgateOpenAngleSet "VCLEFT_a363_liftgateOpenAngleSetReq";
BA_ "Confidence" SG_ 864 VCLEFT_a365_pitchUnlatchDisabled 0;
BA_ "Confidence" SG_ 864 VCLEFT_a366_liftgateLatchEntryDB 0;
BA_ "SystemSignalLongSymbol" SG_ 864 VCLEFT_a366_liftgateLatchEntryDB "VCLEFT_a366_liftgateLatchEntryDBG";
BA_ "Confidence" SG_ 864 VCLEFT_a370_seat2RowPitchUnlatch 0;
BA_ "SystemSignalLongSymbol" SG_ 864 VCLEFT_a370_seat2RowPitchUnlatch "VCLEFT_a370_seat2RowPitchUnlatched";
BA_ "Confidence" SG_ 864 VCLEFT_a371_seat2RowTrackUnlatch 0;
BA_ "SystemSignalLongSymbol" SG_ 864 VCLEFT_a371_seat2RowTrackUnlatch "VCLEFT_a371_seat2RowTrackUnlatched";
BA_ "Confidence" SG_ 864 VCLEFT_a372_seat2RowBackrestUnla 0;
BA_ "SystemSignalLongSymbol" SG_ 864 VCLEFT_a372_seat2RowBackrestUnla "VCLEFT_a372_seat2RowBackrestUnlatched";
BA_ "Confidence" SG_ 864 VCLEFT_a373_windowSwOpenReqInDog 0;
BA_ "SystemSignalLongSymbol" SG_ 864 VCLEFT_a373_windowSwOpenReqInDog "VCLEFT_a373_windowSwOpenReqInDogMode";
BA_ "Confidence" SG_ 864 VCLEFT_a374_trailerLightFaultMod 0;
BA_ "SystemSignalLongSymbol" SG_ 864 VCLEFT_a374_trailerLightFaultMod "VCLEFT_a374_trailerLightFaultModelY";
BA_ "Confidence" SG_ 864 VCLEFT_a375_windowPinchOverrideN 0;
BA_ "SystemSignalLongSymbol" SG_ 864 VCLEFT_a375_windowPinchOverrideN "VCLEFT_a375_windowPinchOverrideNudge";
BA_ "Confidence" SG_ 864 VCLEFT_a376_seat2RowBridgeCurren 0;
BA_ "SystemSignalLongSymbol" SG_ 864 VCLEFT_a376_seat2RowBridgeCurren "VCLEFT_a376_seat2RowBridgeCurrentExceeded";
BA_ "Confidence" SG_ 864 VCLEFT_a380_steerColThermalLimit 0;
BA_ "SystemSignalLongSymbol" SG_ 864 VCLEFT_a380_steerColThermalLimit "VCLEFT_a380_steerColThermalLimited";
BA_ "Confidence" SG_ 864 VCLEFT_a381_pitchEstimation1 0;
BA_ "Confidence" SG_ 864 VCLEFT_a382_pitchEstimation2 0;
BA_ "Confidence" SG_ 864 VCLEFT_a383_steerColInOutMotorSt 0;
BA_ "SystemSignalLongSymbol" SG_ 864 VCLEFT_a383_steerColInOutMotorSt "VCLEFT_a383_steerColInOutMotorStallCurrent";
BA_ "Confidence" SG_ 864 VCLEFT_a384_steerColUpDownMotorS 0;
BA_ "SystemSignalLongSymbol" SG_ 864 VCLEFT_a384_steerColUpDownMotorS "VCLEFT_a384_steerColUpDownMotorStallCurrent";
BA_ "Confidence" SG_ 864 VCLEFT_a385_steerColInOutMotorUn 0;
BA_ "SystemSignalLongSymbol" SG_ 864 VCLEFT_a385_steerColInOutMotorUn "VCLEFT_a385_steerColInOutMotorUnderCurrent";
BA_ "Confidence" SG_ 864 VCLEFT_a386_steerColUpDownMotorU 0;
BA_ "SystemSignalLongSymbol" SG_ 864 VCLEFT_a386_steerColUpDownMotorU "VCLEFT_a386_steerColUpDownMotorUnderCurrent";
BA_ "Confidence" SG_ 864 VCLEFT_a387_steerColInOutMotorEn 0;
BA_ "SystemSignalLongSymbol" SG_ 864 VCLEFT_a387_steerColInOutMotorEn "VCLEFT_a387_steerColInOutMotorEncoderStalled";
BA_ "Confidence" SG_ 864 VCLEFT_a388_steerColUpDownMotorE 0;
BA_ "SystemSignalLongSymbol" SG_ 864 VCLEFT_a388_steerColUpDownMotorE "VCLEFT_a388_steerColUpDownMotorEncoderStalled";
BA_ "Confidence" SG_ 864 VCLEFT_a389_steerColInOutEncoder 0;
BA_ "SystemSignalLongSymbol" SG_ 864 VCLEFT_a389_steerColInOutEncoder "VCLEFT_a389_steerColInOutEncoderOutOfRange";
BA_ "Confidence" SG_ 864 VCLEFT_a390_steerColUpDownEncode 0;
BA_ "SystemSignalLongSymbol" SG_ 864 VCLEFT_a390_steerColUpDownEncode "VCLEFT_a390_steerColUpDownEncoderOutOfRange";
BA_ "Confidence" SG_ 864 VCLEFT_a391_pitchEstimationImpla 0;
BA_ "SystemSignalLongSymbol" SG_ 864 VCLEFT_a391_pitchEstimationImpla "VCLEFT_a391_pitchEstimationImplausible";
BA_ "Confidence" SG_ 864 VCLEFT_a392_pitchEstimationGPSIm 0;
BA_ "SystemSignalLongSymbol" SG_ 864 VCLEFT_a392_pitchEstimationGPSIm "VCLEFT_a392_pitchEstimationGPSImprovedReinit";
BA_ "Confidence" SG_ 864 VCLEFT_a393_pitchEstimationNoGPS 0;
BA_ "SystemSignalLongSymbol" SG_ 864 VCLEFT_a393_pitchEstimationNoGPS "VCLEFT_a393_pitchEstimationNoGPSFusion";
BA_ "Confidence" SG_ 864 VCLEFT_a394_swsTouchTooNegativeD 0;
BA_ "SystemSignalLongSymbol" SG_ 864 VCLEFT_a394_swsTouchTooNegativeD "VCLEFT_a394_swsTouchTooNegativeDelta";
BA_ "Confidence" SG_ 864 VCLEFT_a395_swsTouchAdcCheckFail 0;
BA_ "Confidence" SG_ 864 VCLEFT_a396_swsTouchStuckFault 0;
BA_ "Confidence" SG_ 864 VCLEFT_a397_swsTouchOutOfRangeFa 0;
BA_ "SystemSignalLongSymbol" SG_ 864 VCLEFT_a397_swsTouchOutOfRangeFa "VCLEFT_a397_swsTouchOutOfRangeFault";
BA_ "Confidence" SG_ 864 VCLEFT_a398_swsTouchNvmFault 0;
BA_ "Confidence" SG_ 864 VCLEFT_a399_swsTouchNoisyBaselin 0;
BA_ "SystemSignalLongSymbol" SG_ 864 VCLEFT_a399_swsTouchNoisyBaselin "VCLEFT_a399_swsTouchNoisyBaselineInitialization";
BA_ "Confidence" SG_ 864 VCLEFT_a400_swsTouchDebouncedPro 0;
BA_ "SystemSignalLongSymbol" SG_ 864 VCLEFT_a400_swsTouchDebouncedPro "VCLEFT_a400_swsTouchDebouncedProcessingError";
BA_ "Confidence" SG_ 864 VCLEFT_a401_swsForceTestPatternV 0;
BA_ "SystemSignalLongSymbol" SG_ 864 VCLEFT_a401_swsForceTestPatternV "VCLEFT_a401_swsForceTestPatternViolation";
BA_ "Confidence" SG_ 864 VCLEFT_a402_swsForceOutOfRange 0;
BA_ "Confidence" SG_ 864 VCLEFT_a403_swsForceAdcCheckFail 0;
BA_ "Confidence" SG_ 864 VCLEFT_a404_swsForceI2cError 0;
BA_ "Confidence" SG_ 864 VCLEFT_a405_swsForceCalibrationF 0;
BA_ "SystemSignalLongSymbol" SG_ 864 VCLEFT_a405_swsForceCalibrationF "VCLEFT_a405_swsForceCalibrationFault";
BA_ "Confidence" SG_ 864 VCLEFT_a406_swsForceParametersFa 0;
BA_ "SystemSignalLongSymbol" SG_ 864 VCLEFT_a406_swsForceParametersFa "VCLEFT_a406_swsForceParametersFault";
BA_ "Confidence" SG_ 864 VCLEFT_a407_swsForceNvmFault 0;
BA_ "Confidence" SG_ 864 VCLEFT_a408_swsForceTouchSensorF 0;
BA_ "SystemSignalLongSymbol" SG_ 864 VCLEFT_a408_swsForceTouchSensorF "VCLEFT_a408_swsForceTouchSensorFault";
BA_ "Confidence" SG_ 864 VCLEFT_a409_swsScrollWheelPushFa 0;
BA_ "SystemSignalLongSymbol" SG_ 864 VCLEFT_a409_swsScrollWheelPushFa "VCLEFT_a409_swsScrollWheelPushFault";
BA_ "Confidence" SG_ 864 VCLEFT_a410_swsScrollWheelTiltFa 0;
BA_ "SystemSignalLongSymbol" SG_ 864 VCLEFT_a410_swsScrollWheelTiltFa "VCLEFT_a410_swsScrollWheelTiltFault";
BA_ "Confidence" SG_ 864 VCLEFT_a411_swsScrollWheelScroll 0;
BA_ "SystemSignalLongSymbol" SG_ 864 VCLEFT_a411_swsScrollWheelScroll "VCLEFT_a411_swsScrollWheelScrollFault";
BA_ "Confidence" SG_ 864 VCLEFT_a412_leftBrakeTailLightFa 0;
BA_ "SystemSignalLongSymbol" SG_ 864 VCLEFT_a412_leftBrakeTailLightFa "VCLEFT_a412_leftBrakeTailLightFault";
BA_ "Confidence" SG_ 864 VCLEFT_a413_undervoltageSelfTest 0;
BA_ "SystemSignalLongSymbol" SG_ 864 VCLEFT_a413_undervoltageSelfTest "VCLEFT_a413_undervoltageSelfTestFailure";
BA_ "Confidence" SG_ 864 VCLEFT_a414_swsHapticMotorFault 0;
BA_ "Confidence" SG_ 864 VCLEFT_a415_swsMiscFault 0;
BA_ "Confidence" SG_ 864 VCLEFT_a416_fohmTouchAdcCheckFai 0;
BA_ "SystemSignalLongSymbol" SG_ 864 VCLEFT_a416_fohmTouchAdcCheckFai "VCLEFT_a416_fohmTouchAdcCheckFail";
BA_ "Confidence" SG_ 864 VCLEFT_a417_fohmTouchOutOfRangeF 0;
BA_ "SystemSignalLongSymbol" SG_ 864 VCLEFT_a417_fohmTouchOutOfRangeF "VCLEFT_a417_fohmTouchOutOfRangeFault";
BA_ "Confidence" SG_ 864 VCLEFT_a418_fohmTouchVarianceFai 0;
BA_ "SystemSignalLongSymbol" SG_ 864 VCLEFT_a418_fohmTouchVarianceFai "VCLEFT_a418_fohmTouchVarianceFail";
BA_ "Confidence" SG_ 864 VCLEFT_a419_fohmTouchStuck 0;
BA_ "Confidence" SG_ 864 VCLEFT_a420_fohmTouchSensorsImpl 0;
BA_ "SystemSignalLongSymbol" SG_ 864 VCLEFT_a420_fohmTouchSensorsImpl "VCLEFT_a420_fohmTouchSensorsImplausible";
BA_ "Confidence" SG_ 864 VCLEFT_a421_fohmForceOutOfRangeF 0;
BA_ "SystemSignalLongSymbol" SG_ 864 VCLEFT_a421_fohmForceOutOfRangeF "VCLEFT_a421_fohmForceOutOfRangeFault";
BA_ "Confidence" SG_ 864 VCLEFT_a422_undervoltageSelfTest 0;
BA_ "SystemSignalLongSymbol" SG_ 864 VCLEFT_a422_undervoltageSelfTest "VCLEFT_a422_undervoltageSelfTestStuckOff";
BA_ "Confidence" SG_ 864 VCLEFT_a423_fohmForceI2cError 0;
BA_ "Confidence" SG_ 864 VCLEFT_a424_fohmAmberLEDFault 0;
BA_ "Confidence" SG_ 864 VCLEFT_a425_fohmVanityPowerSuppl 0;
BA_ "SystemSignalLongSymbol" SG_ 864 VCLEFT_a425_fohmVanityPowerSuppl "VCLEFT_a425_fohmVanityPowerSupplyFault";
BA_ "Confidence" SG_ 864 VCLEFT_a426_seatAbuseMotorWarn 0;
BA_ "Confidence" SG_ 864 VCLEFT_a427_seatAbuseMotorStop 0;
BA_ "Confidence" SG_ 864 VCLEFT_a428_seatAbuseBufferWarn 0;
BA_ "Confidence" SG_ 864 VCLEFT_a429_seatAbuseBufferFull 0;
BA_ "Confidence" SG_ 864 VCLEFT_a430_fohmRearDomeLightPow 0;
BA_ "SystemSignalLongSymbol" SG_ 864 VCLEFT_a430_fohmRearDomeLightPow "VCLEFT_a430_fohmRearDomeLightPowerSupplyFault";
BA_ "Confidence" SG_ 864 VCLEFT_a431_fohmVbatFault 0;
BA_ "Confidence" SG_ 864 VCLEFT_a432_fohmMiscFault 0;
BA_ "Confidence" SG_ 864 VCLEFT_a433_fohmForceCalibration 0;
BA_ "SystemSignalLongSymbol" SG_ 864 VCLEFT_a433_fohmForceCalibration "VCLEFT_a433_fohmForceCalibrationInvalid";
BA_ "Confidence" SG_ 864 VCLEFT_a434_swsScrollWheelPushDa 0;
BA_ "SystemSignalLongSymbol" SG_ 864 VCLEFT_a434_swsScrollWheelPushDa "VCLEFT_a434_swsScrollWheelPushData";
BA_ "Confidence" SG_ 864 VCLEFT_a435_swsNoReasonTouchFaul 0;
BA_ "SystemSignalLongSymbol" SG_ 864 VCLEFT_a435_swsNoReasonTouchFaul "VCLEFT_a435_swsNoReasonTouchFault";
BA_ "Confidence" SG_ 864 VCLEFT_a436_swsNoReasonForceFaul 0;
BA_ "SystemSignalLongSymbol" SG_ 864 VCLEFT_a436_swsNoReasonForceFaul "VCLEFT_a436_swsNoReasonForceFault";
BA_ "Confidence" SG_ 864 VCLEFT_a437_hvacRearLeftVertical 0;
BA_ "SystemSignalLongSymbol" SG_ 864 VCLEFT_a437_hvacRearLeftVertical "VCLEFT_a437_hvacRearLeftVerticalDriverFaulted";
BA_ "Confidence" SG_ 864 VCLEFT_a438_hvacRearLeftLateralD 0;
BA_ "SystemSignalLongSymbol" SG_ 864 VCLEFT_a438_hvacRearLeftLateralD "VCLEFT_a438_hvacRearLeftLateralDriverFaulted";
BA_ "Confidence" SG_ 864 VCLEFT_a439_hvacRearRightVertica 0;
BA_ "SystemSignalLongSymbol" SG_ 864 VCLEFT_a439_hvacRearRightVertica "VCLEFT_a439_hvacRearRightVerticalDriverFaulted";
BA_ "Confidence" SG_ 864 VCLEFT_a440_hvacRearRightLateral 0;
BA_ "SystemSignalLongSymbol" SG_ 864 VCLEFT_a440_hvacRearRightLateral "VCLEFT_a440_hvacRearRightLateralDriverFaulted";
BA_ "Confidence" SG_ 864 VCLEFT_a441_prndMIA 0;
BA_ "Confidence" SG_ 864 VCLEFT_a442_swsLongTouchEvent 0;
BA_ "Confidence" SG_ 864 VCLEFT_a444_drv8703Fault 0;
BA_ "Confidence" SG_ 864 VCLEFT_a445_drv8703SpiFaultDBG 0;
BA_ "Confidence" SG_ 864 VCLEFT_a446_trailerAuxReversePow 0;
BA_ "SystemSignalLongSymbol" SG_ 864 VCLEFT_a446_trailerAuxReversePow "VCLEFT_a446_trailerAuxReversePower";
BA_ "Confidence" SG_ 864 VCLEFT_a447_steeringColInOutEnds 0;
BA_ "SystemSignalLongSymbol" SG_ 864 VCLEFT_a447_steeringColInOutEnds "VCLEFT_a447_steeringColInOutEndstopCal";
BA_ "Confidence" SG_ 864 VCLEFT_a448_steeringColUpDownEnd 0;
BA_ "SystemSignalLongSymbol" SG_ 864 VCLEFT_a448_steeringColUpDownEnd "VCLEFT_a448_steeringColUpDownEndstopCal";
BA_ "Confidence" SG_ 864 VCLEFT_a449_steerColInOutMotorSh 0;
BA_ "SystemSignalLongSymbol" SG_ 864 VCLEFT_a449_steerColInOutMotorSh "VCLEFT_a449_steerColInOutMotorShadowAlgoResetOffset";
BA_ "Confidence" SG_ 864 VCLEFT_a450_steerColUpDownMotorS 0;
BA_ "SystemSignalLongSymbol" SG_ 864 VCLEFT_a450_steerColUpDownMotorS "VCLEFT_a450_steerColUpDownMotorShadowAlgoResetOffset";
BA_ "Confidence" SG_ 864 VCLEFT_a451_wirelessChargerMIA 0;
BA_ "Confidence" SG_ 864 VCLEFT_a453_liftgatePinchDetecte 0;
BA_ "SystemSignalLongSymbol" SG_ 864 VCLEFT_a453_liftgatePinchDetecte "VCLEFT_a453_liftgatePinchDetected";
BA_ "Confidence" SG_ 864 VCLEFT_a454_wirelessChargerFault 0;
BA_ "Confidence" SG_ 864 VCLEFT_a455_liftgateUnexpectedSh 0;
BA_ "SystemSignalLongSymbol" SG_ 864 VCLEFT_a455_liftgateUnexpectedSh "VCLEFT_a455_liftgateUnexpectedShutfaceSwPressed";
BA_ "Confidence" SG_ 864 VCLEFT_a460_etcDebug 0;
BA_ "Confidence" SG_ 864 VCLEFT_a466_hvac2RLeftAirwaveVer 0;
BA_ "SystemSignalLongSymbol" SG_ 864 VCLEFT_a466_hvac2RLeftAirwaveVer "VCLEFT_a466_hvac2RLeftAirwaveVerticalFault";
BA_ "Confidence" SG_ 864 VCLEFT_a467_hvac2RLeftAirwaveVer 0;
BA_ "SystemSignalLongSymbol" SG_ 864 VCLEFT_a467_hvac2RLeftAirwaveVer "VCLEFT_a467_hvac2RLeftAirwaveVerticalWarning";
BA_ "Confidence" SG_ 864 VCLEFT_a468_hvac2RLeftAirwaveVer 0;
BA_ "SystemSignalLongSymbol" SG_ 864 VCLEFT_a468_hvac2RLeftAirwaveVer "VCLEFT_a468_hvac2RLeftAirwaveVerticalUncalib";
BA_ "Confidence" SG_ 864 VCLEFT_a469_hvac2RLeftAirwaveLat 0;
BA_ "SystemSignalLongSymbol" SG_ 864 VCLEFT_a469_hvac2RLeftAirwaveLat "VCLEFT_a469_hvac2RLeftAirwaveLateralFault";
BA_ "Confidence" SG_ 864 VCLEFT_a470_hvac2RLeftAirwaveLat 0;
BA_ "SystemSignalLongSymbol" SG_ 864 VCLEFT_a470_hvac2RLeftAirwaveLat "VCLEFT_a470_hvac2RLeftAirwaveLateralWarning";
BA_ "Confidence" SG_ 864 VCLEFT_a471_hvac2RLeftAirwaveLat 0;
BA_ "SystemSignalLongSymbol" SG_ 864 VCLEFT_a471_hvac2RLeftAirwaveLat "VCLEFT_a471_hvac2RLeftAirwaveLateralUncalib";
BA_ "Confidence" SG_ 864 VCLEFT_a472_hvac2RRightAirwaveVe 0;
BA_ "SystemSignalLongSymbol" SG_ 864 VCLEFT_a472_hvac2RRightAirwaveVe "VCLEFT_a472_hvac2RRightAirwaveVerticalFault";
BA_ "Confidence" SG_ 864 VCLEFT_a473_hvac2RRightAirwaveVe 0;
BA_ "SystemSignalLongSymbol" SG_ 864 VCLEFT_a473_hvac2RRightAirwaveVe "VCLEFT_a473_hvac2RRightAirwaveVerticalWarning";
BA_ "Confidence" SG_ 864 VCLEFT_a474_hvac2RRightAirwaveVe 0;
BA_ "SystemSignalLongSymbol" SG_ 864 VCLEFT_a474_hvac2RRightAirwaveVe "VCLEFT_a474_hvac2RRightAirwaveVerticalUncalib";
BA_ "Confidence" SG_ 864 VCLEFT_a475_hvac2RRightAirwaveLa 0;
BA_ "SystemSignalLongSymbol" SG_ 864 VCLEFT_a475_hvac2RRightAirwaveLa "VCLEFT_a475_hvac2RRightAirwaveLateralFault";
BA_ "Confidence" SG_ 864 VCLEFT_a476_hvac2RRightAirwaveLa 0;
BA_ "SystemSignalLongSymbol" SG_ 864 VCLEFT_a476_hvac2RRightAirwaveLa "VCLEFT_a476_hvac2RRightAirwaveLateralWarning";
BA_ "Confidence" SG_ 864 VCLEFT_a477_hvac2RRightAirwaveLa 0;
BA_ "SystemSignalLongSymbol" SG_ 864 VCLEFT_a477_hvac2RRightAirwaveLa "VCLEFT_a477_hvac2RRightAirwaveLateralUncalib";
BA_ "Confidence" SG_ 864 VCLEFT_a478_BPillarCameraHeaterF 0;
BA_ "SystemSignalLongSymbol" SG_ 864 VCLEFT_a478_BPillarCameraHeaterF "VCLEFT_a478_BPillarCameraHeaterFault";
BA_ "Confidence" SG_ 864 VCLEFT_a480_vnf1048Fault 0;
BA_ "Confidence" SG_ 864 VCLEFT_a481_vnf1048SelfTestFailu 0;
BA_ "SystemSignalLongSymbol" SG_ 864 VCLEFT_a481_vnf1048SelfTestFailu "VCLEFT_a481_vnf1048SelfTestFailure";
BA_ "Confidence" SG_ 864 VCLEFT_a482_NCV77XXFault 0;
BA_ "Confidence" SG_ 864 VCLEFT_a483_leftTurnLightFaultUs 0;
BA_ "SystemSignalLongSymbol" SG_ 864 VCLEFT_a483_leftTurnLightFaultUs "VCLEFT_a483_leftTurnLightFaultUser";
BA_ "Confidence" SG_ 864 VCLEFT_a484_leftBrakeLightFaultU 0;
BA_ "SystemSignalLongSymbol" SG_ 864 VCLEFT_a484_leftBrakeLightFaultU "VCLEFT_a484_leftBrakeLightFaultUser";
BA_ "Confidence" SG_ 864 VCLEFT_a485_uvSelfTestLoadUnatte 0;
BA_ "SystemSignalLongSymbol" SG_ 864 VCLEFT_a485_uvSelfTestLoadUnatte "VCLEFT_a485_uvSelfTestLoadUnattemptedOnDbg";
BA_ "Confidence" SG_ 864 VCLEFT_a488_undervoltageSelfTest 0;
BA_ "SystemSignalLongSymbol" SG_ 864 VCLEFT_a488_undervoltageSelfTest "VCLEFT_a488_undervoltageSelfTestStuckOnDebug";
BA_ "Confidence" SG_ 864 VCLEFT_a489_undervoltageSelfTest 0;
BA_ "SystemSignalLongSymbol" SG_ 864 VCLEFT_a489_undervoltageSelfTest "VCLEFT_a489_undervoltageSelfTestStuckOn";
BA_ "Confidence" SG_ 864 VCLEFT_a490_vehicleOccupiedOnOTA 0;
BA_ "SystemSignalLongSymbol" SG_ 864 VCLEFT_a490_vehicleOccupiedOnOTA "VCLEFT_a490_vehicleOccupiedOnOTAStart";
BA_ "Confidence" SG_ 864 VCLEFT_a493_12vSocketFrontEFuseT 0;
BA_ "SystemSignalLongSymbol" SG_ 864 VCLEFT_a493_12vSocketFrontEFuseT "VCLEFT_a493_12vSocketFrontEFuseTrip";
BA_ "Confidence" SG_ 864 VCLEFT_a494_12vSocketRearEFuseTr 0;
BA_ "SystemSignalLongSymbol" SG_ 864 VCLEFT_a494_12vSocketRearEFuseTr "VCLEFT_a494_12vSocketRearEFuseTrip";
BA_ "Confidence" SG_ 864 VCLEFT_a497_CANMsgMACVerificatio 0;
BA_ "SystemSignalLongSymbol" SG_ 864 VCLEFT_a497_CANMsgMACVerificatio "VCLEFT_a497_CANMsgMACVerificationKeyNotProvisioned";
BA_ "Confidence" SG_ 864 VCLEFT_a498_CANMsgMACVerificatio 0;
BA_ "SystemSignalLongSymbol" SG_ 864 VCLEFT_a498_CANMsgMACVerificatio "VCLEFT_a498_CANMsgMACVerificationFailure";
BA_ "Confidence" SG_ 864 VCLEFT_a499_epbmInvalidateCdp 0;
BA_ "Confidence" SG_ 864 VCLEFT_a500_eFuseASICStateMismat 0;
BA_ "SystemSignalLongSymbol" SG_ 864 VCLEFT_a500_eFuseASICStateMismat "VCLEFT_a500_eFuseASICStateMismatch";
BA_ "Confidence" SG_ 864 VCLEFT_a501_vnf1048Configuration 0;
BA_ "SystemSignalLongSymbol" SG_ 864 VCLEFT_a501_vnf1048Configuration "VCLEFT_a501_vnf1048ConfigurationMismatch";
BA_ "Confidence" SG_ 864 VCLEFT_a510_3RowSeatUncalibrated 0;
BA_ "Confidence" SG_ 864 VCLEFT_a511_3RowSeatPositionNons 0;
BA_ "SystemSignalLongSymbol" SG_ 864 VCLEFT_a511_3RowSeatPositionNons "VCLEFT_a511_3RowSeatPositionNonsensical";
BA_ "Confidence" SG_ 864 VCLEFT_a512_3RowSeatAbsPosOffset 0;
BA_ "SystemSignalLongSymbol" SG_ 864 VCLEFT_a512_3RowSeatAbsPosOffset "VCLEFT_a512_3RowSeatAbsPosOffsetApplied";
BA_ "Confidence" SG_ 864 VCLEFT_a513_3RowSeatObstacleDete 0;
BA_ "SystemSignalLongSymbol" SG_ 864 VCLEFT_a513_3RowSeatObstacleDete "VCLEFT_a513_3RowSeatObstacleDetected";
BA_ "Confidence" SG_ 864 VCLEFT_a514_3RowSeatTempHigh 0;
BA_ "Confidence" SG_ 864 VCLEFT_a515_3RowSeatAbsPosSensor 0;
BA_ "SystemSignalLongSymbol" SG_ 864 VCLEFT_a515_3RowSeatAbsPosSensor "VCLEFT_a515_3RowSeatAbsPosSensorTransitionDbg";
BA_ "Confidence" SG_ 864 VCLEFT_a516_3RowSeatStatsFromLas 0;
BA_ "SystemSignalLongSymbol" SG_ 864 VCLEFT_a516_3RowSeatStatsFromLas "VCLEFT_a516_3RowSeatStatsFromLastStateDbg";
BA_ "Confidence" SG_ 864 VCLEFT_a517_3RowSeatRequestWhile 0;
BA_ "SystemSignalLongSymbol" SG_ 864 VCLEFT_a517_3RowSeatRequestWhile "VCLEFT_a517_3RowSeatRequestWhileUncalibrated";
BA_ "Confidence" SG_ 864 VCLEFT_a518_3RowSeatClashAvoidan 0;
BA_ "SystemSignalLongSymbol" SG_ 864 VCLEFT_a518_3RowSeatClashAvoidan "VCLEFT_a518_3RowSeatClashAvoidanceBlocked";
BA_ "Confidence" SG_ 864 VCLEFT_a519_3RowSeatOverfolded 0;
BA_ "Confidence" SG_ 864 VCLEFT_a520_configMismatch 0;
BA_ "Confidence" SG_ 864 VCLEFT_a521_seatHeatPadUnexpecte 0;
BA_ "SystemSignalLongSymbol" SG_ 864 VCLEFT_a521_seatHeatPadUnexpecte "VCLEFT_a521_seatHeatPadUnexpectedVoltage";
BA_ "Confidence" SG_ 864 VCLEFT_a522_trailerLightUnexpect 0;
BA_ "SystemSignalLongSymbol" SG_ 864 VCLEFT_a522_trailerLightUnexpect "VCLEFT_a522_trailerLightUnexpectedVoltage";
BA_ "Confidence" SG_ 864 VCLEFT_a523_eFuseThresholdsIncor 0;
BA_ "SystemSignalLongSymbol" SG_ 864 VCLEFT_a523_eFuseThresholdsIncor "VCLEFT_a523_eFuseThresholdsIncorrect";
BA_ "Confidence" SG_ 864 VCLEFT_a525_LVBatterySWMisconfig 0;
BA_ "SystemSignalLongSymbol" SG_ 864 VCLEFT_a525_LVBatterySWMisconfig "VCLEFT_a525_LVBatterySWMisconfiguration";
BA_ "Confidence" SG_ 864 VCLEFT_a526_pcbaOverTemperature 0;
BA_ "Confidence" SG_ 864 VCLEFT_a527_continuousFeedUnexpe 0;
BA_ "SystemSignalLongSymbol" SG_ 864 VCLEFT_a527_continuousFeedUnexpe "VCLEFT_a527_continuousFeedUnexpectedVoltage";
BA_ "Confidence" SG_ 864 VCLEFT_a528_unableToRunStuckOnTe 0;
BA_ "SystemSignalLongSymbol" SG_ 864 VCLEFT_a528_unableToRunStuckOnTe "VCLEFT_a528_unableToRunStuckOnTest";
BA_ "Confidence" SG_ 864 VCLEFT_a536_trunkFoldFlatSwitchF 0;
BA_ "SystemSignalLongSymbol" SG_ 864 VCLEFT_a536_trunkFoldFlatSwitchF "VCLEFT_a536_trunkFoldFlatSwitchFault";
BA_ "Confidence" SG_ 864 VCLEFT_a545_LVBatteryTypeUnknown 1;
BA_ "Confidence" SG_ 864 VCLEFT_a546_mirrorFoldTypeChange 1;
BA_ "SystemSignalLongSymbol" SG_ 864 VCLEFT_a546_mirrorFoldTypeChange "VCLEFT_a546_mirrorFoldTypeChanged";
BA_ "Confidence" SG_ 864 VCLEFT_a550_ambientTempDelta 1;
BA_ "Confidence" SG_ 864 VCLEFT_a551_interiorDoorRequestI 1;
BA_ "SystemSignalLongSymbol" SG_ 864 VCLEFT_a551_interiorDoorRequestI "VCLEFT_a551_interiorDoorRequestInhibited";
BA_ "Confidence" SG_ 864 VCLEFT_a554_RCM2_MIA 1;
BA_ "Confidence" SG_ 864 VCLEFT_a555_steeringWheelHeaterC 1;
BA_ "SystemSignalLongSymbol" SG_ 864 VCLEFT_a555_steeringWheelHeaterC "VCLEFT_a555_steeringWheelHeaterCompromised";
BA_ "Confidence" SG_ 864 VCLEFT_a560_2RowSeatUncalibrated 1;
BA_ "Confidence" SG_ 864 VCLEFT_a561_2RowSeatPositionNons 1;
BA_ "SystemSignalLongSymbol" SG_ 864 VCLEFT_a561_2RowSeatPositionNons "VCLEFT_a561_2RowSeatPositionNonsensical";
BA_ "Confidence" SG_ 864 VCLEFT_a562_2RowSeatAbsPosOffset 1;
BA_ "SystemSignalLongSymbol" SG_ 864 VCLEFT_a562_2RowSeatAbsPosOffset "VCLEFT_a562_2RowSeatAbsPosOffsetApplied";
BA_ "Confidence" SG_ 864 VCLEFT_a563_2RowSeatObstacleDete 1;
BA_ "SystemSignalLongSymbol" SG_ 864 VCLEFT_a563_2RowSeatObstacleDete "VCLEFT_a563_2RowSeatObstacleDetected";
BA_ "Confidence" SG_ 864 VCLEFT_a564_2RowSeatTempHigh 1;
BA_ "Confidence" SG_ 864 VCLEFT_a565_2RowSeatAbsPosSensor 1;
BA_ "SystemSignalLongSymbol" SG_ 864 VCLEFT_a565_2RowSeatAbsPosSensor "VCLEFT_a565_2RowSeatAbsPosSensorTransitionDbg";
BA_ "Confidence" SG_ 864 VCLEFT_a566_2RowSeatStatsFromLas 1;
BA_ "SystemSignalLongSymbol" SG_ 864 VCLEFT_a566_2RowSeatStatsFromLas "VCLEFT_a566_2RowSeatStatsFromLastStateDbg";
BA_ "Confidence" SG_ 864 VCLEFT_a567_2RowSeatRequestWhile 1;
BA_ "SystemSignalLongSymbol" SG_ 864 VCLEFT_a567_2RowSeatRequestWhile "VCLEFT_a567_2RowSeatRequestWhileUncalibrated";
BA_ "Confidence" SG_ 864 VCLEFT_a568_2RowSeatClashAvoidan 1;
BA_ "SystemSignalLongSymbol" SG_ 864 VCLEFT_a568_2RowSeatClashAvoidan "VCLEFT_a568_2RowSeatClashAvoidanceBlocked";
BA_ "Confidence" SG_ 864 VCLEFT_a569_2RowSeatOverfolded 1;
BA_ "Confidence" SG_ 864 VCLEFT_a570_seatHeatDisabledF 1;
BA_ "Confidence" SG_ 864 VCLEFT_a571_seatHeatDisabledRear 1;
BA_ "SystemSignalLongSymbol" SG_ 864 VCLEFT_a571_seatHeatDisabledRear "VCLEFT_a571_seatHeatDisabledRearL";
BA_ "Confidence" SG_ 864 VCLEFT_a572_seatHeatDisabledRear 1;
BA_ "SystemSignalLongSymbol" SG_ 864 VCLEFT_a572_seatHeatDisabledRear "VCLEFT_a572_seatHeatDisabledRearC";
BA_ "Confidence" SG_ 864 VCLEFT_a573_seatHeatDisabledRear 1;
BA_ "SystemSignalLongSymbol" SG_ 864 VCLEFT_a573_seatHeatDisabledRear "VCLEFT_a573_seatHeatDisabledRearR";
BA_ "Confidence" SG_ 864 VCLEFT_a574_2RowSeatStatsFromLas 1;
BA_ "SystemSignalLongSymbol" SG_ 864 VCLEFT_a574_2RowSeatStatsFromLas "VCLEFT_a574_2RowSeatStatsFromLastStateDbg2";
BA_ "Confidence" SG_ 864 VCLEFT_a575_3RowSeatStatsFromLas 1;
BA_ "SystemSignalLongSymbol" SG_ 864 VCLEFT_a575_3RowSeatStatsFromLas "VCLEFT_a575_3RowSeatStatsFromLastStateDbg2";
BA_ "Confidence" SG_ 864 VCLEFT_a576_liftgateStrutPositio 1;
BA_ "SystemSignalLongSymbol" SG_ 864 VCLEFT_a576_liftgateStrutPositio "VCLEFT_a576_liftgateStrutPositionMismatch";
BA_ "Confidence" SG_ 864 VCLEFT_a577_bsiHardwareIssue 1;
BA_ "Confidence" SG_ 864 VCLEFT_a578_RGBLightFault 1;
BA_ "Confidence" SG_ 864 VCLEFT_a579_leftSteeringWheelCtr 1;
BA_ "SystemSignalLongSymbol" SG_ 864 VCLEFT_a579_leftSteeringWheelCtr "VCLEFT_a579_leftSteeringWheelCtrlTypeMismatch";
BA_ "Confidence" SG_ 864 VCLEFT_a580_rightSteeringWheelCt 1;
BA_ "SystemSignalLongSymbol" SG_ 864 VCLEFT_a580_rightSteeringWheelCt "VCLEFT_a580_rightSteeringWheelCtrlTypeMismatch";
BA_ "Confidence" SG_ 864 VCLEFT_a581_reverseLightFault 1;
BA_ "Confidence" SG_ 864 VCLEFT_a582_seat2RControllerTrip 1;
BA_ "Confidence" SG_ 864 VCLEFT_a583_doorRemoteUnlatchedF 1;
BA_ "SystemSignalLongSymbol" SG_ 864 VCLEFT_a583_doorRemoteUnlatchedF "VCLEFT_a583_doorRemoteUnlatchedFront";
BA_ "Confidence" SG_ 864 VCLEFT_a584_doorRemoteUnlatchedR 1;
BA_ "SystemSignalLongSymbol" SG_ 864 VCLEFT_a584_doorRemoteUnlatchedR "VCLEFT_a584_doorRemoteUnlatchedRear";
BA_ "Confidence" SG_ 864 VCLEFT_a585_doorRemoteUnlatchFai 1;
BA_ "SystemSignalLongSymbol" SG_ 864 VCLEFT_a585_doorRemoteUnlatchFai "VCLEFT_a585_doorRemoteUnlatchFailedFront";
BA_ "Confidence" SG_ 864 VCLEFT_a586_doorRemoteUnlatchFai 1;
BA_ "SystemSignalLongSymbol" SG_ 864 VCLEFT_a586_doorRemoteUnlatchFai "VCLEFT_a586_doorRemoteUnlatchFailedRear";
BA_ "Confidence" SG_ 864 VCLEFT_a587_VCSEAT2L_MIA 1;
BA_ "Confidence" SG_ 864 VCLEFT_a589_lipcCanFault 1;
BA_ "Confidence" SG_ 864 VCLEFT_a590_seatEncStallThighSup 1;
BA_ "SystemSignalLongSymbol" SG_ 864 VCLEFT_a590_seatEncStallThighSup "VCLEFT_a590_seatEncStallThighSupport";
BA_ "Confidence" SG_ 864 VCLEFT_a591_seatCurrUnderThighSu 1;
BA_ "SystemSignalLongSymbol" SG_ 864 VCLEFT_a591_seatCurrUnderThighSu "VCLEFT_a591_seatCurrUnderThighSupport";
BA_ "Confidence" SG_ 864 VCLEFT_a592_seatUncalThighSuppor 1;
BA_ "SystemSignalLongSymbol" SG_ 864 VCLEFT_a592_seatUncalThighSuppor "VCLEFT_a592_seatUncalThighSupport";
BA_ "Confidence" SG_ 864 VCLEFT_a593_seatEncOverThighSupp 1;
BA_ "SystemSignalLongSymbol" SG_ 864 VCLEFT_a593_seatEncOverThighSupp "VCLEFT_a593_seatEncOverThighSupport";
BA_ "Confidence" SG_ 864 VCLEFT_a594_seatThighSupportStal 1;
BA_ "SystemSignalLongSymbol" SG_ 864 VCLEFT_a594_seatThighSupportStal "VCLEFT_a594_seatThighSupportStallDebug";
BA_ "Confidence" SG_ 864 VCLEFT_a595_seatThighSupportHCEn 1;
BA_ "SystemSignalLongSymbol" SG_ 864 VCLEFT_a595_seatThighSupportHCEn "VCLEFT_a595_seatThighSupportHCEncStlDbg";
BA_ "Confidence" SG_ 864 VCLEFT_a596_frontDoorLatchUnexpe 1;
BA_ "SystemSignalLongSymbol" SG_ 864 VCLEFT_a596_frontDoorLatchUnexpe "VCLEFT_a596_frontDoorLatchUnexpectedVoltage";
BA_ "Confidence" SG_ 864 VCLEFT_a597_rearDoorLatchUnexpec 1;
BA_ "SystemSignalLongSymbol" SG_ 864 VCLEFT_a597_rearDoorLatchUnexpec "VCLEFT_a597_rearDoorLatchUnexpectedVoltage";
BA_ "Confidence" SG_ 864 VCLEFT_a599_LVBatteryTypeUnsuppo 1;
BA_ "SystemSignalLongSymbol" SG_ 864 VCLEFT_a599_LVBatteryTypeUnsuppo "VCLEFT_a599_LVBatteryTypeUnsupported";
BA_ "Confidence" SG_ 864 VCLEFT_a601_wakeToOpenDoorDbg 0;
BA_ "Confidence" SG_ 864 VCLEFT_a605_CANMsgMACVerificatio 0;
BA_ "SystemSignalLongSymbol" SG_ 864 VCLEFT_a605_CANMsgMACVerificatio "VCLEFT_a605_CANMsgMACVerificationKeyMismatch";
BA_ "Confidence" SG_ 864 VCLEFT_a617_APP_MIA 0;
BA_ "Confidence" SG_ 258 VCLEFT_doorClosureStatusFront 1;
BA_ "GenSigSNA" SG_ 258 VCLEFT_doorClosureStatusFront "0";
BA_ "Confidence" SG_ 258 VCLEFT_doorClosureStatusRear 1;
BA_ "GenSigSNA" SG_ 258 VCLEFT_doorClosureStatusRear "0";
BA_ "Confidence" SG_ 258 VCLEFT_frontLatchSwitch 1;
BA_ "Confidence" SG_ 258 VCLEFT_rearLatchSwitch 1;
BA_ "Confidence" SG_ 258 VCLEFT_frontRelActuatorSwitch 1;
BA_ "Confidence" SG_ 258 VCLEFT_rearRelActuatorSwitch 1;
BA_ "Confidence" SG_ 258 VCLEFT_frontLatchStatus 1;
BA_ "GenSigSNA" SG_ 258 VCLEFT_frontLatchStatus "0";
BA_ "Confidence" SG_ 258 VCLEFT_rearLatchStatus 1;
BA_ "GenSigSNA" SG_ 258 VCLEFT_rearLatchStatus "0";
BA_ "Confidence" SG_ 258 VCLEFT_lastDoorReqSourceFront 1;
BA_ "Confidence" SG_ 258 VCLEFT_lastDoorReqSourceRear 1;
BA_ "Confidence" SG_ 258 VCLEFT_frontIntSwitchFaulted 1;
BA_ "Confidence" SG_ 258 VCLEFT_rearIntSwitchFaulted 1;
BA_ "Confidence" SG_ 258 VCLEFT_mirrorTiltXPosition 1;
BA_ "Confidence" SG_ 258 VCLEFT_mirrorTiltYPosition 1;
BA_ "Confidence" SG_ 258 VCLEFT_mirrorState 1;
BA_ "Confidence" SG_ 258 VCLEFT_mirrorFoldState 1;
BA_ "Confidence" SG_ 258 VCLEFT_mirrorRecallState 1;
BA_ "Confidence" SG_ 258 VCLEFT_mirrorHeatState 1;
BA_ "GenSigSNA" SG_ 258 VCLEFT_mirrorHeatState "0";
BA_ "Confidence" SG_ 258 VCLEFT_mirrorDipped 1;
BA_ "Confidence" SG_ 290 VCLEFT_doorStatus2Index 0;
BA_ "Confidence" SG_ 290 VCLEFT_rearLatchRelDuty 1;
BA_ "Confidence" SG_ 290 VCLEFT_vehicleInMotion 1;
BA_ "Confidence" SG_ 290 VCLEFT_frontDoorState 1;
BA_ "Confidence" SG_ 290 VCLEFT_rearDoorState 1;
BA_ "Confidence" SG_ 290 VCLEFT_frontHandleRawStatus 1;
BA_ "Confidence" SG_ 290 VCLEFT_rearHandleRawStatus 1;
BA_ "Confidence" SG_ 290 VCLEFT_frontHandleDebounceStatus 1;
BA_ "Confidence" SG_ 290 VCLEFT_rearHandleDebounceStatus 1;
BA_ "Confidence" SG_ 290 VCLEFT_frontHandle5vEnable 1;
BA_ "Confidence" SG_ 290 VCLEFT_rearHandle5vEnable 1;
BA_ "Confidence" SG_ 290 VCLEFT_BPillarCameraHeaterCurren 0;
BA_ "GenSigSNA" SG_ 290 VCLEFT_BPillarCameraHeaterCurren "63";
BA_ "SystemSignalLongSymbol" SG_ 290 VCLEFT_BPillarCameraHeaterCurren "VCLEFT_BPillarCameraHeaterCurrent";
BA_ "Confidence" SG_ 290 VCLEFT_mirrorTiltXOffset 0;
BA_ "Confidence" SG_ 290 VCLEFT_mirrorTiltYOffset 0;
BA_ "Confidence" SG_ 626 VCLEFT_epbmDebugIndex 0;
BA_ "Confidence" SG_ 626 VCLEFT_epbmCaliperState 0;
BA_ "Confidence" SG_ 626 VCLEFT_epbmMotorEnabled 0;
BA_ "Confidence" SG_ 626 VCLEFT_epbMotorCurrent 0;
BA_ "Confidence" SG_ 626 VCLEFT_epbmApplyVoltage 0;
BA_ "Confidence" SG_ 626 VCLEFT_epbmReleaseVoltage 0;
BA_ "Confidence" SG_ 626 VCLEFT_summonFaultReason 0;
BA_ "Confidence" SG_ 626 VCLEFT_epbSummonState 0;
BA_ "Confidence" SG_ 626 VCLEFT_epbmSummonState 0;
BA_ "Confidence" SG_ 626 VCLEFT_epbUnitStatus 0;
BA_ "Confidence" SG_ 626 VCLEFT_epbmFaultStatus 0;
BA_ "Confidence" SG_ 626 VCLEFT_epbFaultStatus 0;
BA_ "Confidence" SG_ 626 VCLEFT_epbmSystemStatus 0;
BA_ "Confidence" SG_ 626 VCLEFT_epbmAutonomyBehavior 0;
BA_ "Confidence" SG_ 1186 VCLEFT_etcBluetoothStatus 0;
BA_ "Confidence" SG_ 642 VCLEFT_hvacBlowerFeedbackIndex 0;
BA_ "Confidence" SG_ 642 VCLEFT_hvacBlowerEnabled 0;
BA_ "Confidence" SG_ 642 VCLEFT_hvacBlowerOutputDuty 0;
BA_ "GenSigSNA" SG_ 642 VCLEFT_hvacBlowerOutputDuty "127";
BA_ "Confidence" SG_ 642 VCLEFT_hvacBlowerRPMTarget 0;
BA_ "GenSigSNA" SG_ 642 VCLEFT_hvacBlowerRPMTarget "1023";
BA_ "Confidence" SG_ 642 VCLEFT_hvacBlowerRPMActual 0;
BA_ "Confidence" SG_ 642 VCLEFT_hvacBlowerTorque 0;
BA_ "GenSigSNA" SG_ 642 VCLEFT_hvacBlowerTorque "1023";
BA_ "Confidence" SG_ 642 VCLEFT_hvacBlowerFETTemp 0;
BA_ "GenSigSNA" SG_ 642 VCLEFT_hvacBlowerFETTemp "127";
BA_ "Confidence" SG_ 642 VCLEFT_hvacBlowerIDc 0;
BA_ "GenSigSNA" SG_ 642 VCLEFT_hvacBlowerIDc "127";
BA_ "Confidence" SG_ 642 VCLEFT_hvacBlowerInitd 0;
BA_ "Confidence" SG_ 642 VCLEFT_hvacBlowerFault 0;
BA_ "Confidence" SG_ 642 VCLEFT_hvacBlowerLimitFETTemps 0;
BA_ "Confidence" SG_ 642 VCLEFT_hvacBlowerPowerOn 0;
BA_ "Confidence" SG_ 642 VCLEFT_hvacBlowerMotorID 0;
BA_ "Confidence" SG_ 770 VCLEFT_infoIndex 0;
BA_ "Confidence" SG_ 770 VCLEFT_infoBuildType 0;
BA_ "Confidence" SG_ 770 VCLEFT_infoBuildConfigId 0;
BA_ "Confidence" SG_ 770 VCLEFT_infoHardwareId 0;
BA_ "Confidence" SG_ 770 VCLEFT_infoComponentId 0;
BA_ "Confidence" SG_ 770 VCLEFT_infoPcbaId 0;
BA_ "Confidence" SG_ 770 VCLEFT_infoAssemblyId 0;
BA_ "GenSigSNA" SG_ 770 VCLEFT_infoAssemblyId "255";
BA_ "Confidence" SG_ 770 VCLEFT_infoUsageId 0;
BA_ "Confidence" SG_ 770 VCLEFT_infoSubUsageId 0;
BA_ "Confidence" SG_ 770 VCLEFT_infoAppCrc 0;
BA_ "Confidence" SG_ 770 VCLEFT_infoLUMBARLAppCRC 0;
BA_ "Confidence" SG_ 770 VCLEFT_infoAppGitHash 0;
BA_ "Confidence" SG_ 770 VCLEFT_infoBootGitHash 0;
BA_ "Confidence" SG_ 770 VCLEFT_infoPlatformType 0;
BA_ "Confidence" SG_ 770 VCLEFT_infoBootUdsProtoVersion 0;
BA_ "Confidence" SG_ 770 VCLEFT_infoBootCrc 0;
BA_ "Confidence" SG_ 292 VCLEFT_liftgateRequestAction 0;
BA_ "Confidence" SG_ 292 VCLEFT_liftgateRequestTargetDuty 0;
BA_ "Confidence" SG_ 292 VCLEFT_liftgateRequestTargetAngl 0;
BA_ "SystemSignalLongSymbol" SG_ 292 VCLEFT_liftgateRequestTargetAngl "VCLEFT_liftgateRequestTargetAngle";
BA_ "Confidence" SG_ 292 VCLEFT_liftgateRequestTargetPara 0;
BA_ "SystemSignalLongSymbol" SG_ 292 VCLEFT_liftgateRequestTargetPara "VCLEFT_liftgateRequestTargetParam";
BA_ "Confidence" SG_ 292 VCLEFT_adaptiveLiftgateControlMo 0;
BA_ "SystemSignalLongSymbol" SG_ 292 VCLEFT_adaptiveLiftgateControlMo "VCLEFT_adaptiveLiftgateControlModeActive";
BA_ "Confidence" SG_ 292 VCLEFT_liftgateReqObsDetMode 0;
BA_ "Confidence" SG_ 292 VCLEFT_liftgateReqResetStrutCoun 0;
BA_ "SystemSignalLongSymbol" SG_ 292 VCLEFT_liftgateReqResetStrutCoun "VCLEFT_liftgateReqResetStrutCount";
BA_ "Confidence" SG_ 292 VCLEFT_liftgateReqClearCal 0;
BA_ "Confidence" SG_ 292 VCLEFT_liftgateTargetTerminalSpe 0;
BA_ "SystemSignalLongSymbol" SG_ 292 VCLEFT_liftgateTargetTerminalSpe "VCLEFT_liftgateTargetTerminalSpeed";
BA_ "Confidence" SG_ 292 VCLEFT_liftgateReqCoastPercent 0;
BA_ "Confidence" SG_ 292 VCLEFT_liftgateReqDutyScale 0;
BA_ "Confidence" SG_ 322 VCLEFT_liftgateStatusIndex 0;
BA_ "Confidence" SG_ 322 VCLEFT_liftgateState 0;
BA_ "Confidence" SG_ 322 VCLEFT_liftgateStoppingCondition 0;
BA_ "Confidence" SG_ 322 VCLEFT_liftgateMvmntNotAllowedCo 0;
BA_ "SystemSignalLongSymbol" SG_ 322 VCLEFT_liftgateMvmntNotAllowedCo "VCLEFT_liftgateMvmntNotAllowedCondition";
BA_ "Confidence" SG_ 322 VCLEFT_liftgatePositionCalibrate 0;
BA_ "SystemSignalLongSymbol" SG_ 322 VCLEFT_liftgatePositionCalibrate "VCLEFT_liftgatePositionCalibrated";
BA_ "Confidence" SG_ 322 VCLEFT_liftgateUIChimeRequest 0;
BA_ "Confidence" SG_ 322 VCLEFT_liftgatePhysicalChimeRequ 0;
BA_ "SystemSignalLongSymbol" SG_ 322 VCLEFT_liftgatePhysicalChimeRequ "VCLEFT_liftgatePhysicalChimeRequest";
BA_ "Confidence" SG_ 322 VCLEFT_liftgateEstimatedStrutTem 0;
BA_ "SystemSignalLongSymbol" SG_ 322 VCLEFT_liftgateEstimatedStrutTem "VCLEFT_liftgateEstimatedStrutTemp";
BA_ "Confidence" SG_ 322 VCLEFT_liftgateStaticStrutMode 0;
BA_ "GenSigSNA" SG_ 322 VCLEFT_liftgateStaticStrutMode "0";
BA_ "Confidence" SG_ 322 VCLEFT_liftgateRequestSource 0;
BA_ "Confidence" SG_ 322 VCLEFT_liftgateNewHeightNudge 0;
BA_ "Confidence" SG_ 322 VCLEFT_liftgateNewSaveHeight 0;
BA_ "Confidence" SG_ 322 VCLEFT_liftgateGeofenceState 0;
BA_ "Confidence" SG_ 322 VCLEFT_liftgateCloseWarnChimeReq 0;
BA_ "SystemSignalLongSymbol" SG_ 322 VCLEFT_liftgateCloseWarnChimeReq "VCLEFT_liftgateCloseWarnChimeRequest";
BA_ "Confidence" SG_ 322 VCLEFT_liftgateAboveCrossoverAng 0;
BA_ "SystemSignalLongSymbol" SG_ 322 VCLEFT_liftgateAboveCrossoverAng "VCLEFT_liftgateAboveCrossoverAngle";
BA_ "Confidence" SG_ 322 VCLEFT_liftgateLatchRequest 0;
BA_ "Confidence" SG_ 322 VCLEFT_liftgateStrutDutyCycle 0;
BA_ "Confidence" SG_ 322 VCLEFT_liftgateStrutCurrent 0;
BA_ "Confidence" SG_ 322 VCLEFT_liftgatePosition 0;
BA_ "Confidence" SG_ 322 VCLEFT_liftgateSpeed 0;
BA_ "Confidence" SG_ 322 VCLEFT_liftgateHeight 0;
BA_ "Confidence" SG_ 322 VCLEFT_liftgatePositionDiff 0;
BA_ "Confidence" SG_ 994 VCLEFT_brakeLightStatus 0;
BA_ "GenSigSNA" SG_ 994 VCLEFT_brakeLightStatus "3";
BA_ "Confidence" SG_ 994 VCLEFT_tailLightStatus 0;
BA_ "GenSigSNA" SG_ 994 VCLEFT_tailLightStatus "3";
BA_ "Confidence" SG_ 994 VCLEFT_turnSignalStatus 0;
BA_ "GenSigSNA" SG_ 994 VCLEFT_turnSignalStatus "3";
BA_ "Confidence" SG_ 994 VCLEFT_FLMapLightStatus 0;
BA_ "GenSigSNA" SG_ 994 VCLEFT_FLMapLightStatus "3";
BA_ "Confidence" SG_ 994 VCLEFT_FRMapLightStatus 0;
BA_ "GenSigSNA" SG_ 994 VCLEFT_FRMapLightStatus "3";
BA_ "Confidence" SG_ 994 VCLEFT_RLMapLightStatus 0;
BA_ "GenSigSNA" SG_ 994 VCLEFT_RLMapLightStatus "3";
BA_ "Confidence" SG_ 994 VCLEFT_RRMapLightStatus 0;
BA_ "GenSigSNA" SG_ 994 VCLEFT_RRMapLightStatus "3";
BA_ "Confidence" SG_ 994 VCLEFT_FLMapLightSwitchPressed 0;
BA_ "Confidence" SG_ 994 VCLEFT_FRMapLightSwitchPressed 0;
BA_ "Confidence" SG_ 994 VCLEFT_RLMapLightSwitchPressed 0;
BA_ "Confidence" SG_ 994 VCLEFT_RRMapLightSwitchPressed 0;
BA_ "Confidence" SG_ 994 VCLEFT_leftTurnTrailerLightStatu 0;
BA_ "GenSigSNA" SG_ 994 VCLEFT_leftTurnTrailerLightStatu "3";
BA_ "SystemSignalLongSymbol" SG_ 994 VCLEFT_leftTurnTrailerLightStatu "VCLEFT_leftTurnTrailerLightStatus";
BA_ "Confidence" SG_ 994 VCLEFT_rightTrnTrailerLightStatu 0;
BA_ "GenSigSNA" SG_ 994 VCLEFT_rightTrnTrailerLightStatu "3";
BA_ "SystemSignalLongSymbol" SG_ 994 VCLEFT_rightTrnTrailerLightStatu "VCLEFT_rightTrnTrailerLightStatus";
BA_ "Confidence" SG_ 994 VCLEFT_brakeTrailerLightStatus 0;
BA_ "GenSigSNA" SG_ 994 VCLEFT_brakeTrailerLightStatus "3";
BA_ "Confidence" SG_ 994 VCLEFT_tailTrailerLightStatus 0;
BA_ "GenSigSNA" SG_ 994 VCLEFT_tailTrailerLightStatus "3";
BA_ "Confidence" SG_ 994 VCLEFT_fogTrailerLightStatus 0;
BA_ "GenSigSNA" SG_ 994 VCLEFT_fogTrailerLightStatus "3";
BA_ "Confidence" SG_ 994 VCLEFT_frontRideHeight 0;
BA_ "GenSigSNA" SG_ 994 VCLEFT_frontRideHeight "128";
BA_ "Confidence" SG_ 994 VCLEFT_rearRideHeight 0;
BA_ "GenSigSNA" SG_ 994 VCLEFT_rearRideHeight "128";
BA_ "Confidence" SG_ 994 VCLEFT_leftDashRGBPowerRequest 0;
BA_ "Confidence" SG_ 994 VCLEFT_rightDashRGBPowerRequest 0;
BA_ "Confidence" SG_ 994 VCLEFT_trailerDetected 0;
BA_ "GenSigSNA" SG_ 994 VCLEFT_trailerDetected "0";
BA_ "Confidence" SG_ 994 VCLEFT_rideHeightSensorFault 0;
BA_ "Confidence" SG_ 994 VCLEFT_reverseTrailerLightStatus 0;
BA_ "GenSigSNA" SG_ 994 VCLEFT_reverseTrailerLightStatus "3";
BA_ "Confidence" SG_ 994 VCLEFT_tailLightOutageStatus 0;
BA_ "Confidence" SG_ 994 VCLEFT_reverseLightStatus 0;
BA_ "GenSigSNA" SG_ 994 VCLEFT_reverseLightStatus "3";
BA_ "Confidence" SG_ 994 VCLEFT_thirdRowLeftMapLightSwitc 0;
BA_ "SystemSignalLongSymbol" SG_ 994 VCLEFT_thirdRowLeftMapLightSwitc "VCLEFT_thirdRowLeftMapLightSwitchPressed";
BA_ "Confidence" SG_ 994 VCLEFT_thirdRowRightMapLightSwit 0;
BA_ "SystemSignalLongSymbol" SG_ 994 VCLEFT_thirdRowRightMapLightSwit "VCLEFT_thirdRowRightMapLightSwitchPressed";
BA_ "Confidence" SG_ 1802 VCLEFT_logging0point1HzIndex 1;
BA_ "Confidence" SG_ 1802 VCLEFT_leftBrakeTailLightCurrent 0;
BA_ "GenSigSNA" SG_ 1802 VCLEFT_leftBrakeTailLightCurrent "511";
BA_ "Confidence" SG_ 1802 VCLEFT_leftBrakeTailLightCu_0001 0;
BA_ "GenSigSNA" SG_ 1802 VCLEFT_leftBrakeTailLightCu_0001 "0";
BA_ "SystemSignalLongSymbol" SG_ 1802 VCLEFT_leftBrakeTailLightCu_0001 "VCLEFT_leftBrakeTailLightCurrentSenseState";
BA_ "Confidence" SG_ 1802 VCLEFT_leftRearTurnLightCurrent 0;
BA_ "GenSigSNA" SG_ 1802 VCLEFT_leftRearTurnLightCurrent "511";
BA_ "Confidence" SG_ 1802 VCLEFT_leftRearTurnLightCurrentS 0;
BA_ "GenSigSNA" SG_ 1802 VCLEFT_leftRearTurnLightCurrentS "0";
BA_ "SystemSignalLongSymbol" SG_ 1802 VCLEFT_leftRearTurnLightCurrentS "VCLEFT_leftRearTurnLightCurrentSenseState";
BA_ "Confidence" SG_ 1802 VCLEFT_phoneTemperatureFL 0;
BA_ "GenSigSNA" SG_ 1802 VCLEFT_phoneTemperatureFL "128";
BA_ "Confidence" SG_ 649 VCLEFT_logging10HzIndex 1;
BA_ "Confidence" SG_ 649 VCLEFT_hvacBlowerRs 1;
BA_ "GenSigSNA" SG_ 649 VCLEFT_hvacBlowerRs "255";
BA_ "Confidence" SG_ 649 VCLEFT_hvacBlowerIPhase0 1;
BA_ "GenSigSNA" SG_ 649 VCLEFT_hvacBlowerIPhase0 "127";
BA_ "Confidence" SG_ 649 VCLEFT_hvacBlowerIPhase1 1;
BA_ "GenSigSNA" SG_ 649 VCLEFT_hvacBlowerIPhase1 "127";
BA_ "Confidence" SG_ 649 VCLEFT_hvacBlowerIPhase2 1;
BA_ "GenSigSNA" SG_ 649 VCLEFT_hvacBlowerIPhase2 "127";
BA_ "SystemSignalLongSymbol" SG_ 649 VCLEFT_hvacBlower_IO_CBC_TAIL_va "VCLEFT_hvacBlower_IO_CBC_TAIL_valid";
BA_ "Confidence" SG_ 649 VCLEFT_hvacBlower_IO_CBC_Status 1;
BA_ "SystemSignalLongSymbol" SG_ 649 VCLEFT_hvacBlower_IO_CBC_numUart "VCLEFT_hvacBlower_IO_CBC_numUartErr";
BA_ "Confidence" SG_ 649 VCLEFT_hvacBlowerCBCEstState 1;
BA_ "Confidence" SG_ 649 VCLEFT_hvacBlowerCBCCtrlState 1;
BA_ "Confidence" SG_ 649 VCLEFT_hvacBlowerITerm 1;
BA_ "GenSigSNA" SG_ 649 VCLEFT_hvacBlowerITerm "127";
BA_ "Confidence" SG_ 936 VCLEFT_logging1HzIndex 0;
BA_ "Confidence" SG_ 936 VCLEFT_tohcPCBATemperature 0;
BA_ "GenSigSNA" SG_ 936 VCLEFT_tohcPCBATemperature "255";
BA_ "Confidence" SG_ 936 VCLEFT_phoneChargingFL 0;
BA_ "Confidence" SG_ 936 VCLEFT_phoneChargingFR 0;
BA_ "Confidence" SG_ 936 VCLEFT_swcResistance 0;
BA_ "GenSigSNA" SG_ 936 VCLEFT_swcResistance "127";
BA_ "Confidence" SG_ 936 VCLEFT_frontSeatHeatCushionPwr 0;
BA_ "Confidence" SG_ 936 VCLEFT_frontSeatHeatBackrestPwr 0;
BA_ "Confidence" SG_ 936 VCLEFT_rgbLedIPFLCurrent 0;
BA_ "Confidence" SG_ 936 VCLEFT_rgbLedIPFRCurrent 0;
BA_ "Confidence" SG_ 936 VCLEFT_rgbLedIPFLOutput 0;
BA_ "Confidence" SG_ 936 VCLEFT_rgbLedIPFROutput 0;
BA_ "Confidence" SG_ 936 VCLEFT_rgbLedFrontCurrent 0;
BA_ "Confidence" SG_ 936 VCLEFT_rgbLedRearCurrent 0;
BA_ "Confidence" SG_ 936 VCLEFT_rgbLedFrontOutput 0;
BA_ "Confidence" SG_ 936 VCLEFT_rgbLedRearOutput 0;
BA_ "Confidence" SG_ 936 VCLEFT_seat2RControllerCurrent 0;
BA_ "Confidence" SG_ 727 VCLEFT_pitchEstimateFusionState 0;
BA_ "Confidence" SG_ 727 VCLEFT_pitchEstimateStateTransit 0;
BA_ "SystemSignalLongSymbol" SG_ 727 VCLEFT_pitchEstimateStateTransit "VCLEFT_pitchEstimateStateTransitionID";
BA_ "Confidence" SG_ 727 VCLEFT_pitchEstimateArbitratedSt 0;
BA_ "SystemSignalLongSymbol" SG_ 727 VCLEFT_pitchEstimateArbitratedSt "VCLEFT_pitchEstimateArbitratedState";
BA_ "Confidence" SG_ 727 VCLEFT_pitchEstimateOKForAiming 0;
BA_ "Confidence" SG_ 727 VCLEFT_pitchEstimateFusionRaw 0;
BA_ "Confidence" SG_ 727 VCLEFT_pitchEstimate 0;
BA_ "GenSigSNA" SG_ 727 VCLEFT_pitchEstimate "512";
BA_ "Confidence" SG_ 1860 VCLEFT_systemRecallStatus 0;
BA_ "GenSigSNA" SG_ 1860 VCLEFT_systemRecallStatus "0";
BA_ "Confidence" SG_ 1860 VCLEFT_seatRecallStatus 0;
BA_ "GenSigSNA" SG_ 1860 VCLEFT_seatRecallStatus "0";
BA_ "Confidence" SG_ 1860 VCLEFT_columnRecallStatus 0;
BA_ "GenSigSNA" SG_ 1860 VCLEFT_columnRecallStatus "0";
BA_ "Confidence" SG_ 1860 VCLEFT_mirrorRecallStatus 0;
BA_ "GenSigSNA" SG_ 1860 VCLEFT_mirrorRecallStatus "0";
VAL_ 864 VCLEFT_matrixIndex 10 "AlertMatrix10" 9 "AlertMatrix9" 8 "AlertMatrix8" 7 "AlertMatrix7" 6 "AlertMatrix6" 5 "AlertMatrix5" 4 "AlertMatrix4" 3 "AlertMatrix3" 2 "AlertMatrix2" 1 "AlertMatrix1" 0 "AlertMatrix0" ;
VAL_ 258 VCLEFT_doorClosureStatusFront 8 "CLOSURE_STATUS_FAULT" 2 "CLOSURE_STATUS_CLOSED" 1 "CLOSURE_STATUS_OPEN" 0 "CLOSURE_STATUS_SNA" ;
VAL_ 258 VCLEFT_doorClosureStatusRear 8 "CLOSURE_STATUS_FAULT" 2 "CLOSURE_STATUS_CLOSED" 1 "CLOSURE_STATUS_OPEN" 0 "CLOSURE_STATUS_SNA" ;
VAL_ 258 VCLEFT_frontLatchStatus 8 "LATCH_FAULT" 7 "LATCH_DEFAULT" 6 "LATCH_TIMEOUT" 5 "LATCH_AJAR" 4 "LATCH_OPENING" 3 "LATCH_CLOSING" 2 "LATCH_CLOSED" 1 "LATCH_OPENED" 0 "LATCH_SNA" ;
VAL_ 258 VCLEFT_rearLatchStatus 8 "LATCH_FAULT" 7 "LATCH_DEFAULT" 6 "LATCH_TIMEOUT" 5 "LATCH_AJAR" 4 "LATCH_OPENING" 3 "LATCH_CLOSING" 2 "LATCH_CLOSED" 1 "LATCH_OPENED" 0 "LATCH_SNA" ;
VAL_ 258 VCLEFT_lastDoorReqSourceFront 4 "DOOR_REQUEST_SOURCE_ECU" 3 "DOOR_REQUEST_SOURCE_VCSEC" 2 "DOOR_REQUEST_SOURCE_EXTERIOR_HANDLE" 1 "DOOR_REQUEST_SOURCE_INTERIOR_BUTTON" 0 "DOOR_REQUEST_SOURCE_UNKNOWN" ;
VAL_ 258 VCLEFT_lastDoorReqSourceRear 4 "DOOR_REQUEST_SOURCE_ECU" 3 "DOOR_REQUEST_SOURCE_VCSEC" 2 "DOOR_REQUEST_SOURCE_EXTERIOR_HANDLE" 1 "DOOR_REQUEST_SOURCE_INTERIOR_BUTTON" 0 "DOOR_REQUEST_SOURCE_UNKNOWN" ;
VAL_ 258 VCLEFT_mirrorState 5 "MIRROR_STATE_CALIBRATION" 4 "MIRROR_STATE_RECALL" 3 "MIRROR_STATE_FOLD_UNFOLD" 2 "MIRROR_STATE_TILT_Y" 1 "MIRROR_STATE_TILT_X" 0 "MIRROR_STATE_IDLE" ;
VAL_ 258 VCLEFT_mirrorFoldState 4 "MIRROR_FOLD_STATE_UNFOLDING" 3 "MIRROR_FOLD_STATE_FOLDING" 2 "MIRROR_FOLD_STATE_UNFOLDED" 1 "MIRROR_FOLD_STATE_FOLDED" 0 "MIRROR_FOLD_STATE_UNKNOWN" ;
VAL_ 258 VCLEFT_mirrorRecallState 5 "MIRROR_RECALL_STATE_RECALLING_STOPPED" 4 "MIRROR_RECALL_STATE_RECALLING_FAILED" 3 "MIRROR_RECALL_STATE_RECALLING_COMPLETE" 2 "MIRROR_RECALL_STATE_RECALLING_AXIS_2" 1 "MIRROR_RECALL_STATE_RECALLING_AXIS_1" 0 "MIRROR_RECALL_STATE_INIT" ;
VAL_ 258 VCLEFT_mirrorHeatState 4 "HEATER_STATE_FAULT" 3 "HEATER_STATE_OFF_UNAVAILABLE" 2 "HEATER_STATE_OFF" 1 "HEATER_STATE_ON" 0 "HEATER_STATE_SNA" ;
VAL_ 290 VCLEFT_doorStatus2Index 1 "MUX1" 0 "MUX0" ;
VAL_ 290 VCLEFT_frontDoorState 6 "DOOR_STATE_INIT" 5 "DOOR_STATE_AJAR" 4 "DOOR_STATE_OPEN" 3 "DOOR_STATE_RELEASING_LATCH" 2 "DOOR_STATE_WAIT_FOR_SHORT_DROP" 1 "DOOR_STATE_CLOSED" 0 "DOOR_STATE_UNKNOWN" ;
VAL_ 290 VCLEFT_rearDoorState 6 "DOOR_STATE_INIT" 5 "DOOR_STATE_AJAR" 4 "DOOR_STATE_OPEN" 3 "DOOR_STATE_RELEASING_LATCH" 2 "DOOR_STATE_WAIT_FOR_SHORT_DROP" 1 "DOOR_STATE_CLOSED" 0 "DOOR_STATE_UNKNOWN" ;
VAL_ 290 VCLEFT_frontHandleRawStatus 5 "EXTERIOR_HANDLE_STATUS_FAULT" 4 "EXTERIOR_HANDLE_STATUS_DISCONNECTED" 3 "EXTERIOR_HANDLE_STATUS_ACTIVE" 2 "EXTERIOR_HANDLE_STATUS_NOT_ACTIVE" 1 "EXTERIOR_HANDLE_STATUS_INDETERMINATE" 0 "EXTERIOR_HANDLE_STATUS_SNA" ;
VAL_ 290 VCLEFT_rearHandleRawStatus 5 "EXTERIOR_HANDLE_STATUS_FAULT" 4 "EXTERIOR_HANDLE_STATUS_DISCONNECTED" 3 "EXTERIOR_HANDLE_STATUS_ACTIVE" 2 "EXTERIOR_HANDLE_STATUS_NOT_ACTIVE" 1 "EXTERIOR_HANDLE_STATUS_INDETERMINATE" 0 "EXTERIOR_HANDLE_STATUS_SNA" ;
VAL_ 290 VCLEFT_frontHandleDebounceStatus 5 "EXTERIOR_HANDLE_STATUS_FAULT" 4 "EXTERIOR_HANDLE_STATUS_DISCONNECTED" 3 "EXTERIOR_HANDLE_STATUS_ACTIVE" 2 "EXTERIOR_HANDLE_STATUS_NOT_ACTIVE" 1 "EXTERIOR_HANDLE_STATUS_INDETERMINATE" 0 "EXTERIOR_HANDLE_STATUS_SNA" ;
VAL_ 290 VCLEFT_rearHandleDebounceStatus 5 "EXTERIOR_HANDLE_STATUS_FAULT" 4 "EXTERIOR_HANDLE_STATUS_DISCONNECTED" 3 "EXTERIOR_HANDLE_STATUS_ACTIVE" 2 "EXTERIOR_HANDLE_STATUS_NOT_ACTIVE" 1 "EXTERIOR_HANDLE_STATUS_INDETERMINATE" 0 "EXTERIOR_HANDLE_STATUS_SNA" ;
VAL_ 290 VCLEFT_BPillarCameraHeaterCurren 63 "SNA" ;
VAL_ 626 VCLEFT_epbmDebugIndex 1 "TRANSITIONS" 0 "STATES" ;
VAL_ 626 VCLEFT_epbmCaliperState 6 "EPB_SAVED_CALIPERSTATE_WINCHMODE" 5 "EPB_SAVED_CALIPERSTATE_SERVICE" 4 "EPB_SAVED_CALIPERSTATE_OPEN" 3 "EPB_SAVED_CALIPERSTATE_PARK" 2 "EPB_SAVED_CALIPERSTATE_REAPPLY" 1 "EPB_SAVED_CALIPERSTATE_UNKNOWN" 0 "EPB_SAVED_CALIPERSTATE_UNSAVED" ;
VAL_ 626 VCLEFT_summonFaultReason 30 "EPB_SUMMONFAULT_MONITOR_TYPE_UNKNOWN" 29 "EPB_SUMMONFAULT_AP_MONITOR" 28 "EPB_SUMMONFAULT_REMOTE_DID_NOT_START" 27 "EPB_SUMMONFAULT_INVALID_REMOTE_STATE" 26 "EPB_SUMMONFAULT_START_IN_UNAVAILABLE" 25 "EPB_SUMMONFAULT_REMOTE_UNIT_FAULTED" 24 "EPB_SUMMONFAULT_LOCAL_UNIT_FAULTED" 23 "EPB_SUMMONFAULT_REMOTE_SUMMON_FAULTED" 22 "EPB_SUMMONFAULT_EPBREMOTE_MIA" 21 "EPB_SUMMONFAULT_PASSIVE_REQUEST" 20 "EPB_SUMMONFAULT_DI_STATE_INVALID" 19 "EPB_SUMMONFAULT_EPB_FAULT" 18 "EPB_SUMMONFAULT_MISMATCH" 17 "EPB_SUMMONFAULT_OOC" 16 "EPB_SUMMONFAULT_PM_REQUEST" 15 "EPB_SUMMONFAULT_PM_MIA" 14 "EPB_SUMMONFAULT_PARK_MIA" 13 "EPB_SUMMONFAULT_EXTERNAL" 12 "EPB_SUMMONFAULT_SPEED" 11 "EPB_SUMMONFAULT_EPBM_REQUEST" 10 "EPB_SUMMONFAULT_EAC_NOT_ALLOWED" 9 "EPB_SUMMONFAULT_VEH_CAN_FAULT" 8 "EPB_SUMMONFAULT_ESP_FAULT" 7 "EPB_SUMMONFAULT_DAS_FAULT" 6 "EPB_SUMMONFAULT_DI_APC_FAULT" 5 "EPB_SUMMONFAULT_DI_FAULT" 4 "EPB_SUMMONFAULT_EPBM_MIA" 3 "EPB_SUMMONFAULT_ESP_MIA" 2 "EPB_SUMMONFAULT_DAS_MIA" 1 "EPB_SUMMONFAULT_DI_MIA" 0 "EPB_SUMMONFAULT_NONE" ;
VAL_ 626 VCLEFT_epbSummonState 6 "EPB_SUMMON_UNAVAILABLE" 5 "EPB_SUMMON_FAULT" 4 "EPB_SUMMON_COMPLETE" 3 "EPB_SUMMON_ACTIVE" 2 "EPB_SUMMON_ARMED" 1 "EPB_SUMMON_IDLE" 0 "EPB_SUMMON_INIT" ;
VAL_ 626 VCLEFT_epbmSummonState 6 "EPB_SUMMON_UNAVAILABLE" 5 "EPB_SUMMON_FAULT" 4 "EPB_SUMMON_COMPLETE" 3 "EPB_SUMMON_ACTIVE" 2 "EPB_SUMMON_ARMED" 1 "EPB_SUMMON_IDLE" 0 "EPB_SUMMON_INIT" ;
VAL_ 626 VCLEFT_epbUnitStatus 23 "EPB_STATUS_COUNT" 22 "EPB_STATUS_AUTONOMY_OPEN" 21 "EPB_STATUS_FREE_ROLL_MODE" 20 "EPB_STATUS_DYNAMIC_PARKING" 19 "EPB_STATUS_EXTERNAL_PARKING" 18 "EPB_STATUS_RELEASING_FOR_EXTERNAL_PARK" 17 "EPB_STATUS_EXTERNAL_DYNAMIC" 16 "EPB_STATUS_SUMMON_PARKING" 15 "EPB_STATUS_SUMMON_RELEASING" 14 "EPB_STATUS_SUMMON" 13 "EPB_STATUS_WINCHMODE_PENDING" 12 "EPB_STATUS_PARK_PENDING" 11 "EPB_STATUS_SERVICE_RELEASING" 10 "EPB_STATUS_RELEASING" 9 "EPB_STATUS_DYNAMIC_APPLYING" 8 "EPB_STATUS_PARKING" 7 "EPB_STATUS_WINCHMODE_RELEASING" 6 "EPB_STATUS_WINCHMODE" 5 "EPB_STATUS_SERVICE" 4 "EPB_STATUS_START" 3 "EPB_STATUS_PARK" 2 "EPB_STATUS_DYNAMIC" 1 "EPB_STATUS_OPEN" 0 "EPB_STATUS_UNKNOWN" ;
VAL_ 626 VCLEFT_epbmFaultStatus 3 "EPB_STATUS_FAULT_IDLE" 2 "EPB_STATUS_FAULT" 1 "EPB_STATUS_RETRY" 0 "EPB_STATUS_NOMINAL" ;
VAL_ 626 VCLEFT_epbFaultStatus 3 "EPB_STATUS_FAULT_IDLE" 2 "EPB_STATUS_FAULT" 1 "EPB_STATUS_RETRY" 0 "EPB_STATUS_NOMINAL" ;
VAL_ 626 VCLEFT_epbmSystemStatus 8 "EPB_VEHICLE_STATUS_MISMATCH" 7 "EPB_VEHICLE_STATUS_FAULT_SECURE" 6 "EPB_VEHICLE_STATUS_FAULT" 5 "EPB_VEHICLE_STATUS_RELEASING" 4 "EPB_VEHICLE_STATUS_PARKING" 3 "EPB_VEHICLE_STATUS_DYNAMIC" 2 "EPB_VEHICLE_STATUS_PARKED" 1 "EPB_VEHICLE_STATUS_RELEASED" 0 "EPB_VEHICLE_STATUS_UNKNOWN" ;
VAL_ 626 VCLEFT_epbmAutonomyBehavior 2 "DRIVERLESS_NO_TAKEOVER" 1 "DRIVERLESS_TAKEOVER" 0 "DRIVER" ;
VAL_ 1186 VCLEFT_etcBluetoothStatus 3 "ETC_BLUETOOTH_STATE_RESERVED" 2 "ETC_BLUETOOTH_STATE_ON" 1 "ETC_BLUETOOTH_STATE_OFF" 0 "ETC_BLUETOOTH_STATE_INACTIVE" ;
VAL_ 642 VCLEFT_hvacBlowerFeedbackIndex 1 "END" 0 "HVAC_FEEDBACK_SIGNALS" ;
VAL_ 642 VCLEFT_hvacBlowerOutputDuty 127 "SNA" ;
VAL_ 642 VCLEFT_hvacBlowerRPMTarget 1023 "SNA" ;
VAL_ 642 VCLEFT_hvacBlowerTorque 1023 "SNA" ;
VAL_ 642 VCLEFT_hvacBlowerFETTemp 127 "SNA" ;
VAL_ 642 VCLEFT_hvacBlowerIDc 127 "SNA" ;
VAL_ 642 VCLEFT_hvacBlowerMotorID 2 "VC_MOTOR_ID_BOSCH" 1 "VC_MOTOR_ID_DELTA" 0 "VC_MOTOR_ID_UNKNOWN" ;
VAL_ 770 VCLEFT_infoIndex 255 "END" 41 "SUBCOMPONENT14" 40 "SUBCOMPONENT13" 39 "SUBCOMPONENT12" 38 "SUBCOMPONENT11" 37 "SUBCOMPONENT10" 36 "SUBCOMPONENT9" 35 "SUBCOMPONENT8" 34 "SUBCOMPONENT7" 33 "SUBCOMPONENT6" 32 "SUBCOMPONENT5" 31 "SUBCOMPONENT4" 24 "SUBCOMPONENT3" 23 "SUBCOMPONENT2" 20 "UDS_PROTOCOL_BOOTCRC" 19 "VERSION_DEPRECATED" 18 "BOOTLOADER_GITHASH" 17 "APP_GITHASH" 16 "SUBCOMPONENT1" 15 "BOOTLOADER_CRC" 14 "BOOTLOADER_SVN" 13 "APP_CRC" 11 "PCBAID_ASSYID_USAGEID" 10 "BUILD_HWID_COMPONENTID" 9 "DEPRECATED_9" 8 "DEPRECATED_8" 7 "DEPRECATED_7" 6 "DEPRECATED_6" 5 "DEPRECATED_5" 4 "DEPRECATED_4" 3 "DEPRECATED_3" 2 "DEPRECATED_2" 1 "DEPRECATED_1" 0 "DEPRECATED_0" ;
VAL_ 770 VCLEFT_infoBuildType 4 "INFO_MFG_BUILD" 3 "INFO_TRACEABLE_CI_BUILD" 2 "INFO_LOCAL_BUILD" 1 "INFO_PLATFORM_BUILD" 0 "INFO_UNKNOWN_BUILD" ;
VAL_ 770 VCLEFT_infoAssemblyId 255 "ASSEMBLY_SNA" 1 "ASSEMBLY1" ;
VAL_ 292 VCLEFT_liftgateRequestAction 18 "LIFTGATE_POSITION_ACTION_COUNT" 17 "LIFTGATE_POSITION_ACTION_FIXED_DUTY_LATCH_CURRENT_SCALED" 16 "LIFTGATE_POSITION_ACTION_FIXED_DUTY_LATCH_CURRENT" 15 "LIFTGATE_POSITION_ACTION_OPENING_BACKOFF" 14 "LIFTGATE_POSITION_ACTION_UPDATE_PARAM_CLOSING_SPEED" 13 "LIFTGATE_POSITION_ACTION_FACTORY_CLOSE" 12 "LIFTGATE_POSITION_ACTION_UNCAL_CLOSE" 11 "LIFTGATE_POSITION_ACTION_CLOSING_WHOOSH" 10 "LIFTGATE_POSITION_ACTION_CLOSING" 9 "LIFTGATE_POSITION_ACTION_PARTY_OPENING" 8 "LIFTGATE_POSITION_ACTION_OPENING_WHOOSH" 7 "LIFTGATE_POSITION_ACTION_OPENING_INIT_VEL" 6 "LIFTGATE_POSITION_ACTION_OPENING" 5 "LIFTGATE_POSITION_ACTION_RAMPED_DUTY_OFF" 4 "LIFTGATE_POSITION_ACTION_RAMPED_DUTY_LATCH_EXIT" 3 "LIFTGATE_POSITION_ACTION_RAMPED_DUTY_EOT" 2 "LIFTGATE_POSITION_ACTION_FIXED_DUTY_CLOSE" 1 "LIFTGATE_POSITION_ACTION_FIXED_DUTY_OPEN" 0 "LIFTGATE_POSITION_ACTION_IDLE" ;
VAL_ 292 VCLEFT_liftgateReqObsDetMode 5 "PLG_OBSTACLE_DETECT_MODE_PARTY_CLOSE" 4 "PLG_OBSTACLE_DETECT_MODE_LATCH_EXIT" 3 "PLG_OBSTACLE_DETECT_MODE_LATCH_ENTRY" 2 "PLG_OBSTACLE_DETECT_MODE_CLOSING" 1 "PLG_OBSTACLE_DETECT_MODE_OPENING" 0 "PLG_OBSTACLE_DETECT_MODE_INACTIVE" ;
VAL_ 322 VCLEFT_liftgateStatusIndex 2 "INVALID" 1 "1" 0 "0" ;
VAL_ 322 VCLEFT_liftgateState 13 "PLG_STATE_PARTY_DANCE" 12 "PLG_STATE_LATCH_ENTRY" 11 "PLG_STATE_END_OF_TRAVEL" 10 "PLG_STATE_LATCH_EXIT" 9 "PLG_STATE_UNKNOWN" 8 "PLG_STATE_NOT_INSTALLED" 7 "PLG_STATE_LATCH_CLOSING" 6 "PLG_STATE_LATCH_OPENING" 5 "PLG_STATE_CLOSED" 4 "PLG_STATE_CLOSING" 3 "PLG_STATE_OPENING" 2 "PLG_STATE_BACKOFF" 1 "PLG_STATE_OFF" 0 "PLG_STATE_INIT" ;
VAL_ 322 VCLEFT_liftgateStoppingCondition 13 "PLG_STOPPING_CONDITION_COUNT" 12 "PLG_STOPPING_CONDITION_FOLLOWER_REQUEST" 11 "PLG_STOPPING_CONDITION_OBSTACLE_CURRENT_SPIKE" 10 "PLG_STOPPING_CONDITION_LATCH_FAULT" 9 "PLG_STOPPING_CONDITION_UNCALIBRATED" 8 "PLG_STOPPING_CONDITION_OBSTACLE_TRAJ_VEL" 7 "PLG_STOPPING_CONDITION_OBSTACLE_TRAJ_POS" 6 "PLG_STOPPING_CONDITION_OBSTACLE_CURRENT" 5 "PLG_STOPPING_CONDITION_VEHICLE_AT_SPEED" 4 "PLG_STOPPING_CONDITION_STATE_TIMEOUT" 3 "PLG_STOPPING_CONDITION_LOW_12V" 2 "PLG_STOPPING_CONDITION_OBSTACLE_STALL" 1 "PLG_STOPPING_CONDITION_PINCH" 0 "PLG_STOPPING_CONDITION_NONE" ;
VAL_ 322 VCLEFT_liftgateMvmntNotAllowedCo 6 "PLG_MVMT_NOT_ALLOWED_STRUT_POSITION_MISMATCH" 5 "PLG_MVMT_NOT_ALLOWED_LOCKED" 4 "PLG_MVMT_NOT_ALLOWED_EXTERIOR_PRESS_AT_MAX_OPEN" 3 "PLG_MVMT_NOT_ALLOWED_UNCALIBRATED" 2 "PLG_MVMT_NOT_ALLOWED_VEHICLE_AT_SPEED" 1 "PLG_MVMT_NOT_ALLOWED_LOW_12V" 0 "PLG_MVMT_NOT_ALLOWED_NONE" ;
VAL_ 322 VCLEFT_liftgateUIChimeRequest 4 "REMOTE_CHIME_REQUEST_ONE_LONG" 3 "REMOTE_CHIME_REQUEST_THREE_SHORT" 2 "REMOTE_CHIME_REQUEST_TWO_SHORT" 1 "REMOTE_CHIME_REQUEST_ONE_SHORT" 0 "REMOTE_CHIME_REQUEST_NONE" ;
VAL_ 322 VCLEFT_liftgatePhysicalChimeRequ 4 "REMOTE_CHIME_REQUEST_ONE_LONG" 3 "REMOTE_CHIME_REQUEST_THREE_SHORT" 2 "REMOTE_CHIME_REQUEST_TWO_SHORT" 1 "REMOTE_CHIME_REQUEST_ONE_SHORT" 0 "REMOTE_CHIME_REQUEST_NONE" ;
VAL_ 322 VCLEFT_liftgateStaticStrutMode 5 "PLG_STATIC_STRUT_MODE_SLAM_BRAKE" 4 "PLG_STATIC_STRUT_MODE_OPEN_COAST" 3 "PLG_STATIC_STRUT_MODE_CLOSE_COAST" 2 "PLG_STATIC_STRUT_MODE_BRAKE_HOLD" 1 "PLG_STATIC_STRUT_MODE_OFF_COAST" 0 "PLG_STATIC_STRUT_MODE_UNKNOWN_SNA" ;
VAL_ 322 VCLEFT_liftgateRequestSource 9 "PLG_REQUEST_SOURCE_DAS" 8 "PLG_REQUEST_SOURCE_EMERG_RELEASE" 7 "PLG_REQUEST_SOURCE_UDS" 6 "PLG_REQUEST_SOURCE_PARTY" 5 "PLG_REQUEST_SOURCE_VCSEC_COMMAND" 4 "PLG_REQUEST_SOURCE_KEY_TRUNK_BUTTON" 3 "PLG_REQUEST_SOURCE_SHUTFACE" 2 "PLG_REQUEST_SOURCE_EXTERIOR" 1 "PLG_REQUEST_SOURCE_MCU_SWITCH" 0 "PLG_REQUEST_SOURCE_NONE" ;
VAL_ 322 VCLEFT_liftgateGeofenceState 3 "PLG_GEOFENCE_STATE_WAITING_TO_STOP" 2 "PLG_GEOFENCE_STATE_SETTING_HEIGHT" 1 "PLG_GEOFENCE_STATE_WAITING_TO_TRIGGER" 0 "PLG_GEOFENCE_STATE_INIT" ;
VAL_ 322 VCLEFT_liftgateLatchRequest 4 "LATCH_REQUEST_RESET" 3 "LATCH_REQUEST_FORCE_RELEASE" 2 "LATCH_REQUEST_RELEASE_V2" 1 "LATCH_REQUEST_CINCH" 0 "LATCH_REQUEST_NONE" ;
VAL_ 994 VCLEFT_brakeLightStatus 3 "LIGHT_SNA" 2 "LIGHT_FAULT" 1 "LIGHT_ON" 0 "LIGHT_OFF" ;
VAL_ 994 VCLEFT_tailLightStatus 3 "LIGHT_SNA" 2 "LIGHT_FAULT" 1 "LIGHT_ON" 0 "LIGHT_OFF" ;
VAL_ 994 VCLEFT_turnSignalStatus 3 "LIGHT_SNA" 2 "LIGHT_FAULT" 1 "LIGHT_ON" 0 "LIGHT_OFF" ;
VAL_ 994 VCLEFT_FLMapLightStatus 3 "LIGHT_SNA" 2 "LIGHT_FAULT" 1 "LIGHT_ON" 0 "LIGHT_OFF" ;
VAL_ 994 VCLEFT_FRMapLightStatus 3 "LIGHT_SNA" 2 "LIGHT_FAULT" 1 "LIGHT_ON" 0 "LIGHT_OFF" ;
VAL_ 994 VCLEFT_RLMapLightStatus 3 "LIGHT_SNA" 2 "LIGHT_FAULT" 1 "LIGHT_ON" 0 "LIGHT_OFF" ;
VAL_ 994 VCLEFT_RRMapLightStatus 3 "LIGHT_SNA" 2 "LIGHT_FAULT" 1 "LIGHT_ON" 0 "LIGHT_OFF" ;
VAL_ 994 VCLEFT_leftTurnTrailerLightStatu 3 "LIGHT_SNA" 2 "LIGHT_FAULT" 1 "LIGHT_ON" 0 "LIGHT_OFF" ;
VAL_ 994 VCLEFT_rightTrnTrailerLightStatu 3 "LIGHT_SNA" 2 "LIGHT_FAULT" 1 "LIGHT_ON" 0 "LIGHT_OFF" ;
VAL_ 994 VCLEFT_brakeTrailerLightStatus 3 "LIGHT_SNA" 2 "LIGHT_FAULT" 1 "LIGHT_ON" 0 "LIGHT_OFF" ;
VAL_ 994 VCLEFT_tailTrailerLightStatus 3 "LIGHT_SNA" 2 "LIGHT_FAULT" 1 "LIGHT_ON" 0 "LIGHT_OFF" ;
VAL_ 994 VCLEFT_fogTrailerLightStatus 3 "LIGHT_SNA" 2 "LIGHT_FAULT" 1 "LIGHT_ON" 0 "LIGHT_OFF" ;
VAL_ 994 VCLEFT_frontRideHeight -128 "SNA" ;
VAL_ 994 VCLEFT_rearRideHeight -128 "SNA" ;
VAL_ 994 VCLEFT_trailerDetected 3 "TRAILER_LIGHT_DETECTION_NOT_DETECTED" 2 "TRAILER_LIGHT_DETECTION_DETECTED" 1 "TRAILER_LIGHT_DETECTION_FAULT" 0 "TRAILER_LIGHT_DETECTION_SNA" ;
VAL_ 994 VCLEFT_reverseTrailerLightStatus 3 "LIGHT_SNA" 2 "LIGHT_FAULT" 1 "LIGHT_ON" 0 "LIGHT_OFF" ;
VAL_ 994 VCLEFT_reverseLightStatus 3 "LIGHT_SNA" 2 "LIGHT_FAULT" 1 "LIGHT_ON" 0 "LIGHT_OFF" ;
VAL_ 1802 VCLEFT_logging0point1HzIndex 1 "END" 0 "MISC" ;
VAL_ 1802 VCLEFT_leftBrakeTailLightCurrent 511 "SNA" ;
VAL_ 1802 VCLEFT_leftBrakeTailLightCu_0001 4 "FALLING_EDGE_TRANSIENT" 3 "STEADY_STATE_ON" 2 "RISING_EDGE_TRANSIENT" 1 "STEADY_STATE_OFF" 0 "SNA" ;
VAL_ 1802 VCLEFT_leftRearTurnLightCurrent 511 "SNA" ;
VAL_ 1802 VCLEFT_leftRearTurnLightCurrentS 4 "FALLING_EDGE_TRANSIENT" 3 "STEADY_STATE_ON" 2 "RISING_EDGE_TRANSIENT" 1 "STEADY_STATE_OFF" 0 "SNA" ;
VAL_ 1802 VCLEFT_phoneTemperatureFL -128 "SNA" ;
VAL_ 649 VCLEFT_logging10HzIndex 1 "END" 0 "HVAC_VARS" ;
VAL_ 649 VCLEFT_hvacBlowerRs 255 "SNA" ;
VAL_ 649 VCLEFT_hvacBlowerIPhase0 127 "SNA" ;
VAL_ 649 VCLEFT_hvacBlowerIPhase1 127 "SNA" ;
VAL_ 649 VCLEFT_hvacBlowerIPhase2 127 "SNA" ;
VAL_ 649 VCLEFT_hvacBlower_IO_CBC_Status 1 "RX" 0 "IDLE" ;
VAL_ 649 VCLEFT_hvacBlowerCBCEstState 14 "COUNT" 13 "ONLINE" 12 "MOTOR_IDENTIFIED" 11 "ROTOR_RESISTANCE" 10 "INDUCTANCE_EST" 9 "LOCKROTOR" 8 "RAMPDOWN" 7 "RATEDFLUX" 6 "RATEDFLUX_OL" 5 "IDRATED" 4 "RAMPUP" 3 "RS" 2 "ROVERL" 1 "IDLE" 0 "ERROR" ;
VAL_ 649 VCLEFT_hvacBlowerCBCCtrlState 4 "COUNT" 3 "ONLINE" 2 "OFFLINE" 1 "IDLE" 0 "ERROR" ;
VAL_ 649 VCLEFT_hvacBlowerITerm 127 "SNA" ;
VAL_ 936 VCLEFT_logging1HzIndex 5 "END" 4 "CURRENT_LOGGING" 3 "BODY_CONTROLS_LOGGING" 2 "HSD_CURRENTS_2" 1 "HSD_CURRENTS_1" 0 "MISC" ;
VAL_ 936 VCLEFT_tohcPCBATemperature 255 "SNA" ;
VAL_ 936 VCLEFT_swcResistance 127 "SNA" ;
VAL_ 727 VCLEFT_pitchEstimateFusionState 7 "PITCHESTIMATION_STATE_UNKNOWN" 4 "PITCHESTIMATION_STATE_CALCULATE" 3 "PITCHESTIMATION_STATE_WAIT_FOR_STARTUP" 2 "PITCHESTIMATION_STATE_WAIT_FOR_SPEED" 1 "PITCHESTIMATION_STATE_WAIT_FOR_SIGNALS_AND_DOORS" 0 "PITCHESTIMATION_STATE_INIT" ;
VAL_ 727 VCLEFT_pitchEstimateStateTransit 26 "PITCHESTIMATION_DELTA_LIVE_THEN_VALIDITIES_NOT_GOOD" 25 "PITCHESTIMATION_DELTA_LIVE_THEN_FUSION_INIT" 24 "PITCHESTIMATION_DELTA_LIVE_THEN_LIVE_AX" 23 "PITCHESTIMATION_DELTA_LIVE_THEN_SPEED_AND_EPB_NOT_PARKED" 22 "PITCHESTIMATION_DELTA_LIVE_THEN_NVRAM_DISALLOW" 21 "PITCHESTIMATION_DELTA_LIVE_THEN_TRANSPORT" 20 "PITCHESTIMATION_DELTA_LIVE_THEN_DOORS_CLOSED_LONG_TIME" 19 "PITCHESTIMATION_DELTA_LIVE_THEN_EPB_RELEASING" 18 "PITCHESTIMATION_CARRYOVER_THEN_LIVE_AX" 17 "PITCHESTIMATION_CARRYOVER_THEN_FUSION_READY" 16 "PITCHESTIMATION_CARRYOVER_THEN_VALIDITIES_NOT_GOOD" 15 "PITCHESTIMATION_CARRYOVER_THEN_FUSION_INIT" 14 "PITCHESTIMATION_FROZEN_THEN_LIVE_AX" 13 "PITCHESTIMATION_FROZEN_THEN_FUSION_READY" 12 "PITCHESTIMATION_FROZEN_THEN_VALIDITIES_NOT_GOOD" 11 "PITCHESTIMATION_FROZEN_THEN_FUSION_INIT" 10 "PITCHESTIMATION_FUSION_THEN_LIVE_AX" 9 "PITCHESTIMATION_FUSION_THEN_FUSION_INIT" 8 "PITCHESTIMATION_UNAVAILABLE_THEN_LIVE_AX" 7 "PITCHESTIMATION_UNAVAILABLE_THEN_FUSION_READY" 6 "PITCHESTIMATION_UNAVAILABLE_THEN_DELTA_LIVE_READY" 5 "PITCHESTIMATION_UNAVAILABLE_THEN_SPEED_AND_EPB_NOT_PARKED" 4 "PITCHESTIMATION_UNAVAILABLE_THEN_NVRAM_DISALLOW" 3 "PITCHESTIMATION_UNAVAILABLE_THEN_TRANSPORT" 2 "PITCHESTIMATION_LIVE_AX_THEN_VALIDITIES_NOT_GOOD" 1 "PITCHESTIMATION_LIVE_AX_THEN_NO_LONGER_LIVE_AX" 0 "PITCHESTIMATION_INVALID_STATE_TRANSITION_DEFAULT" ;
VAL_ 727 VCLEFT_pitchEstimateArbitratedSt 7 "PITCHESTIMATION_ARBITRATEDSTATE_UNKNOWN" 5 "PITCHESTIMATION_ARBITRATEDSTATE_LIVE_AX_NO_DELTA" 4 "PITCHESTIMATION_ARBITRATEDSTATE_CYCLE_DELTA_FROZEN" 3 "PITCHESTIMATION_ARBITRATEDSTATE_CYCLE_DELTA_CARRYOVER" 2 "PITCHESTIMATION_ARBITRATEDSTATE_CYCLE_DELTA_LIVE" 1 "PITCHESTIMATION_ARBITRATEDSTATE_FUSION" 0 "PITCHESTIMATION_ARBITRATEDSTATE_UNAVAILABLE" ;
VAL_ 727 VCLEFT_pitchEstimate -512 "SNA" ;
VAL_ 1860 VCLEFT_systemRecallStatus 3 "RECALL_INTERRUPTED" 2 "RECALL_COMPLETE" 1 "RECALL_IN_PROGRESS" 0 "RECALL_SNA" ;
VAL_ 1860 VCLEFT_seatRecallStatus 3 "RECALL_INTERRUPTED" 2 "RECALL_COMPLETE" 1 "RECALL_IN_PROGRESS" 0 "RECALL_SNA" ;
VAL_ 1860 VCLEFT_columnRecallStatus 3 "RECALL_INTERRUPTED" 2 "RECALL_COMPLETE" 1 "RECALL_IN_PROGRESS" 0 "RECALL_SNA" ;
VAL_ 1860 VCLEFT_mirrorRecallStatus 3 "RECALL_INTERRUPTED" 2 "RECALL_COMPLETE" 1 "RECALL_IN_PROGRESS" 0 "RECALL_SNA" ;
